VERSION "dbc-export 1 2025.20.8"

NS_ :

BS_:

BU_: BB BMS GTW IDB PM TCU UI UIS

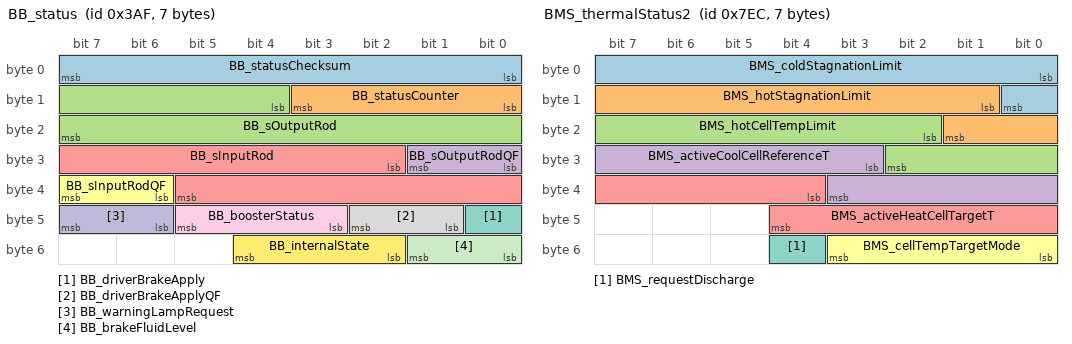
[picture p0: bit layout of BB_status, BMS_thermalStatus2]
BO_ 943 BB_status: 7 BB
 SG_ BB_statusChecksum : 0|8@1+ (1,0) [0|255] "" Vector__XXX
 SG_ BB_statusCounter : 8|4@1+ (1,0) [0|15] "" Vector__XXX
 SG_ BB_sOutputRod : 12|12@1+ (0.015625,-5) [-5|47] "mm" Vector__XXX
 SG_ BB_sOutputRodQF : 24|2@1+ (1,0) [0|3] "" Vector__XXX
 SG_ BB_sInputRod : 26|12@1+ (0.015625,-5) [-5|47] "mm" Vector__XXX
 SG_ BB_sInputRodQF : 38|2@1+ (1,0) [0|3] "" Vector__XXX
 SG_ BB_driverBrakeApply : 40|1@1+ (1,0) [0|1] "" Vector__XXX
 SG_ BB_driverBrakeApplyQF : 41|2@1+ (1,0) [0|3] "" Vector__XXX
 SG_ BB_boosterStatus : 43|3@1+ (1,0) [0|7] "" Vector__XXX
 SG_ BB_warningLampRequest : 46|2@1+ (1,0) [0|3] "" Vector__XXX
 SG_ BB_brakeFluidLevel : 48|2@1+ (1,0) [0|3] "" Vector__XXX
 SG_ BB_internalState : 50|3@1+ (1,0) [0|7] "" Vector__XXX

BO_ 2029 BMS_debugInfo_10Hz: 8 BMS
 SG_ BMS_10HzDebug_Id M : 0|6@1+ (1,0) [0|63] "" Vector__XXX
 SG_ BMS_activeCoolCellTargetT m33 : 6|9@1+ (0.25,-25) [-25|100] "DegC" Vector__XXX
 SG_ BMS_passiveCoolCellTargetT m33 : 15|9@1+ (0.25,-25) [-25|100] "DegC" Vector__XXX

BO_ 2028 BMS_thermalStatus2: 7 BMS
 SG_ BMS_coldStagnationLimit : 0|9@1+ (0.25,-25) [-25|100] "DegC" Vector__XXX
 SG_ BMS_hotStagnationLimit : 9|9@1+ (0.25,-25) [-25|100] "DegC" Vector__XXX
 SG_ BMS_hotCellTempLimit : 18|9@1+ (0.25,-25) [-25|100] "DegC" Vector__XXX
 SG_ BMS_activeCoolCellReferenceT : 27|9@1+ (0.25,-25) [-25|100] "DegC" Vector__XXX
 SG_ BMS_activeHeatCellTargetT : 36|9@1+ (0.25,-25) [-25|100] "DegC" Vector__XXX
 SG_ BMS_cellTempTargetMode : 48|4@1+ (1,0) [0|15] "" Vector__XXX
 SG_ BMS_requestDischarge : 52|1@1+ (1,0) [0|1] "" Vector__XXX

BO_ 888 GTW_ECall: 1 GTW
 SG_ GTW_GTW_SOS_ECALL_RQST : 0|1@1+ (1,0) [0|1] "" Vector__XXX
 SG_ GTW_LTE_ECALL_LOCK : 1|1@1+ (1,0) [0|1] "" Vector__XXX

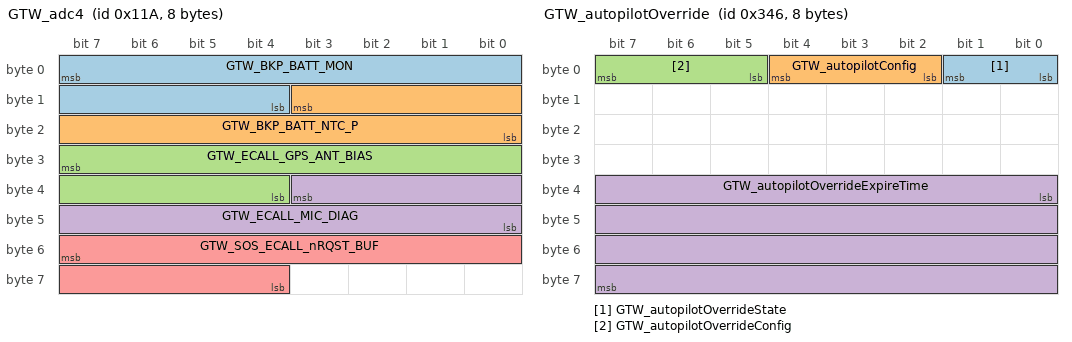
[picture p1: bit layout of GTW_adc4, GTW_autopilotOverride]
BO_ 282 GTW_adc4: 8 GTW
 SG_ GTW_BKP_BATT_MON : 7|12@0+ (1,0) [0|4094] "mV" Vector__XXX
 SG_ GTW_BKP_BATT_NTC_P : 11|12@0+ (1,0) [0|4094] "mV" Vector__XXX
 SG_ GTW_ECALL_GPS_ANT_BIAS : 31|12@0+ (1,0) [0|4094] "mV" Vector__XXX
 SG_ GTW_ECALL_MIC_DIAG : 35|12@0+ (1,0) [0|4094] "mV" Vector__XXX
 SG_ GTW_SOS_ECALL_nRQST_BUF : 55|12@0+ (1,0) [0|4094] "mV" Vector__XXX

BO_ 838 GTW_autopilotOverride: 8 GTW
 SG_ GTW_autopilotOverrideState : 0|2@1+ (1,0) [0|3] "" Vector__XXX
 SG_ GTW_autopilotConfig : 2|3@1+ (1,0) [0|7] "" Vector__XXX
 SG_ GTW_autopilotOverrideConfig : 5|3@1+ (1,0) [0|7] "" Vector__XXX
 SG_ GTW_autopilotOverrideExpireTime : 32|32@1+ (1,0) [0|4294967295] "" Vector__XXX

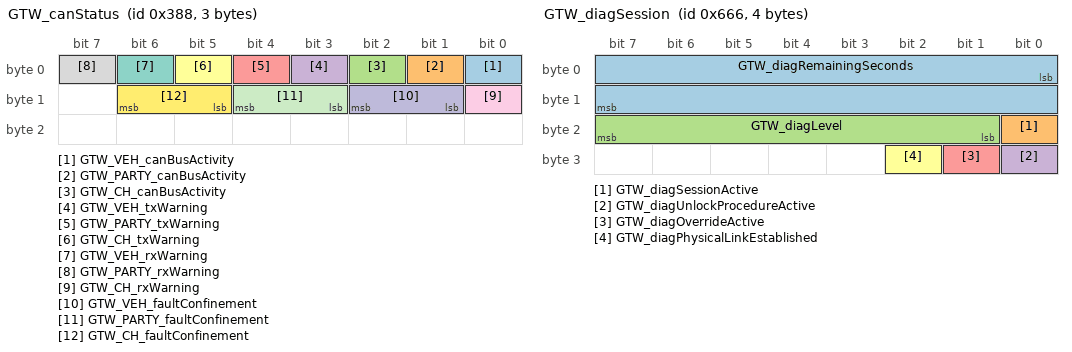
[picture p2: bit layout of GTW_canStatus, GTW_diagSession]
BO_ 904 GTW_canStatus: 3 GTW
 SG_ GTW_VEH_canBusActivity : 0|1@1+ (1,0) [0|1] "" Vector__XXX
 SG_ GTW_PARTY_canBusActivity : 1|1@1+ (1,0) [0|1] "" Vector__XXX
 SG_ GTW_CH_canBusActivity : 2|1@1+ (1,0) [0|1] "" Vector__XXX
 SG_ GTW_VEH_txWarning : 3|1@1+ (1,0) [0|1] "" Vector__XXX
 SG_ GTW_PARTY_txWarning : 4|1@1+ (1,0) [0|1] "" Vector__XXX
 SG_ GTW_CH_txWarning : 5|1@1+ (1,0) [0|1] "" Vector__XXX
 SG_ GTW_VEH_rxWarning : 6|1@1+ (1,0) [0|1] "" Vector__XXX
 SG_ GTW_PARTY_rxWarning : 7|1@1+ (1,0) [0|1] "" Vector__XXX
 SG_ GTW_CH_rxWarning : 8|1@1+ (1,0) [0|1] "" Vector__XXX
 SG_ GTW_VEH_faultConfinement : 9|2@1+ (1,0) [0|3] "" Vector__XXX
 SG_ GTW_PARTY_faultConfinement : 11|2@1+ (1,0) [0|3] "" Vector__XXX
 SG_ GTW_CH_faultConfinement : 13|2@1+ (1,0) [0|3] "" Vector__XXX

BO_ 2047 GTW_carConfig: 8 GTW
 SG_ GTW_carConfigMultiplexer M : 0|8@1+ (1,0) [0|255] "" Vector__XXX
 SG_ GTW_deliveryStatus m1 : 8|1@1+ (1,0) [0|1] "" Vector__XXX
 SG_ GTW_cabinPTCHeaterType m1 : 10|1@1+ (1,0) [0|1] "" Vector__XXX
 SG_ GTW_rightHandDrive m1 : 11|1@1+ (1,0) [0|1] "" Vector__XXX
 SG_ GTW_rearLightType m1 : 12|2@1+ (1,0) [0|3] "" Vector__XXX
 SG_ GTW_headlamps m1 : 14|2@1+ (1,0) [0|3] "" Vector__XXX
 SG_ GTW_country m1 : 16|16@1+ (1,0) [0|65535] "" Vector__XXX
 SG_ GTW_tireType m1 : 32|6@1+ (1,0) [0|63] "" Vector__XXX
 SG_ GTW_roofGlassType m1 : 38|2@1+ (1,0) [0|3] "" Vector__XXX
 SG_ GTW_dasHw m1 : 40|3@1+ (1,0) [3|5] "" Vector__XXX
 SG_ GTW_brakeHWType m1 : 43|5@1+ (1,0) [0|31] "" Vector__XXX
 SG_ GTW_restraintsHardwareType m1 : 48|8@1+ (1,0) [0|255] "" Vector__XXX
 SG_ GTW_drivetrainType m1 : 56|4@1+ (1,0) [0|4] "" Vector__XXX
 SG_ GTW_radarHeaterType m1 : 60|3@1+ (1,0) [0|5] "" Vector__XXX
 SG_ GTW_exteriorTrimType m2 : 8|1@1+ (1,0) [0|1] "" Vector__XXX
 SG_ GTW_frontSeatHeaters m2 : 9|1@1+ (1,0) [0|1] "" Vector__XXX
 SG_ GTW_rearSeatHeaters m2 : 10|1@1+ (1,0) [0|1] "" Vector__XXX
 SG_ GTW_eCallAntennaHW m2 : 12|1@1+ (1,0) [0|1] "" Vector__XXX
 SG_ GTW_homelinkType m2 : 13|1@1+ (1,0) [0|1] "" Vector__XXX
 SG_ GTW_vdcType m2 : 14|1@1+ (1,0) [0|1] "" Vector__XXX
 SG_ GTW_memoryMirrors m2 : 17|1@1+ (1,0) [0|1] "" Vector__XXX
 SG_ GTW_powerLiftgateType m2 : 18|2@1+ (1,0) [0|2] "" Vector__XXX
 SG_ GTW_lumbarECUType m2 : 20|4@1+ (1,0) [0|15] "" Vector__XXX
 SG_ GTW_rearSeatHeaterType m2 : 24|2@1+ (1,0) [0|3] "" Vector__XXX
 SG_ GTW_auxParkLamps m2 : 26|2@1+ (1,0) [0|3] "" Vector__XXX
 SG_ GTW_interiorCabinRadarType m2 : 28|1@1+ (1,0) [0|1] "" Vector__XXX
 SG_ GTW_hvacPanelVaneType m2 : 29|1@1+ (1,0) [0|1] "" Vector__XXX
 SG_ GTW_intakeAirFilterType m2 : 30|2@1+ (1,0) [0|2] "" Vector__XXX
 SG_ GTW_eBuckConfig m2 : 32|1@1+ (1,0) [0|1] "" Vector__XXX
 SG_ GTW_steeringHeaterEnabled m2 : 33|1@1+ (1,0) [0|1] "" Vector__XXX
 SG_ GTW_activeHighBeam m2 : 34|1@1+ (1,0) [0|1] "" Vector__XXX
 SG_ GTW_airbagCutoffSwitch m2 : 35|1@1+ (1,0) [0|1] "" Vector__XXX
 SG_ GTW_intrusionSensorType m2 : 36|1@1+ (1,0) [0|1] "" Vector__XXX
 SG_ GTW_spoilerType m2 : 37|1@1+ (1,0) [0|1] "" Vector__XXX
 SG_ GTW_rearFogLamps m2 : 39|1@1+ (1,0) [0|1] "" Vector__XXX
 SG_ GTW_roofType m2 : 40|1@1+ (1,0) [0|1] "" Vector__XXX
 SG_ GTW_thirdRowSeatType m2 : 41|1@1+ (1,0) [0|1] "" Vector__XXX
 SG_ GTW_autopilot m2 : 42|3@1+ (1,0) [0|7] "" Vector__XXX
 SG_ GTW_superchargingAccess m2 : 45|2@1+ (1,0) [0|3] "" Vector__XXX
 SG_ GTW_exteriorColor m2 : 48|5@1+ (1,0) [0|31] "" Vector__XXX
 SG_ GTW_pedestrianWarningSound m2 : 53|2@1+ (1,0) [0|3] "" Vector__XXX
 SG_ GTW_steeringColumnUJointType m2 : 55|1@1+ (1,0) [0|1] "" Vector__XXX
 SG_ GTW_bPillarNFCParam m2 : 56|1@1+ (1,0) [0|1] "" Vector__XXX
 SG_ GTW_interiorLighting m2 : 57|3@1+ (1,0) [0|7] "" Vector__XXX
 SG_ GTW_headlightLevelerType m2 : 60|2@1+ (1,0) [0|3] "" Vector__XXX
 SG_ GTW_numberHVILNodes m2 : 62|2@1+ (1,0) [0|3] "" Vector__XXX
 SG_ GTW_mapRegion m3 : 8|4@1+ (1,0) [0|15] "" Vector__XXX
 SG_ GTW_performancePackage m3 : 12|3@1+ (1,0) [0|7] "" Vector__XXX
 SG_ GTW_chassisType m3 : 18|4@1+ (1,0) [0|15] "" Vector__XXX
 SG_ GTW_airSuspension m3 : 22|2@1+ (1,0) [0|3] "" Vector__XXX
 SG_ GTW_centerConsoleControllerType m3 : 24|2@1+ (1,0) [0|3] "" Vector__XXX
 SG_ GTW_autopilotCameraType m3 : 26|1@1+ (1,0) [0|1] "" Vector__XXX
 SG_ GTW_connectivityPackage m3 : 27|1@1+ (1,0) [0|1] "" Vector__XXX
 SG_ GTW_plcSupportType m3 : 28|2@1+ (1,0) [0|3] "" Vector__XXX
 SG_ GTW_packEnergy m3 : 32|5@1+ (1,0) [0|31] "" Vector__XXX
 SG_ GTW_frontSeatReclinerHardware m3 : 37|2@1+ (1,0) [0|3] "" Vector__XXX
 SG_ GTW_brakeLineSwitchType m3 : 39|1@1+ (1,0) [0|1] "" Vector__XXX
 SG_ GTW_softRange m3 : 42|3@1+ (1,0) [0|7] "" Vector__XXX
 SG_ GTW_refrigerantType m3 : 45|2@1+ (1,0) [0|3] "" Vector__XXX
 SG_ GTW_wheelType m3 : 48|7@1+ (1,0) [0|127] "" Vector__XXX
 SG_ GTW_brakeActuationType m3 : 57|3@1+ (1,0) [0|4] "" Vector__XXX
 SG_ GTW_secondRowSeatType m3 : 60|3@1+ (1,0) [0|7] "" Vector__XXX
 SG_ GTW_secondRowSeatMotorType m3 : 63|1@1+ (1,0) [0|1] "" Vector__XXX
 SG_ GTW_birthday m4 : 8|32@1+ (1,0) [0|4294967295] "" Vector__XXX
 SG_ GTW_eCallEnabled m4 : 40|2@1+ (1,0) [0|3] "" Vector__XXX
 SG_ GTW_parkAssistECUType m4 : 42|2@1+ (1,0) [0|3] "" Vector__XXX
 SG_ GTW_passengerAirbagType m4 : 44|2@1+ (1,0) [0|3] "" Vector__XXX
 SG_ GTW_forwardRadarHw m4 : 46|2@1+ (1,0) [0|2] "" Vector__XXX
 SG_ GTW_frontSeatType m4 : 48|4@1+ (1,0) [0|15] "" Vector__XXX
 SG_ GTW_secondRowDisplayType m4 : 52|1@1+ (1,0) [0|1] "" Vector__XXX
 SG_ GTW_wirelessPhoneChargerType m4 : 53|2@1+ (1,0) [0|3] "" Vector__XXX
 SG_ GTW_ethernetTunerType m4 : 55|2@1+ (1,0) [0|3] "" Vector__XXX
 SG_ GTW_interiorTrimType m4 : 60|4@1+ (1,0) [0|15] "" Vector__XXX
 SG_ GTW_gloveboxUSBType m5 : 8|2@1+ (1,0) [0|3] "" Vector__XXX
 SG_ GTW_coolantPumpType m5 : 10|3@1+ (1,0) [0|7] "" Vector__XXX
 SG_ GTW_epblHwType m5 : 13|4@1+ (1,0) [0|15] "" Vector__XXX
 SG_ GTW_epbrHwType m5 : 17|4@1+ (1,0) [0|15] "" Vector__XXX
 SG_ GTW_blowerMotorType m5 : 21|2@1+ (1,0) [0|3] "" Vector__XXX
 SG_ GTW_frontUsbHubType m5 : 27|3@1+ (1,0) [0|5] "" Vector__XXX
 SG_ GTW_superManifoldType m5 : 30|2@1+ (1,0) [0|3] "" Vector__XXX
 SG_ GTW_rcmLocation m5 : 32|1@1+ (1,0) [0|1] "" Vector__XXX
 SG_ GTW_interiorCamFanType m5 : 33|2@1+ (1,0) [0|3] "" Vector__XXX
 SG_ GTW_sirenType m5 : 37|1@1+ (1,0) [0|1] "" Vector__XXX
 SG_ GTW_hornType m5 : 38|1@1+ (1,0) [0|1] "" Vector__XXX
 SG_ GTW_badgingVersion m5 : 40|1@1+ (1,0) [0|1] "" Vector__XXX
 SG_ GTW_steeringColumnMotorType m5 : 42|2@1+ (1,0) [0|3] "" Vector__XXX
 SG_ GTW_refrigACLineType m5 : 48|2@1+ (1,0) [0|3] "" Vector__XXX
 SG_ GTW_refrigFilterType m5 : 50|2@1+ (1,0) [0|3] "" Vector__XXX
 SG_ GTW_diBurnInType m5 : 52|1@1+ (1,0) [0|1] "" Vector__XXX
 SG_ GTW_specialBadgingType m5 : 53|2@1+ (1,0) [0|3] "" Vector__XXX
 SG_ GTW_chassisSubType m5 : 55|2@1+ (1,0) [0|3] "" Vector__XXX
 SG_ GTW_frontSeatVentilationType m5 : 57|1@1+ (1,0) [0|1] "" Vector__XXX
 SG_ GTW_towPackage m5 : 58|2@1+ (1,0) [0|3] "" Vector__XXX
 SG_ GTW_refrigLccType m5 : 60|1@1+ (1,0) [0|1] "" Vector__XXX
 SG_ GTW_caliperColorType m5 : 62|2@1+ (1,0) [0|3] "" Vector__XXX
 SG_ GTW_wiperMotorType m6 : 9|1@1+ (1,0) [0|1] "" Vector__XXX
 SG_ GTW_frontOverheadConsoleType m6 : 10|2@1+ (1,0) [0|3] "" Vector__XXX
 SG_ GTW_shifterType m6 : 12|1@1+ (1,0) [0|1] "" Vector__XXX
 SG_ GTW_compressorType m6 : 13|4@1+ (1,0) [0|15] "" Vector__XXX
 SG_ GTW_twelveVBatteryType m6 : 17|3@1+ (1,0) [0|7] "" Vector__XXX
 SG_ GTW_efuseSWConfig m6 : 20|3@1+ (1,0) [0|7] "" Vector__XXX
 SG_ GTW_tollCollectionModuleType m6 : 23|1@1+ (1,0) [0|1] "" Vector__XXX
 SG_ GTW_bleEndpointUpdateMethod m6 : 24|1@1+ (1,0) [0|1] "" Vector__XXX
 SG_ GTW_steeringWheelControllerType m6 : 25|3@1+ (1,0) [0|7] "" Vector__XXX
 SG_ GTW_frontSeatVentilationEnabled m6 : 28|1@1+ (1,0) [0|1] "" Vector__XXX
 SG_ GTW_gloveboxActuatorType m6 : 29|2@1+ (1,0) [0|3] "" Vector__XXX
 SG_ GTW_epasType m6 : 32|4@1+ (1,0) [0|11] "" Vector__XXX
 SG_ GTW_homologationRegionOverride m6 : 36|2@1+ (1,0) [0|3] "" Vector__XXX
 SG_ GTW_windowCommandsPermissionType m6 : 38|2@1+ (1,0) [0|3] "" Vector__XXX
 SG_ GTW_rgbInteriorLightingEnabled m6 : 43|2@1+ (1,0) [0|3] "" Vector__XXX
 SG_ GTW_windshieldWiperHeaterType m6 : 45|1@1+ (1,0) [0|1] "" Vector__XXX
 SG_ GTW_driveInterfaceType m6 : 47|1@1+ (1,0) [0|1] "" Vector__XXX
 SG_ GTW_efficiencyPackage m6 : 49|6@1+ (1,0) [0|63] "" Vector__XXX
 SG_ GTW_visorLightType m6 : 55|1@1+ (1,0) [0|1] "" Vector__XXX
 SG_ GTW_gnssAntennaType m6 : 58|2@1+ (1,0) [0|3] "" Vector__XXX
 SG_ GTW_frontSeatHeatersEnabled m6 : 62|1@1+ (1,0) [0|1] "" Vector__XXX
 SG_ GTW_windshieldWiperHeaterEnabled m6 : 63|1@1+ (1,0) [0|1] "" Vector__XXX
 SG_ GTW_tcuType m7 : 8|1@1+ (1,0) [0|1] "" Vector__XXX
 SG_ GTW_fasciaType m7 : 9|4@1+ (1,0) [0|15] "" Vector__XXX
 SG_ GTW_powerSteeringColumn m7 : 13|1@1+ (1,0) [0|1] "" Vector__XXX
 SG_ GTW_frontSeatHeaterType m7 : 14|1@1+ (1,0) [0|1] "" Vector__XXX
 SG_ GTW_softPerformanceLimit m7 : 15|4@1+ (1,0) [0|15] "" Vector__XXX
 SG_ GTW_alcoholInterlockType m7 : 22|1@1+ (1,0) [0|1] "" Vector__XXX
 SG_ GTW_immersiveAudio m7 : 23|2@1+ (1,0) [0|3] "" Vector__XXX
 SG_ GTW_passengerOccupancySensorType m7 : 26|3@1+ (1,0) [0|7] "" Vector__XXX
 SG_ GTW_packPerformanceDeviation m7 : 30|3@1+ (1,0) [0|7] "" Vector__XXX
 SG_ GTW_frontFogLamps m7 : 35|1@1+ (1,0) [0|1] "" Vector__XXX
 SG_ GTW_driverOccupancySensorType m7 : 36|1@1+ (1,0) [0|1] "" Vector__XXX
 SG_ GTW_audioType m7 : 37|3@1+ (1,0) [0|7] "" Vector__XXX
 SG_ GTW_occupancyClassificationFeatu m7 : 42|1@1+ (1,0) [0|1] "" Vector__XXX
 SG_ GTW_domeLightType m7 : 47|2@1+ (1,0) [0|3] "" Vector__XXX
 SG_ GTW_tpmsType m7 : 49|2@1+ (1,0) [0|3] "" Vector__XXX
 SG_ GTW_authenticationEndpointLayout m7 : 52|3@1+ (1,0) [0|6] "" Vector__XXX
 SG_ GTW_socSleepOverride m7 : 57|2@1+ (1,0) [0|3] "" Vector__XXX
 SG_ GTW_r79BehaviorOverride m7 : 59|1@1+ (1,0) [0|1] "" Vector__XXX
 SG_ GTW_steeringHeaterType m7 : 60|3@1+ (1,0) [0|7] "" Vector__XXX
 SG_ GTW_sohRegulatoryStatus m8 : 10|1@1+ (1,0) [0|1] "" Vector__XXX
 SG_ GTW_m3yBusArchitecture m8 : 17|2@1+ (1,0) [0|3] "" Vector__XXX
 SG_ GTW_blindSpotIndicatorLightType m8 : 20|1@1+ (1,0) [0|1] "" Vector__XXX
 SG_ GTW_hvacCaseDoorType m8 : 28|1@1+ (1,0) [0|1] "" Vector__XXX
 SG_ GTW_rduCableType m8 : 31|1@1+ (1,0) [0|1] "" Vector__XXX
 SG_ GTW_interiorCameraType m8 : 39|2@1+ (1,0) [0|2] "" Vector__XXX
 SG_ GTW_frontFasciaCameraType m8 : 41|2@1+ (1,0) [0|3] "" Vector__XXX

BO_ 1638 GTW_diagSession: 4 GTW
 SG_ GTW_diagRemainingSeconds : 0|16@1+ (1,0) [0|65535] "seconds" Vector__XXX
 SG_ GTW_diagSessionActive : 16|1@1+ (1,0) [0|1] "" Vector__XXX
 SG_ GTW_diagLevel : 17|7@1+ (1,0) [0|127] "" Vector__XXX
 SG_ GTW_diagUnlockProcedureActive : 24|1@1+ (1,0) [0|1] "" Vector__XXX
 SG_ GTW_diagOverrideActive : 25|1@1+ (1,0) [0|1] "" Vector__XXX
 SG_ GTW_diagPhysicalLinkEstablished : 26|1@1+ (1,0) [0|1] "" Vector__XXX

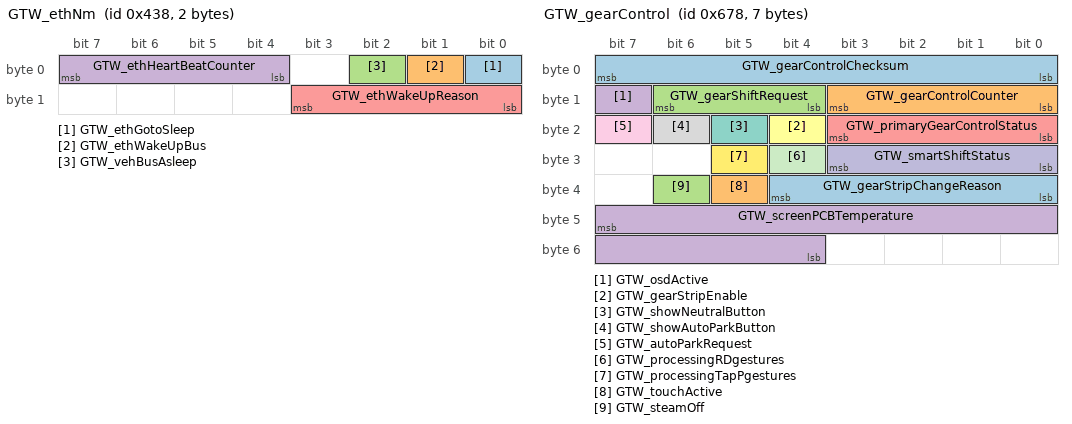
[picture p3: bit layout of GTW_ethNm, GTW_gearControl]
BO_ 1080 GTW_ethNm: 2 GTW
 SG_ GTW_ethGotoSleep : 0|1@1+ (1,0) [0|1] "" Vector__XXX
 SG_ GTW_ethWakeUpBus : 1|1@1+ (1,0) [0|1] "" Vector__XXX
 SG_ GTW_vehBusAsleep : 2|1@1+ (1,0) [0|1] "" Vector__XXX
 SG_ GTW_ethHeartBeatCounter : 4|4@1+ (1,0) [0|15] "" Vector__XXX
 SG_ GTW_ethWakeUpReason : 8|4@1+ (1,0) [0|15] "" Vector__XXX

BO_ 1656 GTW_gearControl: 7 GTW
 SG_ GTW_gearControlChecksum : 0|8@1+ (1,0) [0|255] "" Vector__XXX
 SG_ GTW_gearControlCounter : 8|4@1+ (1,0) [0|15] "" Vector__XXX
 SG_ GTW_gearShiftRequest : 12|3@1+ (1,0) [1|7] "" Vector__XXX
 SG_ GTW_osdActive : 15|1@1+ (1,0) [0|1] "" Vector__XXX
 SG_ GTW_primaryGearControlStatus : 16|4@1+ (1,0) [0|15] "" Vector__XXX
 SG_ GTW_gearStripEnable : 20|1@1+ (1,0) [0|1] "" Vector__XXX
 SG_ GTW_showNeutralButton : 21|1@1+ (1,0) [0|1] "" Vector__XXX
 SG_ GTW_showAutoParkButton : 22|1@1+ (1,0) [0|1] "" Vector__XXX
 SG_ GTW_autoParkRequest : 23|1@1+ (1,0) [0|1] "" Vector__XXX
 SG_ GTW_smartShiftStatus : 24|4@1+ (1,0) [1|15] "" Vector__XXX
 SG_ GTW_processingRDgestures : 28|1@1+ (1,0) [0|1] "" Vector__XXX
 SG_ GTW_processingTapPgestures : 29|1@1+ (1,0) [0|1] "" Vector__XXX
 SG_ GTW_gearStripChangeReason : 32|5@1+ (1,0) [1|31] "" Vector__XXX
 SG_ GTW_touchActive : 37|1@1+ (1,0) [0|1] "" Vector__XXX
 SG_ GTW_steamOff : 38|1@1+ (1,0) [0|1] "" Vector__XXX
 SG_ GTW_screenPCBTemperature : 47|12@0- (0.0625,0) [-128|127.875] "degC" Vector__XXX

BO_ 2033 GTW_hrl: 7 GTW
 SG_ GTW_hrlIndex M : 0|2@1+ (1,0) [0|3] "" Vector__XXX
 SG_ GTW_hrlState m2 : 2|1@1+ (1,0) [0|1] "" Vector__XXX
 SG_ GTW_hrlTriggerDuration m2 : 15|16@0+ (1,0) [0|65535] "seconds" Vector__XXX
 SG_ GTW_hrlTriggerType m2 : 24|4@1+ (1,0) [0|15] "" Vector__XXX
 SG_ GTW_hrlTriggerId m2 : 39|16@0+ (1,0) [0|65535] "" Vector__XXX
 SG_ GTW_hrlTriggerBus m2 : 53|3@1+ (1,0) [0|7] "" Vector__XXX

BO_ 60 GTW_info: 8 GTW
 SG_ GTW_infoIndex M : 0|8@1+ (1,0) [0|255] "" Vector__XXX
 SG_ GTW_buildType m10 : 8|3@1+ (1,0) [0|7] "" Vector__XXX
 SG_ GTW_hardwareId m10 : 32|16@1+ (1,0) [0|65535] "" Vector__XXX
 SG_ GTW_platformType m13 : 8|8@1+ (1,0) [0|255] "" Vector__XXX
 SG_ GTW_appCrc m13 : 32|32@1+ (1,0) [0|4294967295] "" Vector__XXX
 SG_ GTW_applicationGitHash m17 : 8|56@1+ (1,0) [0|7.20575940379e+16] "" Vector__XXX
 SG_ GTW_bootGitHash m18 : 8|56@1+ (1,0) [0|7.20575940379e+16] "" Vector__XXX

BO_ 1370 GTW_mismatchFault: 8 GTW
 SG_ GTW_mismatchFaultIndex M : 0|3@1+ (1,0) [0|7] "" Vector__XXX
 SG_ GTW_mismatchFaultChecksum : 3|8@1+ (1,0) [0|255] "" Vector__XXX
 SG_ GTW_mismatchFaultCounter : 11|4@1+ (1,0) [0|15] "" Vector__XXX
 SG_ GTW_GTWmismatchFault m1 : 15|1@1+ (1,0) [0|1] "" Vector__XXX
 SG_ GTW_BMSmismatchFault m1 : 16|1@1+ (1,0) [0|1] "" Vector__XXX
 SG_ GTW_APSmismatchFault m1 : 17|1@1+ (1,0) [0|1] "" Vector__XXX
 SG_ GTW_BLEEPCENTERmismatchFault m1 : 18|1@1+ (1,0) [0|1] "" Vector__XXX
 SG_ GTW_BLEEPLEFTmismatchFault m1 : 19|1@1+ (1,0) [0|1] "" Vector__XXX
 SG_ GTW_BLEEPREARmismatchFault m1 : 20|1@1+ (1,0) [0|1] "" Vector__XXX
 SG_ GTW_BLEEPRIGHTmismatchFault m1 : 21|1@1+ (1,0) [0|1] "" Vector__XXX
 SG_ GTW_CBCmismatchFault m1 : 22|1@1+ (1,0) [0|1] "" Vector__XXX
 SG_ GTW_CMPmismatchFault m1 : 23|1@1+ (1,0) [0|1] "" Vector__XXX
 SG_ GTW_CPmismatchFault m1 : 24|1@1+ (1,0) [0|1] "" Vector__XXX
 SG_ GTW_DIFmismatchFault m1 : 25|1@1+ (1,0) [0|1] "" Vector__XXX
 SG_ GTW_DIRmismatchFault m1 : 26|1@1+ (1,0) [0|1] "" Vector__XXX
 SG_ GTW_EPAS3PmismatchFault m1 : 27|1@1+ (1,0) [0|1] "" Vector__XXX
 SG_ GTW_EPAS3SmismatchFault m1 : 28|1@1+ (1,0) [0|1] "" Vector__XXX
 SG_ GTW_EPBLmismatchFault m1 : 29|1@1+ (1,0) [0|1] "" Vector__XXX
 SG_ GTW_EPBRmismatchFault m1 : 30|1@1+ (1,0) [0|1] "" Vector__XXX
 SG_ GTW_ESPCALmismatchFault m1 : 31|1@1+ (1,0) [0|1] "" Vector__XXX
 SG_ GTW_ESPmismatchFault m1 : 32|1@1+ (1,0) [0|1] "" Vector__XXX
 SG_ GTW_HCM3LmismatchFault m1 : 33|1@1+ (1,0) [0|1] "" Vector__XXX
 SG_ GTW_HCM3RmismatchFault m1 : 34|1@1+ (1,0) [0|1] "" Vector__XXX
 SG_ GTW_HCMLmismatchFault m1 : 35|1@1+ (1,0) [0|1] "" Vector__XXX
 SG_ GTW_HCMRmismatchFault m1 : 36|1@1+ (1,0) [0|1] "" Vector__XXX
 SG_ GTW_HVPmismatchFault m1 : 37|1@1+ (1,0) [0|1] "" Vector__XXX
 SG_ GTW_IBSTCALmismatchFault m1 : 38|1@1+ (1,0) [0|1] "" Vector__XXX
 SG_ GTW_IBSTmismatchFault m1 : 39|1@1+ (1,0) [0|1] "" Vector__XXX
 SG_ GTW_LVBMSmismatchFault m1 : 40|1@1+ (1,0) [0|1] "" Vector__XXX
 SG_ GTW_OCS1PmismatchFault m1 : 41|1@1+ (1,0) [0|1] "" Vector__XXX
 SG_ GTW_OPCFmismatchFault m1 : 42|1@1+ (1,0) [0|1] "" Vector__XXX
 SG_ GTW_OPCRmismatchFault m1 : 43|1@1+ (1,0) [0|1] "" Vector__XXX
 SG_ GTW_PARKmismatchFault m1 : 44|1@1+ (1,0) [0|1] "" Vector__XXX
 SG_ GTW_PCSCPU2mismatchFault m1 : 45|1@1+ (1,0) [0|1] "" Vector__XXX
 SG_ GTW_PCSmismatchFault m1 : 46|1@1+ (1,0) [0|1] "" Vector__XXX
 SG_ GTW_PMFmismatchFault m1 : 47|1@1+ (1,0) [0|1] "" Vector__XXX
 SG_ GTW_PMRmismatchFault m1 : 48|1@1+ (1,0) [0|1] "" Vector__XXX
 SG_ GTW_PTCmismatchFault m1 : 49|1@1+ (1,0) [0|1] "" Vector__XXX
 SG_ GTW_RCMCALmismatchFault m1 : 50|1@1+ (1,0) [0|1] "" Vector__XXX
 SG_ GTW_RCMmismatchFault m1 : 51|1@1+ (1,0) [0|1] "" Vector__XXX
 SG_ GTW_SCCMmismatchFault m1 : 52|1@1+ (1,0) [0|1] "" Vector__XXX
 SG_ GTW_SDCRmismatchFault m1 : 53|1@1+ (1,0) [0|1] "" Vector__XXX
 SG_ GTW_SWCmismatchFault m1 : 54|1@1+ (1,0) [0|1] "" Vector__XXX
 SG_ GTW_THSmismatchFault m1 : 55|1@1+ (1,0) [0|1] "" Vector__XXX
 SG_ GTW_VCFRONTmismatchFault m1 : 56|1@1+ (1,0) [0|1] "" Vector__XXX
 SG_ GTW_VCLEFTmismatchFault m1 : 57|1@1+ (1,0) [0|1] "" Vector__XXX
 SG_ GTW_VCRIGHTmismatchFault m1 : 58|1@1+ (1,0) [0|1] "" Vector__XXX
 SG_ GTW_VCSECmismatchFault m1 : 59|1@1+ (1,0) [0|1] "" Vector__XXX
 SG_ GTW_PMmismatchFault m1 : 60|1@1+ (1,0) [0|1] "" Vector__XXX

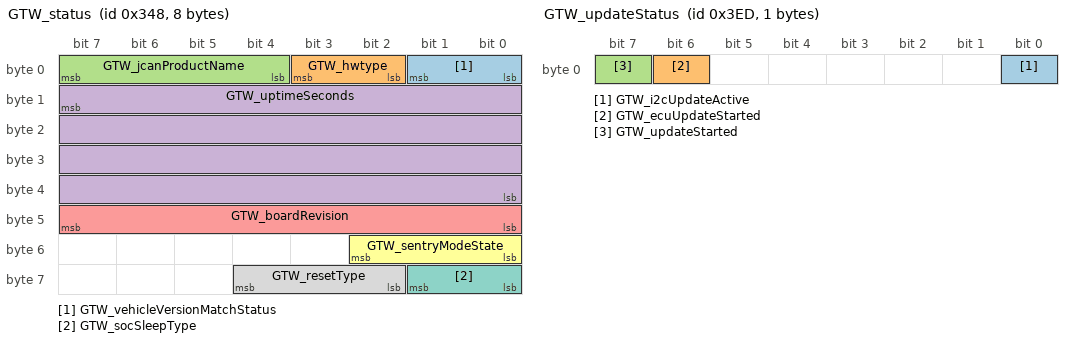
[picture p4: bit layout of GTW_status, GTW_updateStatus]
BO_ 840 GTW_status: 8 GTW
 SG_ GTW_vehicleVersionMatchStatus : 0|2@1+ (1,0) [0|3] "" Vector__XXX
 SG_ GTW_hwtype : 2|2@1+ (1,0) [1|3] "" Vector__XXX
 SG_ GTW_jcanProductName : 4|4@1+ (1,0) [1|15] "" Vector__XXX
 SG_ GTW_uptimeSeconds : 15|32@0+ (1,0) [0|4294967295] "s" Vector__XXX
 SG_ GTW_boardRevision : 40|8@1+ (1,0) [0|255] "" Vector__XXX
 SG_ GTW_sentryModeState : 48|3@1+ (1,0) [0|7] "" Vector__XXX
 SG_ GTW_socSleepType : 56|2@1+ (1,0) [1|3] "" Vector__XXX
 SG_ GTW_resetType : 58|3@1+ (1,0) [1|7] "" Vector__XXX

BO_ 1005 GTW_updateStatus: 1 GTW
 SG_ GTW_i2cUpdateActive : 0|1@1+ (1,0) [0|1] "" Vector__XXX
 SG_ GTW_ecuUpdateStarted : 6|1@1+ (1,0) [0|1] "" Vector__XXX
 SG_ GTW_updateStarted : 7|1@1+ (1,0) [0|1] "" Vector__XXX

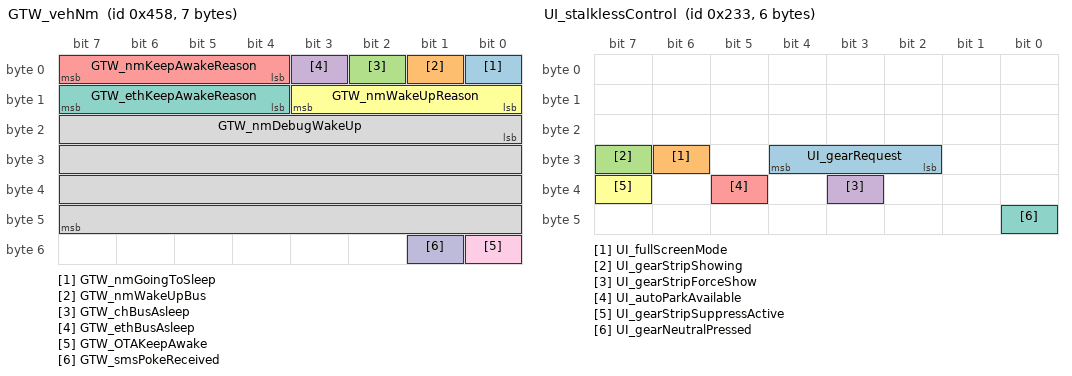
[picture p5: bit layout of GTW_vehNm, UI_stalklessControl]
BO_ 1112 GTW_vehNm: 7 GTW
 SG_ GTW_nmGoingToSleep : 0|1@1+ (1,0) [0|1] "" Vector__XXX
 SG_ GTW_nmWakeUpBus : 1|1@1+ (1,0) [0|1] "" Vector__XXX
 SG_ GTW_chBusAsleep : 2|1@1+ (1,0) [0|1] "" Vector__XXX
 SG_ GTW_ethBusAsleep : 3|1@1+ (1,0) [0|1] "" Vector__XXX
 SG_ GTW_nmKeepAwakeReason : 4|4@1+ (1,0) [1|15] "" Vector__XXX
 SG_ GTW_nmWakeUpReason : 8|4@1+ (1,0) [0|15] "" Vector__XXX
 SG_ GTW_ethKeepAwakeReason : 12|4@1+ (1,0) [1|15] "" Vector__XXX
 SG_ GTW_nmDebugWakeUp : 16|32@1+ (1,0) [0|4294967295] "" Vector__XXX
 SG_ GTW_OTAKeepAwake : 48|1@1+ (1,0) [0|1] "" Vector__XXX
 SG_ GTW_smsPokeReceived : 49|1@1+ (1,0) [0|1] "" Vector__XXX

BO_ 828 IDB_info: 8 IDB
 SG_ IDB_infoIndex M : 0|8@1+ (1,0) [0|255] "" Vector__XXX
 SG_ IDB_infoPcbaID m11 : 16|8@1+ (1,0) [0|255] "" Vector__XXX
 SG_ IDB_infoAssemblyID m11 : 24|8@1+ (1,0) [0|255] "" Vector__XXX
 SG_ IDB_infoUsageID m11 : 32|16@1+ (1,0) [0|65535] "" Vector__XXX
 SG_ IDB_infoSubUsageID m11 : 48|16@1+ (1,0) [0|65535] "" Vector__XXX

BO_ 463 PM_systemState: 8 PM
 SG_ PM_hvilSystemStatus : 24|2@1+ (1,0) [0|2] "" Vector__XXX

BO_ 1409 TCU_log: 8 TCU
 SG_ TCU_logMux M : 0|32@1+ (1,0) [0|4294967295] "" Vector__XXX
 SG_ TCU_cpuTemp m0 : 32|32@1+ (1,0) [0|4294967295] "C" Vector__XXX
 SG_ TCU_cpuUsage m1 : 32|32@1+ (1,0) [0|4294967295] "%" Vector__XXX
 SG_ TCU_mdmCoreTemperature m2 : 32|32@1+ (1,0) [0|4294967295] "C" Vector__XXX
 SG_ TCU_availableMemory m3 : 32|32@1+ (1,0) [0|4294967295] "KB" Vector__XXX
 SG_ TCU_pwm m4 : 32|32@1+ (1,0) [0|4294967295] "" Vector__XXX
 SG_ TCU_pwmcap m5 : 32|32@1+ (1,0) [0|4294967295] "" Vector__XXX
 SG_ TCU_totalResumes m6 : 32|32@1+ (1,0) [0|4294967295] "" Vector__XXX
 SG_ TCU_mdmUplinkQueueSize m7 : 32|32@1+ (1,0) [0|4294967295] "bytes" Vector__XXX
 SG_ TCU_mdmRSRP m8 : 32|32@1- (1,0) [-2147483648|2147483647] "dBm" Vector__XXX
 SG_ TCU_mdmSINR m9 : 32|32@1- (1,0) [-2147483648|2147483647] "dBm" Vector__XXX
 SG_ TCU_mdmUplinkAllowedRate m10 : 32|32@1+ (1,0) [0|4294967295] "Kbps" Vector__XXX
 SG_ TCU_mdmServiceState m12 : 32|32@1+ (1,0) [0|4294967295] "" Vector__XXX
 SG_ TCU_mdmIMSStatus m13 : 32|32@1+ (1,0) [0|4294967295] "" Vector__XXX
 SG_ TCU_mdmSIMStatus m14 : 32|32@1+ (1,0) [0|4294967295] "" Vector__XXX
 SG_ TCU_mdmBusyActive m15 : 32|32@1+ (1,0) [0|4294967294] "" Vector__XXX

BO_ 1056 UIS_log: 8 UIS
 SG_ UIS_logMux M : 0|32@1+ (1,0) [0|4294967295] "" Vector__XXX
 SG_ UIS_wifiTemperature m11 : 32|32@1+ (1,0) [0|4294967295] "" Vector__XXX
 SG_ UIS_wifiStackState m12 : 32|32@1+ (1,0) [0|4294967295] "" Vector__XXX
 SG_ UIS_wifiBars m14 : 32|32@1+ (1,0) [0|4294967295] "" Vector__XXX
 SG_ UIS_wifiAutoJoinLowRSSI m15 : 32|32@1+ (1,0) [0|1] "" Vector__XXX
 SG_ UIS_valetMode m26 : 32|32@1+ (1,0) [0|1] "" Vector__XXX
 SG_ UIS_uiQtCarUptime m27 : 32|32@1+ (1,0) [0|4294967295] "" Vector__XXX
 SG_ UIS_uiMeanFPS m29 : 32|32@1+ (1,0) [0|4294967295] "" Vector__XXX
 SG_ UIS_tunerVoltageOperation m34 : 32|32@1+ (1,0) [0|4294967295] "" Vector__XXX
 SG_ UIS_tunerVoltageAntenna2 m36 : 32|32@1+ (1,0) [0|4294967295] "" Vector__XXX
 SG_ UIS_tunerVoltageAntenna1 m37 : 32|32@1+ (1,0) [0|4294967295] "" Vector__XXX
 SG_ UIS_tunerCurrentAntenna2 m42 : 32|32@1+ (1,0) [0|4294967295] "" Vector__XXX
 SG_ UIS_tunerCurrentAntenna1 m43 : 32|32@1+ (1,0) [0|4294967295] "" Vector__XXX
 SG_ UIS_tegraModemManState m56 : 32|32@1+ (1,0) [0|4294967295] "" Vector__XXX
 SG_ UIS_systemWakeTime m57 : 32|32@1+ (1,0) [0|4294967295] "" Vector__XXX
 SG_ UIS_systemUptime m58 : 32|32@1+ (1,0) [0|4294967295] "" Vector__XXX
 SG_ UIS_suspensionGeofence m60 : 32|32@1+ (1,0) [0|1] "" Vector__XXX
 SG_ UIS_superchargePaymentNeeded m61 : 32|32@1+ (1,0) [0|4294967295] "" Vector__XXX
 SG_ UIS_sleepType m70 : 32|32@1+ (1,0) [0|4294967295] "" Vector__XXX
 SG_ UIS_sleepTime m71 : 32|32@1+ (1,0) [0|4294967295] "" Vector__XXX
 SG_ UIS_sleepState m72 : 32|32@1+ (1,0) [0|4294967295] "" Vector__XXX
 SG_ UIS_slackerLoginResult m74 : 32|32@1+ (1,0) [0|4294967295] "" Vector__XXX
 SG_ UIS_sentryState m80 : 32|32@1+ (1,0) [0|4294967295] "" Vector__XXX
 SG_ UIS_sentryNeedsNap m81 : 32|32@1+ (1,0) [0|4294967295] "" Vector__XXX
 SG_ UIS_sentryIncidentCount m82 : 32|32@1+ (1,0) [0|4294967295] "" Vector__XXX
 SG_ UIS_scheduledChargingMode m83 : 32|32@1+ (1,0) [0|4294967295] "" Vector__XXX
 SG_ UIS_scheduleChargeStartTime m84 : 32|32@1+ (1,0) [0|4294967295] "" Vector__XXX
 SG_ UIS_scheduleChargeEndTime m85 : 32|32@1+ (1,0) [0|4294967295] "" Vector__XXX
 SG_ UIS_remoteRequestType m86 : 32|32@1+ (1,0) [0|4294967295] "" Vector__XXX
 SG_ UIS_rearDisplayUserPresent m89 : 32|32@1+ (1,0) [0|1] "" Vector__XXX
 SG_ UIS_rearDisplayState m90 : 32|32@1+ (1,0) [0|4294967295] "" Vector__XXX
 SG_ UIS_powerManagerState m100 : 32|5@1+ (1,0) [0|31] "" Vector__XXX
 SG_ UIS_polytopiax8664MemUsage m101 : 32|32@1+ (1,0) [0|4294967295] "" Vector__XXX
 SG_ UIS_polytopiax8664CPUUsage m102 : 32|32@1+ (1,0) [0|4294967295] "" Vector__XXX
 SG_ UIS_navAudioVolume m132 : 32|32@1+ (1,0) [0|4294967295] "" Vector__XXX
 SG_ UIS_muteNavVolume m133 : 32|32@1+ (1,0) [0|4294967295] "" Vector__XXX
 SG_ UIS_modemECallppAvail m145 : 32|32@1+ (1,0) [0|1] "" Vector__XXX
 SG_ UIS_modemBusyActive m146 : 32|32@1+ (1,0) [0|1] "" Vector__XXX
 SG_ UIS_mirrorGeofenceActive m147 : 32|32@1+ (1,0) [0|1] "" Vector__XXX
 SG_ UIS_mediaPlaybackStatus m150 : 32|32@1+ (1,0) [0|4294967295] "" Vector__XXX
 SG_ UIS_mediaNeedAuthToken m151 : 32|32@1+ (1,0) [0|1] "" Vector__XXX
 SG_ UIS_inSuperchargerGeofence m156 : 32|32@1+ (1,0) [0|1] "" Vector__XXX
 SG_ UIS_homelinkState m158 : 32|32@1+ (1,0) [0|4294967295] "" Vector__XXX
 SG_ UIS_headsetPairResult m163 : 32|32@1+ (1,0) [0|4294967295] "" Vector__XXX
 SG_ UIS_headsetConnectionState m164 : 32|32@1+ (1,0) [0|4294967295] "" Vector__XXX
 SG_ UIS_gpsmanagerMemUsage m178 : 32|32@1+ (1,0) [0|4294967295] "" Vector__XXX
 SG_ UIS_gpsmanagerCPUUsage m179 : 32|32@1+ (1,0) [0|4294967295] "" Vector__XXX
 SG_ UIS_featureSuperchargingEnabled m187 : 32|32@1+ (1,0) [0|4294967295] "" Vector__XXX
 SG_ UIS_dmRearTouchDeviceExists m196 : 32|32@1+ (1,0) [0|4294967295] "" Vector__XXX
 SG_ UIS_dmRearPowerState m197 : 32|32@1+ (1,0) [0|1] "" Vector__XXX
 SG_ UIS_dmRearLinkCheckOk m198 : 32|32@1+ (1,0) [0|1] "" Vector__XXX
 SG_ UIS_dmRearEnabled m199 : 32|32@1+ (1,0) [0|4294967295] "" Vector__XXX
 SG_ UIS_dmRearConnected m200 : 32|32@1+ (1,0) [0|4294967295] "" Vector__XXX
 SG_ UIS_dmRearBacklightDutyCycle m204 : 32|32@1+ (1,0) [0|4294967295] "" Vector__XXX
 SG_ UIS_dmRearBacklightDevExists m205 : 32|32@1+ (1,0) [0|1] "" Vector__XXX
 SG_ UIS_dmIcuPowerState m209 : 32|32@1+ (1,0) [0|1] "" Vector__XXX
 SG_ UIS_dmIcuLinkCheckOk m210 : 32|32@1+ (1,0) [0|1] "" Vector__XXX
 SG_ UIS_dmIcuEnabled m211 : 32|32@1+ (1,0) [0|4294967295] "" Vector__XXX
 SG_ UIS_dmIcuConnected m212 : 32|32@1+ (1,0) [0|4294967295] "" Vector__XXX
 SG_ UIS_dmIcuBacklightDutyCycle m216 : 32|32@1+ (1,0) [0|4294967295] "" Vector__XXX
 SG_ UIS_dmIcuBacklightDevExists m217 : 32|32@1+ (1,0) [0|1] "" Vector__XXX
 SG_ UIS_dmGatewayLinkWedged m222 : 32|32@1+ (1,0) [0|4294967295] "" Vector__XXX
 SG_ UIS_dmCenterTouchDeviceExists m224 : 32|32@1+ (1,0) [0|4294967295] "" Vector__XXX
 SG_ UIS_dmCenterPowerState m227 : 32|32@1+ (1,0) [0|1] "" Vector__XXX
 SG_ UIS_dmCenterOsdDisplayedState m228 : 32|32@1+ (1,0) [0|1] "" Vector__XXX
 SG_ UIS_dmCenterLinkCheckOk m233 : 32|32@1+ (1,0) [0|1] "" Vector__XXX
 SG_ UIS_dmCenterEnabled m234 : 32|32@1+ (1,0) [0|4294967295] "" Vector__XXX
 SG_ UIS_dmCenterConnected m235 : 32|32@1+ (1,0) [0|4294967295] "" Vector__XXX
 SG_ UIS_dmCenterBacklightPowerLevel m236 : 32|32@1+ (1,0) [0|4294967295] "" Vector__XXX
 SG_ UIS_dmCenterBacklightDutyCycle m239 : 32|32@1+ (1,0) [0|4294967295] "" Vector__XXX
 SG_ UIS_dmCenterBacklightDevExists m240 : 32|32@1+ (1,0) [0|1] "" Vector__XXX
 SG_ UIS_dgpuTemperature m245 : 32|32@1+ (1,0) [0|4294967295] "" Vector__XXX
 SG_ UIS_dashcamviewerMemUsage m247 : 32|32@1+ (1,0) [0|4294967295] "" Vector__XXX
 SG_ UIS_dashcamviewerCPUUsage m248 : 32|32@1+ (1,0) [0|4294967295] "" Vector__XXX
 SG_ UIS_dashcamStorageState m254 : 32|32@1+ (1,0) [0|4294967295] "" Vector__XXX
 SG_ UIS_dashcamStorageSentryMB m255 : 32|32@1+ (1,0) [0|4294967295] "" Vector__XXX
 SG_ UIS_dashcamStorageSavedMB m256 : 32|32@1+ (1,0) [0|4294967295] "" Vector__XXX
 SG_ UIS_dashcamStorageRecentMB m257 : 32|32@1+ (1,0) [0|4294967295] "" Vector__XXX
 SG_ UIS_dashcamStorageAvailableMB m258 : 32|32@1+ (1,0) [0|4294967295] "" Vector__XXX
 SG_ UIS_dashcamState m259 : 32|32@1+ (1,0) [0|4294967295] "" Vector__XXX
 SG_ UIS_cpuTemperature m267 : 32|32@1+ (1,0) [0|4294967295] "" Vector__XXX
 SG_ UIS_clusterMemUsage m279 : 32|32@1+ (1,0) [0|4294967295] "" Vector__XXX
 SG_ UIS_clusterDisplayState m284 : 32|32@1+ (1,0) [0|4294967295] "" Vector__XXX
 SG_ UIS_clusterCPUUsage m285 : 32|32@1+ (1,0) [0|4294967295] "" Vector__XXX
 SG_ UIS_chargeOnSolarNoChargeReason m288 : 32|32@1+ (1,0) [0|4294967295] "" Vector__XXX
 SG_ UIS_centerDisplayState m291 : 32|32@1+ (1,0) [0|4294967295] "" Vector__XXX
 SG_ UIS_centerDisplayEvent m292 : 32|32@1+ (1,0) [0|4294967295] "" Vector__XXX
 SG_ UIS_cellularLinkManagerState m297 : 32|32@1+ (1,0) [0|4294967295] "" Vector__XXX
 SG_ UIS_carAssistState m298 : 32|32@1+ (1,0) [0|4294967295] "" Vector__XXX
 SG_ UIS_carAssistSessionCount m299 : 32|32@1+ (1,0) [0|4294967295] "" Vector__XXX
 SG_ UIS_carAssistErrorCode m300 : 32|32@1+ (1,0) [0|4294967295] "" Vector__XXX
 SG_ UIS_cameraRRepeaterStreamMissing m301 : 32|32@1+ (1,0) [0|1] "" Vector__XXX
 SG_ UIS_cameraRRepeaterPopup m303 : 32|32@1+ (1,0) [0|1] "" Vector__XXX
 SG_ UIS_cameraRRepeaterPipeline m304 : 32|32@1+ (1,0) [0|4294967295] "" Vector__XXX
 SG_ UIS_cameraLRepeaterStreamMissing m308 : 32|32@1+ (1,0) [0|1] "" Vector__XXX
 SG_ UIS_cameraLRepeaterPopup m310 : 32|32@1+ (1,0) [0|1] "" Vector__XXX
 SG_ UIS_cameraLRepeaterPipeline m311 : 32|32@1+ (1,0) [0|4294967295] "" Vector__XXX
 SG_ UIS_cameraBackupStreamMissing m320 : 32|32@1+ (1,0) [0|1] "" Vector__XXX
 SG_ UIS_cameraBackupPopup m322 : 32|32@1+ (1,0) [0|1] "" Vector__XXX
 SG_ UIS_cameraBackupPipeline m323 : 32|32@1+ (1,0) [0|4294967295] "" Vector__XXX
 SG_ UIS_cameraBackupFramerate m326 : 32|32@1+ (1,0) [0|4294967295] "" Vector__XXX
 SG_ UIS_boardTemperature m332 : 32|32@1+ (1,0) [0|4294967295] "" Vector__XXX
 SG_ UIS_bluetoothStackState m333 : 32|32@1+ (1,0) [0|4294967295] "" Vector__XXX
 SG_ UIS_bluetoothStackRearState m334 : 32|32@1+ (1,0) [0|4294967295] "" Vector__XXX
 SG_ UIS_bluetoothPairResult m335 : 32|32@1+ (1,0) [0|4294967295] "" Vector__XXX
 SG_ UIS_bluetoothMemUsage m336 : 32|32@1+ (1,0) [0|4294967295] "" Vector__XXX
 SG_ UIS_bluetoothConnectionState m337 : 32|32@1+ (1,0) [0|4294967295] "" Vector__XXX
 SG_ UIS_bluetoothCPUUsage m338 : 32|32@1+ (1,0) [0|4294967295] "" Vector__XXX
 SG_ UIS_bluetoothAutoConnectionState m339 : 32|32@1+ (1,0) [0|4294967295] "" Vector__XXX
 SG_ UIS_backlightUserRequest m344 : 32|32@1+ (1,0) [0|4294967295] "" Vector__XXX
 SG_ UIS_audioVolumeLevel m345 : 32|32@1+ (1,0) [0|4294967295] "" Vector__XXX
 SG_ UIS_audioType m346 : 32|32@1+ (1,0) [0|4294967295] "" Vector__XXX
 SG_ UIS_audioState m347 : 32|32@1+ (1,0) [0|4294967295] "" Vector__XXX
 SG_ UIS_audioSource m348 : 32|32@1+ (1,0) [0|4294967295] "" Vector__XXX
 SG_ UIS_audioPWSGain m349 : 32|32@1+ (1,0) [0|4294967295] "" Vector__XXX
 SG_ UIS_audioMediaPlaying m350 : 32|32@1+ (1,0) [0|4294967295] "" Vector__XXX
 SG_ UIS_audioMediaBrowsing m351 : 32|32@1+ (1,0) [0|4294967295] "" Vector__XXX
 SG_ UIS_audioA2BRediscoveryCount m352 : 32|32@1+ (1,0) [0|4294967295] "" Vector__XXX
 SG_ UIS_activeAppView m354 : 32|32@1+ (1,0) [0|4294967295] "" Vector__XXX

BO_ 979 UI_airbagCutoffStatus: 1 UI
 SG_ UI_airbagCutoffSwState : 0|2@1+ (1,0) [0|3] "" Vector__XXX

BO_ 1279 UI_energyConsumptionInfo: 8 UI
 SG_ UI_energyConsumptionInfoIndex M : 0|5@1+ (1,0) [0|31] "" Vector__XXX
 SG_ UI_energyLossTotal_epa m0 : 16|16@1- (1,0) [-32768|32767] "Wh" Vector__XXX
 SG_ UI_energyLossDriving_epa m0 : 32|16@1- (1,0) [-32768|32767] "Wh" Vector__XXX
 SG_ UI_energyLossClimate_epa m0 : 48|16@1- (1,0) [-32768|32767] "Wh" Vector__XXX
 SG_ UI_energyLossBattCond_epa m1 : 16|16@1- (1,0) [-32768|32767] "Wh" Vector__XXX
 SG_ UI_energyLossElevation_epa m1 : 32|16@1- (1,0) [-32768|32767] "Wh" Vector__XXX
 SG_ UI_energyLossAcc_epa m1 : 48|16@1- (1,0) [-32768|32767] "Wh" Vector__XXX
 SG_ UI_energyLossTotalSinceCharge_ep m2 : 16|16@1- (1,0) [-32768|32767] "Wh" Vector__XXX
 SG_ UI_energyLossDrivingSinceCharge_ m2 : 32|16@1- (1,0) [-32768|32767] "Wh" Vector__XXX
 SG_ UI_energyLossClimateSinceCharge_ m2 : 48|16@1- (1,0) [-32768|32767] "Wh" Vector__XXX
 SG_ UI_energyLossBattCondSinceCharge m3 : 16|16@1- (1,0) [-32768|32767] "Wh" Vector__XXX
 SG_ UI_energyLossElevationSinceCharg m3 : 32|16@1- (1,0) [-32768|32767] "Wh" Vector__XXX
 SG_ UI_energyLossAccSinceCharge_epa m3 : 48|16@1- (1,0) [-32768|32767] "Wh" Vector__XXX
 SG_ UI_energyLossTotalSinceTripStart m4 : 16|16@1- (1,0) [-32768|32767] "Wh" Vector__XXX
 SG_ UI_energyLossDrivingSinceTripSta m4 : 32|16@1- (1,0) [-32768|32767] "Wh" Vector__XXX
 SG_ UI_energyLossClimateSinceTripSta m4 : 48|16@1- (1,0) [-32768|32767] "Wh" Vector__XXX
 SG_ UI_energyLossBattCondSinceTripSt m5 : 16|16@1- (1,0) [-32768|32767] "Wh" Vector__XXX
 SG_ UI_energyLossElevationSinceTripS m5 : 32|16@1- (1,0) [-32768|32767] "Wh" Vector__XXX
 SG_ UI_energyLossAccSinceTripStart m5 : 48|16@1- (1,0) [-32768|32767] "Wh" Vector__XXX
 SG_ UI_energyDeltaTotal_epa m6 : 16|16@1- (1,0) [-32768|32767] "Wh" Vector__XXX
 SG_ UI_energyDeltaDriving_epa m6 : 32|16@1- (1,0) [-32768|32767] "Wh" Vector__XXX
 SG_ UI_energyDeltaClimate_epa m6 : 48|16@1- (1,0) [-32768|32767] "Wh" Vector__XXX
 SG_ UI_energyDeltaBattCond_epa m7 : 16|16@1- (1,0) [-32768|32767] "Wh" Vector__XXX
 SG_ UI_energyDeltaElevation_epa m7 : 32|16@1- (1,0) [-32768|32767] "Wh" Vector__XXX
 SG_ UI_energyDeltaAcc_epa m7 : 48|16@1- (1,0) [-32768|32767] "Wh" Vector__XXX
 SG_ UI_uiDeltaOffsetTotal_epa m8 : 16|16@1- (1,0) [-32768|32767] "Wh" Vector__XXX
 SG_ UI_uiDeltaOffsetDriving_epa m8 : 32|16@1- (1,0) [-32768|32767] "Wh" Vector__XXX
 SG_ UI_uiDeltaOffsetClimate_epa m8 : 48|16@1- (1,0) [-32768|32767] "Wh" Vector__XXX
 SG_ UI_uiDeltaOffsetBattCond_epa m9 : 16|16@1- (1,0) [-32768|32767] "Wh" Vector__XXX
 SG_ UI_uiDeltaOffsetElevation_epa m9 : 32|16@1- (1,0) [-32768|32767] "Wh" Vector__XXX
 SG_ UI_uiDeltaOffsetAcc_epa m9 : 48|16@1- (1,0) [-32768|32767] "Wh" Vector__XXX
 SG_ UI_rawToUiEnergyRatio_epa m10 : 8|8@1+ (0.01,0) [0|2.55] "-" Vector__XXX
 SG_ UI_driveDistance_epa m10 : 16|16@1+ (0.01,0) [0|655.35] "miles" Vector__XXX
 SG_ UI_energyDeltaTotalSinceCharge_e m11 : 16|16@1- (1,0) [-32768|32767] "Wh" Vector__XXX
 SG_ UI_energyDeltaDrivingSinceCharge m11 : 32|16@1- (1,0) [-32768|32767] "Wh" Vector__XXX
 SG_ UI_energyDeltaClimateSinceCharge m11 : 48|16@1- (1,0) [-32768|32767] "Wh" Vector__XXX
 SG_ UI_energyDeltaBattCondSinceCharg m12 : 16|16@1- (1,0) [-32768|32767] "Wh" Vector__XXX
 SG_ UI_energyDeltaElevationSinceChar m12 : 32|16@1- (1,0) [-32768|32767] "Wh" Vector__XXX
 SG_ UI_energyDeltaAccSinceCharge_epa m12 : 48|16@1- (1,0) [-32768|32767] "Wh" Vector__XXX
 SG_ UI_uiDeltaOffsetTotalSinceCharge m13 : 16|16@1- (1,0) [-32768|32767] "Wh" Vector__XXX
 SG_ UI_uiDeltaOffsetDrivingSinceChar m13 : 32|16@1- (1,0) [-32768|32767] "Wh" Vector__XXX
 SG_ UI_uiDeltaOffsetClimateSinceChar m13 : 48|16@1- (1,0) [-32768|32767] "Wh" Vector__XXX
 SG_ UI_uiDeltaOffsetBattCondSinceCha m14 : 16|16@1- (1,0) [-32768|32767] "Wh" Vector__XXX
 SG_ UI_uiDeltaOffsetElevationSinceCh m14 : 32|16@1- (1,0) [-32768|32767] "Wh" Vector__XXX
 SG_ UI_uiDeltaOffsetAccSinceCharge_e m14 : 48|16@1- (1,0) [-32768|32767] "Wh" Vector__XXX
 SG_ UI_rawToUiEnergyRatioSinceCharge m15 : 8|8@1+ (0.01,0) [0|2.55] "-" Vector__XXX
 SG_ UI_driveDistanceSinceCharge_epa m15 : 16|16@1+ (0.01,0) [0|655.35] "miles" Vector__XXX
 SG_ UI_energyDeltaTotalSinceTripStar m16 : 16|16@1- (1,0) [-32768|32767] "Wh" Vector__XXX
 SG_ UI_energyDeltaDrivingSinceTripSt m16 : 32|16@1- (1,0) [-32768|32767] "Wh" Vector__XXX
 SG_ UI_energyDeltaClimateSinceTripSt m16 : 48|16@1- (1,0) [-32768|32767] "Wh" Vector__XXX
 SG_ UI_energyDeltaBattCondSinceTripS m17 : 16|16@1- (1,0) [-32768|32767] "Wh" Vector__XXX
 SG_ UI_energyDeltaElevationSinceTrip m17 : 32|16@1- (1,0) [-32768|32767] "Wh" Vector__XXX
 SG_ UI_energyDeltaAccSinceTripStart m17 : 48|16@1- (1,0) [-32768|32767] "Wh" Vector__XXX
 SG_ UI_uiDeltaOffsetTotalSinceTripSt m18 : 16|16@1- (1,0) [-32768|32767] "Wh" Vector__XXX
 SG_ UI_uiDeltaOffsetDrivingSinceTrip m18 : 32|16@1- (1,0) [-32768|32767] "Wh" Vector__XXX
 SG_ UI_uiDeltaOffsetClimateSinceTrip m18 : 48|16@1- (1,0) [-32768|32767] "Wh" Vector__XXX
 SG_ UI_uiDeltaOffsetBattCondSinceTri m19 : 16|16@1- (1,0) [-32768|32767] "Wh" Vector__XXX
 SG_ UI_uiDeltaOffsetElevationSinceTr m19 : 32|16@1- (1,0) [-32768|32767] "Wh" Vector__XXX
 SG_ UI_uiDeltaOffsetAccSinceTripStar m19 : 48|16@1- (1,0) [-32768|32767] "Wh" Vector__XXX
 SG_ UI_rawToUiEnergyRatioSinceTripSt m20 : 8|8@1+ (0.01,0) [0|2.55] "-" Vector__XXX
 SG_ UI_driveDistanceSinceTripStart m20 : 16|16@1+ (0.01,0) [0|655.35] "miles" Vector__XXX
 SG_ UI_trailerMass m21 : 16|16@1+ (1,0) [0|65535] "kg" Vector__XXX

BO_ 563 UI_stalklessControl: 6 UI
 SG_ UI_gearRequest : 26|3@1+ (1,0) [1|7] "" Vector__XXX
 SG_ UI_fullScreenMode : 30|1@1+ (1,0) [0|1] "" Vector__XXX
 SG_ UI_gearStripShowing : 31|1@1+ (1,0) [0|1] "" Vector__XXX
 SG_ UI_gearStripForceShow : 35|1@1+ (1,0) [0|1] "" Vector__XXX
 SG_ UI_autoParkAvailable : 37|1@1+ (1,0) [0|1] "" Vector__XXX
 SG_ UI_gearStripSuppressActive : 39|1@1+ (1,0) [0|1] "" Vector__XXX
 SG_ UI_gearNeutralPressed : 40|1@1+ (1,0) [0|1] "" Vector__XXX

BO_ 699 UI_stalklessHealthStatus: 2 UI
 SG_ UI_centerDisplayRunning : 0|1@1+ (1,0) [0|1] "" Vector__XXX
 SG_ UI_centerDisplayPowerOn : 4|1@1+ (1,0) [0|1] "" Vector__XXX

BO_ 661 UI_systemMonitor: 8 UI
 SG_ UI_systemMonitorIndex M : 0|1@1+ (1,0) [0|1] "" Vector__XXX
 SG_ UI_SystemMemUsage m0 : 8|16@1+ (1,0) [0|65535] "MB" Vector__XXX
 SG_ UI_QtCarMemUsage m0 : 24|16@1+ (1,0) [0|65535] "MB" Vector__XXX
 SG_ UI_QtCarCPUUsage m0 : 40|7@1+ (1,0) [0|127] "%" Vector__XXX
 SG_ UI_SystemCPUUsage m0 : 48|7@1+ (1,0) [0|127] "%" Vector__XXX

BO_ 139 UI_tripPlanning2: 6 UI
 SG_ UI_maxSpeedToReachDestination : 0|16@1+ (0.01,0) [0|655.34] "m/s" Vector__XXX
 SG_ UI_timeToDestination : 32|16@1+ (1,0) [0|65534] "s" Vector__XXX

BO_ 1173 UI_tripPlanning3: 8 UI
 SG_ UI_predictedEnergy : 0|16@1- (0.01,0) [-327.67|327.67] "kWh" Vector__XXX
 SG_ UI_hindsightEnergy : 32|16@1- (0.01,0) [-327.67|327.67] "kWh" Vector__XXX

BO_TX_BU_ 943 : BB;
BO_TX_BU_ 2029 : BMS;
BO_TX_BU_ 2028 : BMS;
BO_TX_BU_ 888 : GTW;
BO_TX_BU_ 282 : GTW;
BO_TX_BU_ 838 : GTW;
BO_TX_BU_ 904 : GTW;
BO_TX_BU_ 2047 : GTW;
BO_TX_BU_ 1638 : GTW;
BO_TX_BU_ 1080 : GTW;
BO_TX_BU_ 1656 : GTW;
BO_TX_BU_ 2033 : GTW;
BO_TX_BU_ 60 : GTW;
BO_TX_BU_ 1370 : GTW;
BO_TX_BU_ 840 : GTW;
BO_TX_BU_ 1005 : GTW;
BO_TX_BU_ 1112 : GTW;
BO_TX_BU_ 828 : IDB;
BO_TX_BU_ 463 : PM;
BO_TX_BU_ 1409 : TCU;
BO_TX_BU_ 1056 : UIS;
BO_TX_BU_ 979 : UI;
BO_TX_BU_ 1279 : UI;
BO_TX_BU_ 563 : UI;
BO_TX_BU_ 699 : UI;
BO_TX_BU_ 661 : UI;
BO_TX_BU_ 139 : UI;
BO_TX_BU_ 1173 : UI;

CM_ "Tesla Model 3 CAN bus database; bus ETH; firmware 2025.20.8. Decoded CAN signal definitions (layout, scaling, units, value tables).";
CM_ BU_ BB "BB ECU";
CM_ BU_ BMS "High-voltage battery management system";
CM_ BU_ GTW "Gateway";
CM_ BU_ IDB "IDB ECU";
CM_ BU_ PM "PM ECU";
CM_ BU_ TCU "TCU ECU";
CM_ BU_ UI "Touchscreen user interface computer";
CM_ BU_ UIS "UIS ECU";
CM_ BO_ 943 "BB ECU message: status";
CM_ SG_ 943 BB_statusChecksum "BB ECU: status checksum";
CM_ SG_ 943 BB_statusCounter "BB ECU: status counter";
CM_ SG_ 943 BB_sOutputRod "Reports the measured brake booster (BB) plunger piston position";
CM_ SG_ 943 BB_sOutputRodQF "Reports the BB_sOutputRod signal qualifier";
CM_ SG_ 943 BB_sInputRod "Reports the measured brake booster (BB) input rod stroke.";
CM_ SG_ 943 BB_sInputRodQF "Reports the BB_sInputRod signal qualifier.";
CM_ SG_ 943 BB_driverBrakeApply "Indicates whether the driver operates the brake pedal. Only active when the driver brakes, not when an external brake command implemented on brake booster (BB).";
CM_ SG_ 943 BB_driverBrakeApplyQF "Qualifier for BB_driverBrakeApply";
CM_ SG_ 943 BB_boosterStatus "Indication of the brake booster (BB) functional state";
CM_ SG_ 943 BB_warningLampRequest "Request from brake booster (BB) to enable the red brake lamp";
CM_ SG_ 943 BB_brakeFluidLevel "Indication of the brake fluid reservoir fluid level sensor status measured by the brake booster (BB).";
CM_ SG_ 943 BB_internalState "Indication of the brake booster (BB) internal state";
CM_ BO_ 2029 "High-voltage battery management system message: debug info 10 hz";
CM_ SG_ 2029 BMS_10HzDebug_Id "High-voltage battery management system: 10 hz debug id";
CM_ SG_ 2029 BMS_activeCoolCellTargetT "High-voltage battery management system: active cool cell target t";
CM_ SG_ 2029 BMS_passiveCoolCellTargetT "High-voltage battery management system: passive cool cell target t";
CM_ BO_ 2028 "High-voltage battery management system message: thermal status2";
CM_ SG_ 2028 BMS_coldStagnationLimit "Minimum temperature at which the pack is allowed to be used as a heat-energy source";
CM_ SG_ 2028 BMS_hotStagnationLimit "Maximum temperature at which we allow the pack to be used for heat-energy storage";
CM_ SG_ 2028 BMS_hotCellTempLimit "Maximum temperature at which the pack will allow limp mode levels of current";
CM_ SG_ 2028 BMS_activeCoolCellReferenceT "Desired cell temperature reference which composes the temperature trajectory portion of the active cooling target temperature controls";
CM_ SG_ 2028 BMS_activeHeatCellTargetT "Desired cell temperature which feeds as an input to the active heating target temperature, before any additional controls calculations";
CM_ SG_ 2028 BMS_cellTempTargetMode "Operating mode of the thermal controls for the Battery Management System (BMS)";
CM_ SG_ 2028 BMS_requestDischarge "Flag identifying when the Battery Management System (BMS) is requesting the battery pack to be discharged";
CM_ BO_ 888 "Gateway message: e call";
CM_ SG_ 888 GTW_GTW_SOS_ECALL_RQST "State of the GTW-SOS-ECALL-RQST pin";
CM_ SG_ 888 GTW_LTE_ECALL_LOCK "State of the LTE-ECALL-LOCK pin";
CM_ BO_ 282 "Gateway message: adc4";
CM_ SG_ 282 GTW_BKP_BATT_MON "Gateway: BKP BATT MON; raw 4095 = signal not available (SNA)";
CM_ SG_ 282 GTW_BKP_BATT_NTC_P "BKP_BATT_NTC_P pni voltage; raw 4095 = signal not available (SNA)";
CM_ SG_ 282 GTW_ECALL_GPS_ANT_BIAS "Gateway: ECALL GPS ANT BIAS; raw 4095 = signal not available (SNA)";
CM_ SG_ 282 GTW_ECALL_MIC_DIAG "ECALL_MIC_DIAG voltage; raw 4095 = signal not available (SNA)";
CM_ SG_ 282 GTW_SOS_ECALL_nRQST_BUF "SOS_ECALL_nRQST_BUF voltage; raw 4095 = signal not available (SNA)";
CM_ BO_ 838 "Gateway message: autopilot override";
CM_ SG_ 838 GTW_autopilotOverrideState "Signals whether an autopilot trial or subscription is active";
CM_ SG_ 838 GTW_autopilotConfig "Current level of permanent Autopilot firmware";
CM_ SG_ 838 GTW_autopilotOverrideConfig "Current level of trial or subscription Autopilot firmware";
CM_ SG_ 838 GTW_autopilotOverrideExpireTime "Expiration time for the currently active autopilot trial or subscription";
CM_ BO_ 904 "Gateway message: can status";
CM_ SG_ 904 GTW_VEH_canBusActivity "Active if any frame detected on the bus";
CM_ SG_ 904 GTW_PARTY_canBusActivity "Active if any frame detected on the bus";
CM_ SG_ 904 GTW_CH_canBusActivity "Active if any frame detected on the bus";
CM_ SG_ 904 GTW_VEH_txWarning "Gateway: VEH tx warning";
CM_ SG_ 904 GTW_PARTY_txWarning "Gateway: PARTY tx warning";
CM_ SG_ 904 GTW_CH_txWarning "Gateway: CH tx warning";
CM_ SG_ 904 GTW_VEH_rxWarning "Gateway: VEH rx warning";
CM_ SG_ 904 GTW_PARTY_rxWarning "Gateway: PARTY rx warning";
CM_ SG_ 904 GTW_CH_rxWarning "Gateway: CH rx warning";
CM_ SG_ 904 GTW_VEH_faultConfinement "Fault confinement as per CAN spec";
CM_ SG_ 904 GTW_PARTY_faultConfinement "Fault confinement as per CAN spec";
CM_ SG_ 904 GTW_CH_faultConfinement "Fault confinement as per CAN spec";
CM_ BO_ 2047 "Gateway message: car config";
CM_ SG_ 2047 GTW_carConfigMultiplexer "Gateway: car config multiplexer";
CM_ SG_ 2047 GTW_deliveryStatus "Indicates whether the vehicle has been marked delivered to the customer in Tesla backend systems.";
CM_ SG_ 2047 GTW_cabinPTCHeaterType "Gateway: cabin PTC heater type";
CM_ SG_ 2047 GTW_rightHandDrive "Gateway: right hand drive";
CM_ SG_ 2047 GTW_rearLightType "Gateway: rear light type";
CM_ SG_ 2047 GTW_headlamps "Gateway: headlamps";
CM_ SG_ 2047 GTW_country "Gateway: country";
CM_ SG_ 2047 GTW_tireType "Gateway: tire type";
CM_ SG_ 2047 GTW_roofGlassType "Gateway: roof glass type";
CM_ SG_ 2047 GTW_dasHw "Indicates the Driver Assistance System (DAS) hardware installed.";
CM_ SG_ 2047 GTW_brakeHWType "Gateway: brake HW type";
CM_ SG_ 2047 GTW_restraintsHardwareType "Gateway: restraints hardware type";
CM_ SG_ 2047 GTW_drivetrainType "Gateway: drivetrain type";
CM_ SG_ 2047 GTW_radarHeaterType "Gateway: radar heater type";
CM_ SG_ 2047 GTW_exteriorTrimType "Gateway: exterior trim type";
CM_ SG_ 2047 GTW_frontSeatHeaters "Gateway: front seat heaters";
CM_ SG_ 2047 GTW_rearSeatHeaters "Gateway: rear seat heaters";
CM_ SG_ 2047 GTW_eCallAntennaHW "Gateway: e call antenna HW";
CM_ SG_ 2047 GTW_homelinkType "Gateway: homelink type";
CM_ SG_ 2047 GTW_vdcType "Gateway: vdc type";
CM_ SG_ 2047 GTW_memoryMirrors "Gateway: memory mirrors";
CM_ SG_ 2047 GTW_powerLiftgateType "Gateway: power liftgate type";
CM_ SG_ 2047 GTW_lumbarECUType "Gateway: lumbar ECU type";
CM_ SG_ 2047 GTW_rearSeatHeaterType "Gateway: rear seat heater type";
CM_ SG_ 2047 GTW_auxParkLamps "Gateway: aux park lamps";
CM_ SG_ 2047 GTW_interiorCabinRadarType "Gateway: interior cabin radar type";
CM_ SG_ 2047 GTW_hvacPanelVaneType "Gateway: hvac panel vane type";
CM_ SG_ 2047 GTW_intakeAirFilterType "Gateway: intake air filter type";
CM_ SG_ 2047 GTW_eBuckConfig "Gateway: e buck config";
CM_ SG_ 2047 GTW_steeringHeaterEnabled "Gateway: steering heater enabled";
CM_ SG_ 2047 GTW_activeHighBeam "Gateway: active high beam";
CM_ SG_ 2047 GTW_airbagCutoffSwitch "Gateway: airbag cutoff switch";
CM_ SG_ 2047 GTW_intrusionSensorType "Gateway: intrusion sensor type";
CM_ SG_ 2047 GTW_spoilerType "Gateway: spoiler type";
CM_ SG_ 2047 GTW_rearFogLamps "Gateway: rear fog lamps";
CM_ SG_ 2047 GTW_roofType "Gateway: roof type";
CM_ SG_ 2047 GTW_thirdRowSeatType "Gateway: third row seat type";
CM_ SG_ 2047 GTW_autopilot "Gateway: autopilot";
CM_ SG_ 2047 GTW_superchargingAccess "Gateway: supercharging access";
CM_ SG_ 2047 GTW_exteriorColor "Gateway: exterior color";
CM_ SG_ 2047 GTW_pedestrianWarningSound "Gateway: pedestrian warning sound";
CM_ SG_ 2047 GTW_steeringColumnUJointType "Gateway: steering column u joint type";
CM_ SG_ 2047 GTW_bPillarNFCParam "Gateway: b pillar NFC param";
CM_ SG_ 2047 GTW_interiorLighting "Gateway: interior lighting";
CM_ SG_ 2047 GTW_headlightLevelerType "Gateway: headlight leveler type";
CM_ SG_ 2047 GTW_numberHVILNodes "Gateway: number HVIL nodes";
CM_ SG_ 2047 GTW_mapRegion "Gateway: map region";
CM_ SG_ 2047 GTW_performancePackage "Gateway: performance package";
CM_ SG_ 2047 GTW_chassisType "Indicates the chassis type, which determines physical aspects such as suspension geometry, track width, wheel base, baseline tire size, and trailer capability.";
CM_ SG_ 2047 GTW_airSuspension "Gateway: air suspension";
CM_ SG_ 2047 GTW_centerConsoleControllerType "Gateway: center console controller type";
CM_ SG_ 2047 GTW_autopilotCameraType "Gateway: autopilot camera type";
CM_ SG_ 2047 GTW_connectivityPackage "Gateway: connectivity package";
CM_ SG_ 2047 GTW_plcSupportType "Gateway: plc support type";
CM_ SG_ 2047 GTW_packEnergy "Gateway: pack energy";
CM_ SG_ 2047 GTW_frontSeatReclinerHardware "Gateway: front seat recliner hardware";
CM_ SG_ 2047 GTW_brakeLineSwitchType "Gateway: brake line switch type";
CM_ SG_ 2047 GTW_softRange "Gateway: soft range";
CM_ SG_ 2047 GTW_refrigerantType "Gateway: refrigerant type";
CM_ SG_ 2047 GTW_wheelType "Gateway: wheel type";
CM_ SG_ 2047 GTW_brakeActuationType "Gateway: brake actuation type";
CM_ SG_ 2047 GTW_secondRowSeatType "Gateway: second row seat type";
CM_ SG_ 2047 GTW_secondRowSeatMotorType "Gateway: second row seat motor type";
CM_ SG_ 2047 GTW_birthday "Gateway: birthday";
CM_ SG_ 2047 GTW_eCallEnabled "Gateway: e call enabled";
CM_ SG_ 2047 GTW_parkAssistECUType "Gateway: park assist ECU type";
CM_ SG_ 2047 GTW_passengerAirbagType "Gateway: passenger airbag type";
CM_ SG_ 2047 GTW_forwardRadarHw "Gateway: forward radar hw";
CM_ SG_ 2047 GTW_frontSeatType "Gateway: front seat type";
CM_ SG_ 2047 GTW_secondRowDisplayType "Gateway: second row display type";
CM_ SG_ 2047 GTW_wirelessPhoneChargerType "Gateway: wireless phone charger type";
CM_ SG_ 2047 GTW_ethernetTunerType "Gateway: ethernet tuner type";
CM_ SG_ 2047 GTW_interiorTrimType "Gateway: interior trim type";
CM_ SG_ 2047 GTW_gloveboxUSBType "Gateway: glovebox USB type";
CM_ SG_ 2047 GTW_coolantPumpType "Gateway: coolant pump type";
CM_ SG_ 2047 GTW_epblHwType "Gateway: epbl hw type";
CM_ SG_ 2047 GTW_epbrHwType "Gateway: epbr hw type";
CM_ SG_ 2047 GTW_blowerMotorType "Gateway: blower motor type";
CM_ SG_ 2047 GTW_frontUsbHubType "Gateway: front usb hub type";
CM_ SG_ 2047 GTW_superManifoldType "Type of HVAC super manifold installed";
CM_ SG_ 2047 GTW_rcmLocation "Gateway: rcm location";
CM_ SG_ 2047 GTW_interiorCamFanType "Gateway: interior cam fan type";
CM_ SG_ 2047 GTW_sirenType "Gateway: siren type";
CM_ SG_ 2047 GTW_hornType "Gateway: horn type";
CM_ SG_ 2047 GTW_badgingVersion "Gateway: badging version";
CM_ SG_ 2047 GTW_steeringColumnMotorType "Gateway: steering column motor type";
CM_ SG_ 2047 GTW_refrigACLineType "Gateway: refrig AC line type";
CM_ SG_ 2047 GTW_refrigFilterType "Gateway: refrig filter type";
CM_ SG_ 2047 GTW_diBurnInType "Gateway: di burn in type";
CM_ SG_ 2047 GTW_specialBadgingType "Gateway: special badging type";
CM_ SG_ 2047 GTW_chassisSubType "Reports chassis sub-variant type.";
CM_ SG_ 2047 GTW_frontSeatVentilationType "Gateway: front seat ventilation type";
CM_ SG_ 2047 GTW_towPackage "Gateway: tow package";
CM_ SG_ 2047 GTW_refrigLccType "Gateway: refrig lcc type";
CM_ SG_ 2047 GTW_caliperColorType "Gateway: caliper color type";
CM_ SG_ 2047 GTW_wiperMotorType "Gateway: wiper motor type";
CM_ SG_ 2047 GTW_frontOverheadConsoleType "Gateway: front overhead console type";
CM_ SG_ 2047 GTW_shifterType "Gateway: shifter type";
CM_ SG_ 2047 GTW_compressorType "Gateway: compressor type";
CM_ SG_ 2047 GTW_twelveVBatteryType "Gateway: twelve v battery type";
CM_ SG_ 2047 GTW_efuseSWConfig "Gateway: efuse SW config";
CM_ SG_ 2047 GTW_tollCollectionModuleType "Gateway: toll collection module type";
CM_ SG_ 2047 GTW_bleEndpointUpdateMethod "Gateway: ble endpoint update method";
CM_ SG_ 2047 GTW_steeringWheelControllerType "Gateway: steering wheel controller type";
CM_ SG_ 2047 GTW_frontSeatVentilationEnabled "Gateway: front seat ventilation enabled";
CM_ SG_ 2047 GTW_gloveboxActuatorType "Gateway: glovebox actuator type";
CM_ SG_ 2047 GTW_epasType "Gateway: epas type";
CM_ SG_ 2047 GTW_homologationRegionOverride "Gateway: homologation region override";
CM_ SG_ 2047 GTW_windowCommandsPermissionType "Gateway: window commands permission type";
CM_ SG_ 2047 GTW_rgbInteriorLightingEnabled "Gateway: rgb interior lighting enabled";
CM_ SG_ 2047 GTW_windshieldWiperHeaterType "Gateway: windshield wiper heater type";
CM_ SG_ 2047 GTW_driveInterfaceType "Gateway: drive interface type";
CM_ SG_ 2047 GTW_efficiencyPackage "Gateway: efficiency package";
CM_ SG_ 2047 GTW_visorLightType "Gateway: visor light type";
CM_ SG_ 2047 GTW_gnssAntennaType "Gateway: gnss antenna type";
CM_ SG_ 2047 GTW_frontSeatHeatersEnabled "Gateway: front seat heaters enabled";
CM_ SG_ 2047 GTW_windshieldWiperHeaterEnabled "Gateway: windshield wiper heater enabled";
CM_ SG_ 2047 GTW_tcuType "Gateway: tcu type";
CM_ SG_ 2047 GTW_fasciaType "Gateway: fascia type";
CM_ SG_ 2047 GTW_powerSteeringColumn "Gateway: power steering column";
CM_ SG_ 2047 GTW_frontSeatHeaterType "Gateway: front seat heater type";
CM_ SG_ 2047 GTW_softPerformanceLimit "Gateway: soft performance limit";
CM_ SG_ 2047 GTW_alcoholInterlockType "Gateway: alcohol interlock type";
CM_ SG_ 2047 GTW_immersiveAudio "Gateway: immersive audio";
CM_ SG_ 2047 GTW_passengerOccupancySensorType "Gateway: passenger occupancy sensor type";
CM_ SG_ 2047 GTW_packPerformanceDeviation "Measures deviation from standard pack mass or power output capability associated with the vehicle packEnergy configuration.";
CM_ SG_ 2047 GTW_frontFogLamps "Gateway: front fog lamps";
CM_ SG_ 2047 GTW_driverOccupancySensorType "Gateway: driver occupancy sensor type";
CM_ SG_ 2047 GTW_audioType "Gateway: audio type";
CM_ SG_ 2047 GTW_occupancyClassificationFeatu "Gateway: occupancy classification feature type";
CM_ SG_ 2047 GTW_domeLightType "Gateway: dome light type";
CM_ SG_ 2047 GTW_tpmsType "Gateway: tpms type";
CM_ SG_ 2047 GTW_authenticationEndpointLayout "Gateway: authentication endpoint layout";
CM_ SG_ 2047 GTW_socSleepOverride "Gateway: soc sleep override";
CM_ SG_ 2047 GTW_r79BehaviorOverride "Gateway: r79 behavior override";
CM_ SG_ 2047 GTW_steeringHeaterType "Gateway: steering heater type";
CM_ SG_ 2047 GTW_sohRegulatoryStatus "Gateway: soh regulatory status";
CM_ SG_ 2047 GTW_m3yBusArchitecture "Reports notable features of vehicle communication bus architecture. Used for firmware artifact selection during update installation process.";
CM_ SG_ 2047 GTW_blindSpotIndicatorLightType "Gateway: blind spot indicator light type";
CM_ SG_ 2047 GTW_hvacCaseDoorType "Gateway: hvac case door type";
CM_ SG_ 2047 GTW_rduCableType "Indicates type of rear drive unit cable installed on vehicle.";
CM_ SG_ 2047 GTW_interiorCameraType "Gateway: interior camera type";
CM_ SG_ 2047 GTW_frontFasciaCameraType "Reports type of forward facing fascia camera installed.";
CM_ BO_ 1638 "Gateway message: diag session";
CM_ SG_ 1638 GTW_diagRemainingSeconds "Seconds remaining for the diagnostics session";
CM_ SG_ 1638 GTW_diagSessionActive "UDS Session Active";
CM_ SG_ 1638 GTW_diagLevel "Current diagnostics level";
CM_ SG_ 1638 GTW_diagUnlockProcedureActive "GTW diag unlock procedure active";
CM_ SG_ 1638 GTW_diagOverrideActive "GTW diag level override active";
CM_ SG_ 1638 GTW_diagPhysicalLinkEstablished "Physical diag cable connected to the switch and link established";
CM_ BO_ 1080 "Gateway message: eth nm";
CM_ SG_ 1080 GTW_ethGotoSleep "ETH bus sleep commanded";
CM_ SG_ 1080 GTW_ethWakeUpBus "Gateway: eth wake up bus";
CM_ SG_ 1080 GTW_vehBusAsleep "VEH bus sleep state";
CM_ SG_ 1080 GTW_ethHeartBeatCounter "Gateway: eth heart beat counter";
CM_ SG_ 1080 GTW_ethWakeUpReason "Tracks the cause of why the gateway wakes up the ethernet bus";
CM_ BO_ 1656 "Gateway message: gear control";
CM_ SG_ 1656 GTW_gearControlChecksum "Gateway: gear control checksum";
CM_ SG_ 1656 GTW_gearControlCounter "Gateway: gear control counter";
CM_ SG_ 1656 GTW_gearShiftRequest "Request to change gear state from center display UI control; raw 0 = signal not available (SNA)";
CM_ SG_ 1656 GTW_osdActive "Whether OSD is active";
CM_ SG_ 1656 GTW_primaryGearControlStatus "Status of the center display UI control";
CM_ SG_ 1656 GTW_gearStripEnable "UI control for showing and or activating the primary gear strip interface";
CM_ SG_ 1656 GTW_showNeutralButton "Tell UI that it is time to animate the N button to be shown";
CM_ SG_ 1656 GTW_showAutoParkButton "Tell UI that it is time to animate the autopark button to be shown";
CM_ SG_ 1656 GTW_autoParkRequest "Request to auto park from center display UI control";
CM_ SG_ 1656 GTW_smartShiftStatus "Based on the status of the infotainment system smart shift feature should be disabled; raw 0 = signal not available (SNA)";
CM_ SG_ 1656 GTW_processingRDgestures "Is GTW processing R and D swipe gestures";
CM_ SG_ 1656 GTW_processingTapPgestures "Is GTW processing contextual tap-to-park gestures";
CM_ SG_ 1656 GTW_gearStripChangeReason "Gateway: gear strip change reason; raw 0 = signal not available (SNA)";
CM_ SG_ 1656 GTW_touchActive "User present as touch on display is active";
CM_ SG_ 1656 GTW_steamOff "Let UI know to turn Steam off";
CM_ SG_ 1656 GTW_screenPCBTemperature "Reading from display i2c temperature sensor; raw 2047 = signal not available (SNA)";
CM_ BO_ 2033 "Gateway message: hrl";
CM_ SG_ 2033 GTW_hrlIndex "Gateway: hrl index";
CM_ SG_ 2033 GTW_hrlState "GTW hrl state";
CM_ SG_ 2033 GTW_hrlTriggerDuration "HRL duration";
CM_ SG_ 2033 GTW_hrlTriggerType "HRL trigger type";
CM_ SG_ 2033 GTW_hrlTriggerId "HRL trigger ID. A unique ID representing the signal conditions causing the HRL event to occur.";
CM_ SG_ 2033 GTW_hrlTriggerBus "Gateway: hrl trigger bus";
CM_ BO_ 60 "Gateway message: info";
CM_ SG_ 60 GTW_infoIndex "Gateway: info index";
CM_ SG_ 60 GTW_buildType "Gateway: build type";
CM_ SG_ 60 GTW_hardwareId "GTW hardware ID";
CM_ SG_ 60 GTW_platformType "Gateway: platform type";
CM_ SG_ 60 GTW_appCrc "Gateway: app crc";
CM_ SG_ 60 GTW_applicationGitHash "Gateway: application git hash";
CM_ SG_ 60 GTW_bootGitHash "Gateway: boot git hash";
CM_ BO_ 1370 "Gateway message: mismatch fault";
CM_ SG_ 1370 GTW_mismatchFaultIndex "Gateway: mismatch fault index";
CM_ SG_ 1370 GTW_mismatchFaultChecksum "Gateway: mismatch fault checksum";
CM_ SG_ 1370 GTW_mismatchFaultCounter "Gateway: mismatch fault counter";
CM_ SG_ 1370 GTW_GTWmismatchFault "Reports the Gateway (GTW) running a firmware version that does not match the rest of the vehicle";
CM_ SG_ 1370 GTW_BMSmismatchFault "Reports the high voltage Battery Management System (BMS) electronic control unit (ECU) running a firmware version that does not match the rest of the vehicle";
CM_ SG_ 1370 GTW_APSmismatchFault "Reports the Autopilot Processor Secondary (APS) electronic control unit (ECU) running a firmware version that does not match the rest of the vehicle";
CM_ SG_ 1370 GTW_BLEEPCENTERmismatchFault "Reports the Bluetooth Low Energy End Point Center (BLEEPCENTER) electronic control unit (ECU) running a firmware version that does not match the rest of the vehicle";
CM_ SG_ 1370 GTW_BLEEPLEFTmismatchFault "Reports the Bluetooth Low Energy End Point Left (BLEEPLEFT) electronic control unit (ECU) running a firmware version that does not match the rest of the vehicle";
CM_ SG_ 1370 GTW_BLEEPREARmismatchFault "Reports the Bluetooth Low Energy End Point Rear (BLEEPREAR) electronic control unit (ECU) running a firmware version that does not match the rest of the vehicle";
CM_ SG_ 1370 GTW_BLEEPRIGHTmismatchFault "Reports the Bluetooth Low Energy End Point Right (BLEEPRIGHT) electronic control unit (ECU) running a firmware version that does not match the rest of the vehicle";
CM_ SG_ 1370 GTW_CBCmismatchFault "Reports the Cabin Blower Controller (CBC) electronic control unit (ECU) running a firmware version that does not match the rest of the vehicle";
CM_ SG_ 1370 GTW_CMPmismatchFault "Reports the air conditioning compressor (CMP) electronic control unit (ECU) running a firmware version that does not match the rest of the vehicle";
CM_ SG_ 1370 GTW_CPmismatchFault "Reports the Charge Port (CP) electronic control unit (ECU) running a firmware version that does not match the rest of the vehicle";
CM_ SG_ 1370 GTW_DIFmismatchFault "Reports the front drive inverter (DIF) electronic control unit (ECU) running a firmware version that does not match the rest of the vehicle";
CM_ SG_ 1370 GTW_DIRmismatchFault "Reports the rear drive inverter (DIR) electronic control unit (ECU) running a firmware version that does not match the rest of the vehicle";
CM_ SG_ 1370 GTW_EPAS3PmismatchFault "Reports the primary Electronic Power Assisted Steering (EPAS3P) electronic control unit (ECU) running a firmware version that does not match the rest of the vehicle";
CM_ SG_ 1370 GTW_EPAS3SmismatchFault "Reports the secondary Electronic Power Assisted Steering (EPAS3S) electronic control unit (ECU) running a firmware version that does not match the rest of the vehicle";
CM_ SG_ 1370 GTW_EPBLmismatchFault "Reports the left Electronic Park Brake (EPBL) electronic control unit (ECU) running a firmware version that does not match the rest of the vehicle";
CM_ SG_ 1370 GTW_EPBRmismatchFault "Reports the right Electronic Park Brake (EPBR) electronic control unit (ECU) running a firmware version that does not match the rest of the vehicle";
CM_ SG_ 1370 GTW_ESPCALmismatchFault "Reports the Electronic Stability Program Calibration (ESPCAL) electronic control unit (ECU) running a firmware version that does not match the rest of the vehicle";
CM_ SG_ 1370 GTW_ESPmismatchFault "Reports the Electronic Stability Program (ESP) electronic control unit (ECU) running a firmware version that does not match the rest of the vehicle";
CM_ SG_ 1370 GTW_HCM3LmismatchFault "Reports the left LED matrix Headlamp Control Module (HCM3L) electronic control unit (ECU) running a firmware version that does not match the rest of the vehicle";
CM_ SG_ 1370 GTW_HCM3RmismatchFault "Reports the right LED matrix Headlamp Control Module (HCM3R) electronic control unit (ECU) running a firmware version that does not match the rest of the vehicle";
CM_ SG_ 1370 GTW_HCMLmismatchFault "Reports the left Headlamp Control Module (HCML) electronic control unit (ECU) running a firmware version that does not match the rest of the vehicle";
CM_ SG_ 1370 GTW_HCMRmismatchFault "Reports the right Headlamp Control Module (HCMR) electronic control unit (ECU) running a firmware version that does not match the rest of the vehicle";
CM_ SG_ 1370 GTW_HVPmismatchFault "Reports the High Voltage Processor (HVP) electronic control unit (ECU) running a firmware version that does not match the rest of the vehicle";
CM_ SG_ 1370 GTW_IBSTCALmismatchFault "Reports the electromechanical brake booster calibration, or iBooster Calibration (IBSTCAL), electronic control unit (ECU) running a firmware version that does not match the rest of the vehicle";
CM_ SG_ 1370 GTW_IBSTmismatchFault "Reports the electromechanical brake booster, or iBooster (IBST), electronic control unit (ECU) running a firmware version that does not match the rest of the vehicle";
CM_ SG_ 1370 GTW_LVBMSmismatchFault "Reports the Low Voltage Battery Management System (LVBMS) electronic control unit (ECU) running a firmware version that does not match the rest of the vehicle";
CM_ SG_ 1370 GTW_OCS1PmismatchFault "Reports the Occupancy Classification System - 1st Row Passenger (OCS1P) electronic control unit (ECU) running a firmware version that does not match the rest of the vehicle";
CM_ SG_ 1370 GTW_OPCFmismatchFault "Reports the front Oil Pump Controller (OPCF) electronic control unit (ECU) running a firmware version that does not match the rest of the vehicle";
CM_ SG_ 1370 GTW_OPCRmismatchFault "Reports the rear Oil Pump Controller (OPCR) electronic control unit (ECU) running a firmware version that does not match the rest of the vehicle";
CM_ SG_ 1370 GTW_PARKmismatchFault "Reports the Park Assist (PARK) electronic control unit (ECU) running a firmware version that does not match the rest of the vehicle";
CM_ SG_ 1370 GTW_PCSCPU2mismatchFault "Reports the Power Conversion System AC charging core (PCSCPU2) electronic control unit (ECU) running a firmware version that does not match the rest of the vehicle";
CM_ SG_ 1370 GTW_PCSmismatchFault "Reports the Power Conversion System (PCS) electronic control unit (ECU) running a firmware version that does not match the rest of the vehicle";
CM_ SG_ 1370 GTW_PMFmismatchFault "Reports the front Pedal Monitor (PMF) electronic control unit (ECU) running a firmware version that does not match the rest of the vehicle";
CM_ SG_ 1370 GTW_PMRmismatchFault "Reports the rear Pedal Monitor (PMR) electronic control unit (ECU) running a firmware version that does not match the rest of the vehicle";
CM_ SG_ 1370 GTW_PTCmismatchFault "Reports the Positive Temperature Coefficient (PTC) heater electronic control unit (ECU) running a firmware version that does not match the rest of the vehicle";
CM_ SG_ 1370 GTW_RCMCALmismatchFault "Reports the Restraint Control Module Calibration (RCMCAL) electronic control unit (ECU) running a firmware version that does not match the rest of the vehicle";
CM_ SG_ 1370 GTW_RCMmismatchFault "Reports the Restraint Control Module (RCM) electronic control unit (ECU) running a firmware version that does not match the rest of the vehicle";
CM_ SG_ 1370 GTW_SCCMmismatchFault "Reports the Steering Column Control Module (SCCM) electronic control unit (ECU) running a firmware version that does not match the rest of the vehicle";
CM_ SG_ 1370 GTW_SDCRmismatchFault "Reports the Secondary Disconnect Controller (SDCR) electronic control unit (ECU) running a firmware version that does not match the rest of the vehicle";
CM_ SG_ 1370 GTW_SWCmismatchFault "Reports the Steering Wheel Controller (SWC) electronic control unit (ECU) running a firmware version that does not match the rest of the vehicle";
CM_ SG_ 1370 GTW_THSmismatchFault "Reports the Temperature Humidity Sensor (THS) electronic control unit (ECU) running a firmware version that does not match the rest of the vehicle";
CM_ SG_ 1370 GTW_VCFRONTmismatchFault "Reports the front vehicle controller (VCFRONT) electronic control unit (ECU) running a firmware version that does not match the rest of the vehicle";
CM_ SG_ 1370 GTW_VCLEFTmismatchFault "Reports the left vehicle controller (VCLEFT) electronic control unit (ECU) running a firmware version that does not match the rest of the vehicle";
CM_ SG_ 1370 GTW_VCRIGHTmismatchFault "Reports the right vehicle controller (VCRIGHT) electronic control unit (ECU) running a firmware version that does not match the rest of the vehicle";
CM_ SG_ 1370 GTW_VCSECmismatchFault "Reports the vehicle security controller (VCSEC) electronic control unit (ECU) running a firmware version that does not match the rest of the vehicle";
CM_ SG_ 1370 GTW_PMmismatchFault "Reports the Pedal Monitor (PM) electronic control unit (ECU) running a firmware version that does not match the rest of the vehicle";
CM_ BO_ 840 "Gateway message: status";
CM_ SG_ 840 GTW_vehicleVersionMatchStatus "Signal to indicate if the vehicle ECUs are all on a matched production version";
CM_ SG_ 840 GTW_hwtype "Describes the chip GTW is running on; raw 0 = signal not available (SNA)";
CM_ SG_ 840 GTW_jcanProductName "Describes the JCAN reference (product) name; raw 0 = signal not available (SNA)";
CM_ SG_ 840 GTW_uptimeSeconds "GTW uptime in seconds";
CM_ SG_ 840 GTW_boardRevision "Board revision ID of the MCU PCBA";
CM_ SG_ 840 GTW_sentryModeState "Sentry Mode state; raw 6 = signal not available (SNA)";
CM_ SG_ 840 GTW_socSleepType "Describes the sleep type GTW is expecting from the SoC; raw 0 = signal not available (SNA)";
CM_ SG_ 840 GTW_resetType "Describes the type of reset GTW experienced; raw 0 = signal not available (SNA)";
CM_ BO_ 1005 "Gateway message: update status";
CM_ SG_ 1005 GTW_i2cUpdateActive "Gateway: i2c update active";
CM_ SG_ 1005 GTW_ecuUpdateStarted "Reports whether Electronic Control Unit (ECU) update phase is active.";
CM_ SG_ 1005 GTW_updateStarted "Main update in progress bit";
CM_ BO_ 1112 "Gateway message: veh nm";
CM_ SG_ 1112 GTW_nmGoingToSleep "Network management - Going to sleep state";
CM_ SG_ 1112 GTW_nmWakeUpBus "Gateway: nm wake up bus";
CM_ SG_ 1112 GTW_chBusAsleep "Chassis bus sleep state";
CM_ SG_ 1112 GTW_ethBusAsleep "ETH bus sleep state";
CM_ SG_ 1112 GTW_nmKeepAwakeReason "Network management - Keep awake reason; raw 0 = signal not available (SNA)";
CM_ SG_ 1112 GTW_nmWakeUpReason "Network management - Wakeup reason";
CM_ SG_ 1112 GTW_ethKeepAwakeReason "Reason GTW is keeping ETH bus awake; raw 0 = signal not available (SNA)";
CM_ SG_ 1112 GTW_nmDebugWakeUp "Gateway: nm debug wake up";
CM_ SG_ 1112 GTW_OTAKeepAwake "Signals that the vehicle buses should remain awake for an ongoing OTA update";
CM_ SG_ 1112 GTW_smsPokeReceived "The modem indicated it received an SMS poke";
CM_ BO_ 828 "IDB ECU message: info";
CM_ SG_ 828 IDB_infoIndex "IDB ECU: info index";
CM_ SG_ 828 IDB_infoPcbaID "IDB ECU: info pcba ID";
CM_ SG_ 828 IDB_infoAssemblyID "IDB ECU: info assembly ID";
CM_ SG_ 828 IDB_infoUsageID "IDB ECU: info usage ID";
CM_ SG_ 828 IDB_infoSubUsageID "IDB ECU: info sub usage ID";
CM_ BO_ 463 "PM ECU message: system state";
CM_ SG_ 463 PM_hvilSystemStatus "HVIL system status; raw 3 = signal not available (SNA)";
CM_ BO_ 1409 "TCU ECU message: log";
CM_ SG_ 1409 TCU_logMux "TCU ECU: log mux";
CM_ SG_ 1409 TCU_cpuTemp "Indicates the current temperature reported by the Central Processing Unit (CPU) in the modem application processor";
CM_ SG_ 1409 TCU_cpuUsage "Indicates the current CPU usage in percentage reported by the modem application processor";
CM_ SG_ 1409 TCU_mdmCoreTemperature "Indicates the current Communication Processor (CP) temperature reported by the modem CP.";
CM_ SG_ 1409 TCU_availableMemory "Indicates the currently available Random Access Memory in the modem application processor";
CM_ SG_ 1409 TCU_pwm "Indicates the active Pulse Width Modulation (PWM) duty cycle applied to the modem fan.";
CM_ SG_ 1409 TCU_pwmcap "Indicates the active Pulse Width Modulation (PWM) duty cycle restriciton applied to the modem fan.";
CM_ SG_ 1409 TCU_totalResumes "Indicates the total amount of times the modem has been resumed";
CM_ SG_ 1409 TCU_mdmUplinkQueueSize "TCU ECU: mdm uplink queue size";
CM_ SG_ 1409 TCU_mdmRSRP "TCU ECU: mdm RSRP";
CM_ SG_ 1409 TCU_mdmSINR "TCU ECU: mdm SINR";
CM_ SG_ 1409 TCU_mdmUplinkAllowedRate "TCU ECU: mdm uplink allowed rate";
CM_ SG_ 1409 TCU_mdmServiceState "TCU ECU: mdm service state";
CM_ SG_ 1409 TCU_mdmIMSStatus "Indicates the current IP Multimedia System (IMS) registration state.";
CM_ SG_ 1409 TCU_mdmSIMStatus "TCU ECU: mdm SIM status";
CM_ SG_ 1409 TCU_mdmBusyActive "Reports whether the modem busy service is active on the modem application processor.; raw 4294967295 = signal not available (SNA)";
CM_ BO_ 1056 "UIS ECU message: log";
CM_ SG_ 1056 UIS_logMux "UIS ECU: log mux";
CM_ SG_ 1056 UIS_wifiTemperature "Current temperature reported for wifi";
CM_ SG_ 1056 UIS_wifiStackState "WiFi stack state description";
CM_ SG_ 1056 UIS_wifiBars "WiFi bars for connected network";
CM_ SG_ 1056 UIS_wifiAutoJoinLowRSSI "Indicates an attempt to auto-join a known network with low Received Signal Strength Indicator (RSSI).";
CM_ SG_ 1056 UIS_valetMode "UI Valet Mode state";
CM_ SG_ 1056 UIS_uiQtCarUptime "Touchscreen UI software uptime";
CM_ SG_ 1056 UIS_uiMeanFPS "UI mean frames per second over a 60s period";
CM_ SG_ 1056 UIS_tunerVoltageOperation "Radio tuner operating voltage (mV)";
CM_ SG_ 1056 UIS_tunerVoltageAntenna2 "Radio tuner voltage (mV) for antenna 2";
CM_ SG_ 1056 UIS_tunerVoltageAntenna1 "Radio tuner voltage (mV) for antenna 1";
CM_ SG_ 1056 UIS_tunerCurrentAntenna2 "Radio tuner current (mA) for antenna 2";
CM_ SG_ 1056 UIS_tunerCurrentAntenna1 "Radio tuner current (mA) for antenna 1";
CM_ SG_ 1056 UIS_tegraModemManState "Tegra Cellular Modem Manager state";
CM_ SG_ 1056 UIS_systemWakeTime "Length of time since wake or boot if UI has not slept (seconds)";
CM_ SG_ 1056 UIS_systemUptime "Reports the system uptime duration.";
CM_ SG_ 1056 UIS_suspensionGeofence "Status of suspension geofence add or remove";
CM_ SG_ 1056 UIS_superchargePaymentNeeded "Reports that Supercharging payment is needed.";
CM_ SG_ 1056 UIS_sleepType "Reports the system sleep type.";
CM_ SG_ 1056 UIS_sleepTime "Reports the system sleep duration.";
CM_ SG_ 1056 UIS_sleepState "Reports the system sleep state.";
CM_ SG_ 1056 UIS_slackerLoginResult "Reports Slacker Media login events";
CM_ SG_ 1056 UIS_sentryState "Sentry Mode state";
CM_ SG_ 1056 UIS_sentryNeedsNap "Sentry Mode sleep indicator, max uptime reached";
CM_ SG_ 1056 UIS_sentryIncidentCount "Sentry Mode incident count, initializes to 0";
CM_ SG_ 1056 UIS_scheduledChargingMode "Scheduled charging mode";
CM_ SG_ 1056 UIS_scheduleChargeStartTime "Reports the scheduled charging start date time in MMDDHHMM format.";
CM_ SG_ 1056 UIS_scheduleChargeEndTime "Reports the scheduled charging end date time in MMDDHHMM format.";
CM_ SG_ 1056 UIS_remoteRequestType "Reports the signed remote request type sent to vehicle, excluding closures and start requests.";
CM_ SG_ 1056 UIS_rearDisplayUserPresent "Indicates if a user is present in the rear seat based on seat occupancy and rear display usage";
CM_ SG_ 1056 UIS_rearDisplayState "Reports the rear display state.";
CM_ SG_ 1056 UIS_powerManagerState "UI power manager state signal; raw 18 = signal not available (SNA)";
CM_ SG_ 1056 UIS_polytopiax8664MemUsage "polytopiax8664's Resident Memory usage in MB";
CM_ SG_ 1056 UIS_polytopiax8664CPUUsage "polytopiax8664's CPU usage in CPU usage %";
CM_ SG_ 1056 UIS_navAudioVolume "Navigation audio volume level";
CM_ SG_ 1056 UIS_muteNavVolume "Mute state of the navigation audio";
CM_ SG_ 1056 UIS_modemECallppAvail "Reports whether eCall++ is enabled and is running on Telematics Control Unit (TCU).";
CM_ SG_ 1056 UIS_modemBusyActive "Reports whether the modem busy logic is requested to be active on the modem application processor.";
CM_ SG_ 1056 UIS_mirrorGeofenceActive "Folding mirror geofence active status";
CM_ SG_ 1056 UIS_mediaPlaybackStatus "Media Current Playback Status";
CM_ SG_ 1056 UIS_mediaNeedAuthToken "Indicates whether the media system needs a new authentication token.";
CM_ SG_ 1056 UIS_inSuperchargerGeofence "Vehicle inside Supercharger Geofence";
CM_ SG_ 1056 UIS_homelinkState "State of Homelink sate machine";
CM_ SG_ 1056 UIS_headsetPairResult "Bluetooth headset pairing result";
CM_ SG_ 1056 UIS_headsetConnectionState "Bluetooth headset connection state";
CM_ SG_ 1056 UIS_gpsmanagerMemUsage "gpsManager's Resident Memory usage in MB";
CM_ SG_ 1056 UIS_gpsmanagerCPUUsage "gpsManager's CPU usage in CPU usage %";
CM_ SG_ 1056 UIS_featureSuperchargingEnabled "Reports the Supercharging enabled feature status.";
CM_ SG_ 1056 UIS_dmRearTouchDeviceExists "Reports status of rear display power state.";
CM_ SG_ 1056 UIS_dmRearPowerState "Logs rear display power state status";
CM_ SG_ 1056 UIS_dmRearLinkCheckOk "Logs whether rear display-hardware-init was successful";
CM_ SG_ 1056 UIS_dmRearEnabled "Rear display is enabled";
CM_ SG_ 1056 UIS_dmRearConnected "Rear display is connected";
CM_ SG_ 1056 UIS_dmRearBacklightDutyCycle "Logs rear backlight duty cycle status";
CM_ SG_ 1056 UIS_dmRearBacklightDevExists "Logs whether rear backlight device exists and was successfully detected";
CM_ SG_ 1056 UIS_dmIcuPowerState "Logs cluster display power state status";
CM_ SG_ 1056 UIS_dmIcuLinkCheckOk "Logs whether cluster display-hardware-init was successful";
CM_ SG_ 1056 UIS_dmIcuEnabled "Cluster display is enabled";
CM_ SG_ 1056 UIS_dmIcuConnected "Cluster display is connected";
CM_ SG_ 1056 UIS_dmIcuBacklightDutyCycle "Logs cluster backlight duty cycle status";
CM_ SG_ 1056 UIS_dmIcuBacklightDevExists "Logs whether cluster backlight device exists and was successfully detected";
CM_ SG_ 1056 UIS_dmGatewayLinkWedged "Indicates whether the center display gateway link is stuck.";
CM_ SG_ 1056 UIS_dmCenterTouchDeviceExists "Detects whether the center display touch input device is present.";
CM_ SG_ 1056 UIS_dmCenterPowerState "Logs center display power state status";
CM_ SG_ 1056 UIS_dmCenterOsdDisplayedState "Reports the center display On-Screen Display (OSD) shown state.";
CM_ SG_ 1056 UIS_dmCenterLinkCheckOk "Logs whether center display-hardware-init was successful";
CM_ SG_ 1056 UIS_dmCenterEnabled "Center display is enabled";
CM_ SG_ 1056 UIS_dmCenterConnected "Center display is connected";
CM_ SG_ 1056 UIS_dmCenterBacklightPowerLevel "Logs backlight power level for center display";
CM_ SG_ 1056 UIS_dmCenterBacklightDutyCycle "Logs center backlight duty cycle status";
CM_ SG_ 1056 UIS_dmCenterBacklightDevExists "Logs whether center backlight device exists and was successfully detected";
CM_ SG_ 1056 UIS_dgpuTemperature "Current temperature reported for dgpu";
CM_ SG_ 1056 UIS_dashcamviewerMemUsage "dashcamViewer's Resident Memory usage in MB";
CM_ SG_ 1056 UIS_dashcamviewerCPUUsage "dashcamViewer's CPU usage in CPU usage %";
CM_ SG_ 1056 UIS_dashcamStorageState "Internal state of the dashcam storage";
CM_ SG_ 1056 UIS_dashcamStorageSentryMB "Dashcam USB storage used by Sentry Clips in MB";
CM_ SG_ 1056 UIS_dashcamStorageSavedMB "Dashcam USB storage used by Saved Clips in MB";
CM_ SG_ 1056 UIS_dashcamStorageRecentMB "Dashcam USB storage used by Recent Clips in MB";
CM_ SG_ 1056 UIS_dashcamStorageAvailableMB "Dashcam USB storage that is Available in MB";
CM_ SG_ 1056 UIS_dashcamState "Internal state for the dashcam state machine";
CM_ SG_ 1056 UIS_cpuTemperature "Current temperature reported for cpu";
CM_ SG_ 1056 UIS_clusterMemUsage "cluster's Resident Memory usage in MB";
CM_ SG_ 1056 UIS_clusterDisplayState "Reports the instrument cluster display state.";
CM_ SG_ 1056 UIS_clusterCPUUsage "cluster's CPU usage in CPU usage %";
CM_ SG_ 1056 UIS_chargeOnSolarNoChargeReason "Reason car is not charging on solar";
CM_ SG_ 1056 UIS_centerDisplayState "Reports the center display state.";
CM_ SG_ 1056 UIS_centerDisplayEvent "Reports the events that cause center display state transitions.";
CM_ SG_ 1056 UIS_cellularLinkManagerState "CellLink Manager state";
CM_ SG_ 1056 UIS_carAssistState "Car Assist State";
CM_ SG_ 1056 UIS_carAssistSessionCount "Car Assist Session Count";
CM_ SG_ 1056 UIS_carAssistErrorCode "Car Assist Error Code";
CM_ SG_ 1056 UIS_cameraRRepeaterStreamMissing "Signal representing if left repeater camera stream is active within videod";
CM_ SG_ 1056 UIS_cameraRRepeaterPopup "Right repeater camera popup state";
CM_ SG_ 1056 UIS_cameraRRepeaterPipeline "Right repeater videod pipeline state";
CM_ SG_ 1056 UIS_cameraLRepeaterStreamMissing "Signal representing if left repeater camera stream is active within videod";
CM_ SG_ 1056 UIS_cameraLRepeaterPopup "Left repeater camera popup state";
CM_ SG_ 1056 UIS_cameraLRepeaterPipeline "Left repeater videod pipeline state";
CM_ SG_ 1056 UIS_cameraBackupStreamMissing "Signal representing if backup camera stream is active within videod";
CM_ SG_ 1056 UIS_cameraBackupPopup "Reports the backup camera popup state.";
CM_ SG_ 1056 UIS_cameraBackupPipeline "Reports the backup camera video pipeline state.";
CM_ SG_ 1056 UIS_cameraBackupFramerate "Reports the backup camera framerate.";
CM_ SG_ 1056 UIS_boardTemperature "Current temperature reported for board";
CM_ SG_ 1056 UIS_bluetoothStackState "Bluetooth stack state";
CM_ SG_ 1056 UIS_bluetoothStackRearState "Bluetooth rear stack state";
CM_ SG_ 1056 UIS_bluetoothPairResult "Bluetooth pairing result";
CM_ SG_ 1056 UIS_bluetoothMemUsage "Reports the Bluetooth process resident memory usage in megabytes.";
CM_ SG_ 1056 UIS_bluetoothConnectionState "Reports the Bluetooth connection state.";
CM_ SG_ 1056 UIS_bluetoothCPUUsage "Reports the Bluetooth process Central Processing Unit (CPU) usage percentage.";
CM_ SG_ 1056 UIS_bluetoothAutoConnectionState "Reports the Bluetooth auto-connection state.";
CM_ SG_ 1056 UIS_backlightUserRequest "Reports the Graphical User Interface (GUI) backlight user request value.";
CM_ SG_ 1056 UIS_audioVolumeLevel "User facing volume level";
CM_ SG_ 1056 UIS_audioType "Shows which audio amplifier type is currently configured";
CM_ SG_ 1056 UIS_audioState "Shows the state of the audio system";
CM_ SG_ 1056 UIS_audioSource "Shows which internal audio source is currently active";
CM_ SG_ 1056 UIS_audioPWSGain "Reports the pedestrian warning system volume in decibels.";
CM_ SG_ 1056 UIS_audioMediaPlaying "Shows which media source is currently being played";
CM_ SG_ 1056 UIS_audioMediaBrowsing "Shows which media source is currently being viewed";
CM_ SG_ 1056 UIS_audioA2BRediscoveryCount "Shows the count of a2b rediscoveries that have occurred";
CM_ SG_ 1056 UIS_activeAppView "Shows the currently displayed app";
CM_ BO_ 979 "Touchscreen user interface computer message: airbag cutoff status";
CM_ SG_ 979 UI_airbagCutoffSwState "Reports the front passenger airbag cutoff switch request.; raw 2 = signal not available (SNA)";
CM_ BO_ 1279 "Touchscreen user interface computer message: energy consumption info";
CM_ SG_ 1279 UI_energyConsumptionInfoIndex "Touchscreen user interface computer: energy consumption info index";
CM_ SG_ 1279 UI_energyLossTotal_epa "Energy amount for a given bucket for an energy consumption baseline (raw/real energy consumed)";
CM_ SG_ 1279 UI_energyLossDriving_epa "Energy amount for a given bucket for an energy consumption baseline (raw/real energy consumed)";
CM_ SG_ 1279 UI_energyLossClimate_epa "Energy amount for a given bucket for an energy consumption baseline (raw/real energy consumed)";
CM_ SG_ 1279 UI_energyLossBattCond_epa "Energy amount for a given bucket for an energy consumption baseline (raw/real energy consumed)";
CM_ SG_ 1279 UI_energyLossElevation_epa "Energy amount for a given bucket for an energy consumption baseline (raw/real energy consumed)";
CM_ SG_ 1279 UI_energyLossAcc_epa "Energy amount for a given bucket for an energy consumption baseline (raw/real energy consumed)";
CM_ SG_ 1279 UI_energyLossTotalSinceCharge_ep "Energy amount for a given bucket for an energy consumption baseline (raw/real energy consumed)";
CM_ SG_ 1279 UI_energyLossDrivingSinceCharge_ "Energy amount for a given bucket for an energy consumption baseline (raw/real energy consumed)";
CM_ SG_ 1279 UI_energyLossClimateSinceCharge_ "Energy amount for a given bucket for an energy consumption baseline (raw/real energy consumed)";
CM_ SG_ 1279 UI_energyLossBattCondSinceCharge "Energy amount for a given bucket for an energy consumption baseline (raw/real energy consumed)";
CM_ SG_ 1279 UI_energyLossElevationSinceCharg "Energy amount for a given bucket for an energy consumption baseline (raw/real energy consumed)";
CM_ SG_ 1279 UI_energyLossAccSinceCharge_epa "Energy amount for a given bucket for an energy consumption baseline (raw/real energy consumed)";
CM_ SG_ 1279 UI_energyLossTotalSinceTripStart "Energy amount for a given bucket for an energy consumption baseline (raw/real energy consumed)";
CM_ SG_ 1279 UI_energyLossDrivingSinceTripSta "Energy amount for a given bucket for an energy consumption baseline (raw/real energy consumed)";
CM_ SG_ 1279 UI_energyLossClimateSinceTripSta "Energy amount for a given bucket for an energy consumption baseline (raw/real energy consumed)";
CM_ SG_ 1279 UI_energyLossBattCondSinceTripSt "Energy amount for a given bucket for an energy consumption baseline (raw/real energy consumed)";
CM_ SG_ 1279 UI_energyLossElevationSinceTripS "Energy amount for a given bucket for an energy consumption baseline (raw/real energy consumed)";
CM_ SG_ 1279 UI_energyLossAccSinceTripStart "Energy amount for a given bucket for an energy consumption baseline (raw/real energy consumed)";
CM_ SG_ 1279 UI_energyDeltaTotal_epa "Energy amount for a given bucket for an energy consumption baseline (raw/real energy consumed)";
CM_ SG_ 1279 UI_energyDeltaDriving_epa "Energy amount for a given bucket for an energy consumption baseline (raw/real energy consumed)";
CM_ SG_ 1279 UI_energyDeltaClimate_epa "Energy amount for a given bucket for an energy consumption baseline (raw/real energy consumed)";
CM_ SG_ 1279 UI_energyDeltaBattCond_epa "Energy amount for a given bucket for an energy consumption baseline (raw/real energy consumed)";
CM_ SG_ 1279 UI_energyDeltaElevation_epa "Energy amount for a given bucket for an energy consumption baseline (raw/real energy consumed)";
CM_ SG_ 1279 UI_energyDeltaAcc_epa "Energy amount for a given bucket for an energy consumption baseline (raw/real energy consumed)";
CM_ SG_ 1279 UI_uiDeltaOffsetTotal_epa "Energy amount for a given bucket for an energy consumption baseline (raw/real energy consumed)";
CM_ SG_ 1279 UI_uiDeltaOffsetDriving_epa "Energy amount for a given bucket for an energy consumption baseline (raw/real energy consumed)";
CM_ SG_ 1279 UI_uiDeltaOffsetClimate_epa "Energy amount for a given bucket for an energy consumption baseline (raw/real energy consumed)";
CM_ SG_ 1279 UI_uiDeltaOffsetBattCond_epa "Energy amount for a given bucket for an energy consumption baseline (raw/real energy consumed)";
CM_ SG_ 1279 UI_uiDeltaOffsetElevation_epa "Energy amount for a given bucket for an energy consumption baseline (raw/real energy consumed)";
CM_ SG_ 1279 UI_uiDeltaOffsetAcc_epa "Energy amount for a given bucket for an energy consumption baseline (raw/real energy consumed)";
CM_ SG_ 1279 UI_rawToUiEnergyRatio_epa "Ratio used for conversion between UI and raw energy domains";
CM_ SG_ 1279 UI_driveDistance_epa "Distance driven for an energy consumption baseline";
CM_ SG_ 1279 UI_energyDeltaTotalSinceCharge_e "Energy amount for a given bucket for an energy consumption baseline (raw/real energy consumed)";
CM_ SG_ 1279 UI_energyDeltaDrivingSinceCharge "Energy amount for a given bucket for an energy consumption baseline (raw/real energy consumed)";
CM_ SG_ 1279 UI_energyDeltaClimateSinceCharge "Energy amount for a given bucket for an energy consumption baseline (raw/real energy consumed)";
CM_ SG_ 1279 UI_energyDeltaBattCondSinceCharg "Energy amount for a given bucket for an energy consumption baseline (raw/real energy consumed)";
CM_ SG_ 1279 UI_energyDeltaElevationSinceChar "Energy amount for a given bucket for an energy consumption baseline (raw/real energy consumed)";
CM_ SG_ 1279 UI_energyDeltaAccSinceCharge_epa "Energy amount for a given bucket for an energy consumption baseline (raw/real energy consumed)";
CM_ SG_ 1279 UI_uiDeltaOffsetTotalSinceCharge "Energy amount for a given bucket for an energy consumption baseline (raw/real energy consumed)";
CM_ SG_ 1279 UI_uiDeltaOffsetDrivingSinceChar "Energy amount for a given bucket for an energy consumption baseline (raw/real energy consumed)";
CM_ SG_ 1279 UI_uiDeltaOffsetClimateSinceChar "Energy amount for a given bucket for an energy consumption baseline (raw/real energy consumed)";
CM_ SG_ 1279 UI_uiDeltaOffsetBattCondSinceCha "Energy amount for a given bucket for an energy consumption baseline (raw/real energy consumed)";
CM_ SG_ 1279 UI_uiDeltaOffsetElevationSinceCh "Energy amount for a given bucket for an energy consumption baseline (raw/real energy consumed)";
CM_ SG_ 1279 UI_uiDeltaOffsetAccSinceCharge_e "Energy amount for a given bucket for an energy consumption baseline (raw/real energy consumed)";
CM_ SG_ 1279 UI_rawToUiEnergyRatioSinceCharge "Ratio used for conversion between UI and raw energy domains";
CM_ SG_ 1279 UI_driveDistanceSinceCharge_epa "Distance driven for an energy consumption baseline";
CM_ SG_ 1279 UI_energyDeltaTotalSinceTripStar "Energy amount for a given bucket for an energy consumption baseline (raw/real energy consumed)";
CM_ SG_ 1279 UI_energyDeltaDrivingSinceTripSt "Energy amount for a given bucket for an energy consumption baseline (raw/real energy consumed)";
CM_ SG_ 1279 UI_energyDeltaClimateSinceTripSt "Energy amount for a given bucket for an energy consumption baseline (raw/real energy consumed)";
CM_ SG_ 1279 UI_energyDeltaBattCondSinceTripS "Energy amount for a given bucket for an energy consumption baseline (raw/real energy consumed)";
CM_ SG_ 1279 UI_energyDeltaElevationSinceTrip "Energy amount for a given bucket for an energy consumption baseline (raw/real energy consumed)";
CM_ SG_ 1279 UI_energyDeltaAccSinceTripStart "Energy amount for a given bucket for an energy consumption baseline (raw/real energy consumed)";
CM_ SG_ 1279 UI_uiDeltaOffsetTotalSinceTripSt "Energy amount for a given bucket for an energy consumption baseline (raw/real energy consumed)";
CM_ SG_ 1279 UI_uiDeltaOffsetDrivingSinceTrip "Energy amount for a given bucket for an energy consumption baseline (raw/real energy consumed)";
CM_ SG_ 1279 UI_uiDeltaOffsetClimateSinceTrip "Energy amount for a given bucket for an energy consumption baseline (raw/real energy consumed)";
CM_ SG_ 1279 UI_uiDeltaOffsetBattCondSinceTri "Energy amount for a given bucket for an energy consumption baseline (raw/real energy consumed)";
CM_ SG_ 1279 UI_uiDeltaOffsetElevationSinceTr "Energy amount for a given bucket for an energy consumption baseline (raw/real energy consumed)";
CM_ SG_ 1279 UI_uiDeltaOffsetAccSinceTripStar "Energy amount for a given bucket for an energy consumption baseline (raw/real energy consumed)";
CM_ SG_ 1279 UI_rawToUiEnergyRatioSinceTripSt "Ratio used for conversion between UI and raw energy domains";
CM_ SG_ 1279 UI_driveDistanceSinceTripStart "Distance driven for an energy consumption baseline";
CM_ SG_ 1279 UI_trailerMass "Trailer mass from user input";
CM_ BO_ 563 "Touchscreen user interface computer message: stalkless control";
CM_ SG_ 563 UI_gearRequest "UI gear request from UI; raw 0 = signal not available (SNA)";
CM_ SG_ 563 UI_fullScreenMode "Aggregates all situations with which the UI is using the entire screen so stalkless gear controls are not present";
CM_ SG_ 563 UI_gearStripShowing "UI communicating to GTW that the gear strip is visible on the screen as part of a handshake";
CM_ SG_ 563 UI_gearStripForceShow "UI request to GTW to show the gear strip";
CM_ SG_ 563 UI_autoParkAvailable "UI communicating to GTW that the autpark functionality is available";
CM_ SG_ 563 UI_gearStripSuppressActive "UI communicating to GTW that the gear strip should not be shown";
CM_ SG_ 563 UI_gearNeutralPressed "Neutral button is being pressed";
CM_ BO_ 699 "Touchscreen user interface computer message: stalkless health status";
CM_ SG_ 699 UI_centerDisplayRunning "is center display running";
CM_ SG_ 699 UI_centerDisplayPowerOn "center display power on";
CM_ BO_ 661 "Touchscreen user interface computer message: system monitor";
CM_ SG_ 661 UI_systemMonitorIndex "Touchscreen user interface computer: system monitor index";
CM_ SG_ 661 UI_SystemMemUsage "Monitors system memory usage";
CM_ SG_ 661 UI_QtCarMemUsage "Monitors memory usage of the primary User Interface application";
CM_ SG_ 661 UI_QtCarCPUUsage "Monitors CPU usage of the primary User Interface application";
CM_ SG_ 661 UI_SystemCPUUsage "Monitors system CPU usage";
CM_ BO_ 139 "Touchscreen user interface computer message: trip planning2";
CM_ SG_ 139 UI_maxSpeedToReachDestination "maximum speed to reach destination without significant risk of running out of energy; raw 65535 = signal not available (SNA)";
CM_ SG_ 139 UI_timeToDestination "remaining time to reach destination; raw 65535 = signal not available (SNA)";
CM_ BO_ 1173 "Touchscreen user interface computer message: trip planning3";
CM_ SG_ 1173 UI_predictedEnergy "initially predicted energy in kWh for current location along navigation route; raw 32768 = signal not available (SNA)";
CM_ SG_ 1173 UI_hindsightEnergy "hindsight energy, the model predicted energy based on measured speed and acceleration for the current location along navigation route; raw 32768 = signal not available (SNA)";
BA_DEF_ "BusType" STRING;
BA_DEF_ "DBName" STRING;
BA_DEF_ "Baudrate" INT 0 1000000;
BA_DEF_ "BaudrateCANFD" INT 0 16000000;
BA_DEF_ "Manufacturer" STRING;
BA_DEF_ "FirmwareVersion" STRING;
BA_DEF_ "VehicleModel" STRING;
BA_DEF_ BU_ "ECU" STRING;
BA_DEF_ BO_ "GenMsgCycleTime" INT 0 3600000;
BA_DEF_ BO_ "GenMsgSendType" ENUM "Cyclic","NotUsed","NotUsed","NotUsed","NotUsed","NotUsed","NotUsed","IfActive","NoMsgSendType","NotUsed";
BA_DEF_ BO_ "VFrameFormat" ENUM "StandardCAN","ExtendedCAN","reserved","J1939PG","reserved","reserved","reserved","reserved","reserved","reserved","reserved","reserved","reserved","reserved","StandardCAN_FD","ExtendedCAN_FD";
BA_DEF_ BO_ "CANFD_BRS" ENUM "0","1";
BA_DEF_ SG_ "GenSigSNA" STRING;
BA_DEF_ SG_ "SystemSignalLongSymbol" STRING;
BA_DEF_ SG_ "Confidence" ENUM "validated","plausible","layout-only","contradicted";
BA_DEF_DEF_ "BusType" "CAN";
BA_DEF_DEF_ "DBName" "";
BA_DEF_DEF_ "Baudrate" 500000;
BA_DEF_DEF_ "BaudrateCANFD" 2000000;
BA_DEF_DEF_ "Manufacturer" "";
BA_DEF_DEF_ "FirmwareVersion" "";
BA_DEF_DEF_ "VehicleModel" "";
BA_DEF_DEF_ "ECU" "";
BA_DEF_DEF_ "GenMsgCycleTime" 0;
BA_DEF_DEF_ "GenMsgSendType" "NoMsgSendType";
BA_DEF_DEF_ "VFrameFormat" "StandardCAN";
BA_DEF_DEF_ "CANFD_BRS" "1";
BA_DEF_DEF_ "GenSigSNA" "";
BA_DEF_DEF_ "SystemSignalLongSymbol" "";
BA_DEF_DEF_ "Confidence" "layout-only";
BA_ "DBName" "Model3_ETH";
BA_ "Manufacturer" "Tesla";
BA_ "FirmwareVersion" "2025.20.8";
BA_ "VehicleModel" "Model 3";
BA_ "ECU" BU_ BB "BB";
BA_ "ECU" BU_ BMS "BMS";
BA_ "ECU" BU_ GTW "GTW";
BA_ "ECU" BU_ IDB "IDB";
BA_ "ECU" BU_ PM "PM";
BA_ "ECU" BU_ TCU "TCU";
BA_ "ECU" BU_ UI "UI";
BA_ "ECU" BU_ UIS "UIS";
BA_ "GenMsgCycleTime" BO_ 943 10;
BA_ "GenMsgSendType" BO_ 943 0;
BA_ "GenMsgCycleTime" BO_ 2029 100;
BA_ "GenMsgSendType" BO_ 2029 0;
BA_ "GenMsgCycleTime" BO_ 2028 1000;
BA_ "GenMsgSendType" BO_ 2028 0;
BA_ "GenMsgCycleTime" BO_ 888 1000;
BA_ "GenMsgSendType" BO_ 888 0;
BA_ "GenMsgCycleTime" BO_ 282 1000;
BA_ "GenMsgSendType" BO_ 282 0;
BA_ "GenMsgCycleTime" BO_ 838 1000;
BA_ "GenMsgSendType" BO_ 838 0;
BA_ "GenMsgCycleTime" BO_ 904 1000;
BA_ "GenMsgSendType" BO_ 904 0;
BA_ "GenMsgCycleTime" BO_ 2047 100;
BA_ "GenMsgSendType" BO_ 2047 0;
BA_ "GenMsgCycleTime" BO_ 1638 250;
BA_ "GenMsgSendType" BO_ 1638 0;
BA_ "GenMsgCycleTime" BO_ 1080 100;
BA_ "GenMsgSendType" BO_ 1080 0;
BA_ "GenMsgCycleTime" BO_ 1656 100;
BA_ "GenMsgSendType" BO_ 1656 0;
BA_ "GenMsgCycleTime" BO_ 2033 2000;
BA_ "GenMsgSendType" BO_ 2033 0;
BA_ "GenMsgCycleTime" BO_ 60 2000;
BA_ "GenMsgSendType" BO_ 60 0;
BA_ "GenMsgCycleTime" BO_ 1370 250;
BA_ "GenMsgSendType" BO_ 1370 0;
BA_ "GenMsgCycleTime" BO_ 840 1000;
BA_ "GenMsgSendType" BO_ 840 0;
BA_ "GenMsgCycleTime" BO_ 1005 1000;
BA_ "GenMsgSendType" BO_ 1005 0;
BA_ "GenMsgCycleTime" BO_ 1112 100;
BA_ "GenMsgSendType" BO_ 1112 0;
BA_ "GenMsgCycleTime" BO_ 828 10000;
BA_ "GenMsgSendType" BO_ 828 0;
BA_ "GenMsgCycleTime" BO_ 463 10;
BA_ "GenMsgSendType" BO_ 463 0;
BA_ "GenMsgCycleTime" BO_ 1409 1000;
BA_ "GenMsgSendType" BO_ 1409 0;
BA_ "GenMsgCycleTime" BO_ 979 500;
BA_ "GenMsgSendType" BO_ 979 0;
BA_ "GenMsgCycleTime" BO_ 1279 1000;
BA_ "GenMsgSendType" BO_ 1279 0;
BA_ "GenMsgCycleTime" BO_ 563 500;
BA_ "GenMsgSendType" BO_ 563 0;
BA_ "GenMsgCycleTime" BO_ 699 500;
BA_ "GenMsgSendType" BO_ 699 0;
BA_ "GenMsgCycleTime" BO_ 661 15000;
BA_ "GenMsgSendType" BO_ 661 0;
BA_ "GenMsgCycleTime" BO_ 139 1000;
BA_ "GenMsgSendType" BO_ 139 0;
BA_ "GenMsgCycleTime" BO_ 1173 1000;
BA_ "GenMsgSendType" BO_ 1173 0;
BA_ "Confidence" SG_ 943 BB_statusChecksum 0;
BA_ "Confidence" SG_ 943 BB_statusCounter 0;
BA_ "Confidence" SG_ 943 BB_sOutputRod 0;
BA_ "Confidence" SG_ 943 BB_sOutputRodQF 0;
BA_ "Confidence" SG_ 943 BB_sInputRod 0;
BA_ "Confidence" SG_ 943 BB_sInputRodQF 0;
BA_ "Confidence" SG_ 943 BB_driverBrakeApply 0;
BA_ "Confidence" SG_ 943 BB_driverBrakeApplyQF 0;
BA_ "Confidence" SG_ 943 BB_boosterStatus 0;
BA_ "Confidence" SG_ 943 BB_warningLampRequest 0;
BA_ "Confidence" SG_ 943 BB_brakeFluidLevel 0;
BA_ "Confidence" SG_ 943 BB_internalState 0;
BA_ "Confidence" SG_ 2029 BMS_10HzDebug_Id 1;
BA_ "Confidence" SG_ 2029 BMS_activeCoolCellTargetT 1;
BA_ "Confidence" SG_ 2029 BMS_passiveCoolCellTargetT 1;
BA_ "Confidence" SG_ 2028 BMS_coldStagnationLimit 1;
BA_ "Confidence" SG_ 2028 BMS_hotStagnationLimit 1;
BA_ "Confidence" SG_ 2028 BMS_hotCellTempLimit 1;
BA_ "Confidence" SG_ 2028 BMS_activeCoolCellReferenceT 1;
BA_ "Confidence" SG_ 2028 BMS_activeHeatCellTargetT 1;
BA_ "Confidence" SG_ 2028 BMS_cellTempTargetMode 1;
BA_ "Confidence" SG_ 2028 BMS_requestDischarge 1;
BA_ "Confidence" SG_ 888 GTW_GTW_SOS_ECALL_RQST 0;
BA_ "Confidence" SG_ 888 GTW_LTE_ECALL_LOCK 0;
BA_ "Confidence" SG_ 282 GTW_BKP_BATT_MON 1;
BA_ "GenSigSNA" SG_ 282 GTW_BKP_BATT_MON "4095";
BA_ "Confidence" SG_ 282 GTW_BKP_BATT_NTC_P 1;
BA_ "GenSigSNA" SG_ 282 GTW_BKP_BATT_NTC_P "4095";
BA_ "Confidence" SG_ 282 GTW_ECALL_GPS_ANT_BIAS 1;
BA_ "GenSigSNA" SG_ 282 GTW_ECALL_GPS_ANT_BIAS "4095";
BA_ "Confidence" SG_ 282 GTW_ECALL_MIC_DIAG 1;
BA_ "GenSigSNA" SG_ 282 GTW_ECALL_MIC_DIAG "4095";
BA_ "Confidence" SG_ 282 GTW_SOS_ECALL_nRQST_BUF 1;
BA_ "GenSigSNA" SG_ 282 GTW_SOS_ECALL_nRQST_BUF "4095";
BA_ "Confidence" SG_ 838 GTW_autopilotOverrideState 1;
BA_ "Confidence" SG_ 838 GTW_autopilotConfig 1;
BA_ "Confidence" SG_ 838 GTW_autopilotOverrideConfig 1;
BA_ "Confidence" SG_ 838 GTW_autopilotOverrideExpireTime 0;
BA_ "Confidence" SG_ 904 GTW_VEH_canBusActivity 0;
BA_ "Confidence" SG_ 904 GTW_PARTY_canBusActivity 0;
BA_ "Confidence" SG_ 904 GTW_CH_canBusActivity 0;
BA_ "Confidence" SG_ 904 GTW_VEH_txWarning 0;
BA_ "Confidence" SG_ 904 GTW_PARTY_txWarning 0;
BA_ "Confidence" SG_ 904 GTW_CH_txWarning 0;
BA_ "Confidence" SG_ 904 GTW_VEH_rxWarning 0;
BA_ "Confidence" SG_ 904 GTW_PARTY_rxWarning 0;
BA_ "Confidence" SG_ 904 GTW_CH_rxWarning 0;
BA_ "Confidence" SG_ 904 GTW_VEH_faultConfinement 0;
BA_ "Confidence" SG_ 904 GTW_PARTY_faultConfinement 0;
BA_ "Confidence" SG_ 904 GTW_CH_faultConfinement 0;
BA_ "Confidence" SG_ 2047 GTW_deliveryStatus 0;
BA_ "Confidence" SG_ 2047 GTW_cabinPTCHeaterType 0;
BA_ "Confidence" SG_ 2047 GTW_rightHandDrive 0;
BA_ "Confidence" SG_ 2047 GTW_rearLightType 0;
BA_ "Confidence" SG_ 2047 GTW_headlamps 0;
BA_ "Confidence" SG_ 2047 GTW_country 0;
BA_ "Confidence" SG_ 2047 GTW_tireType 0;
BA_ "Confidence" SG_ 2047 GTW_roofGlassType 1;
BA_ "Confidence" SG_ 2047 GTW_dasHw 0;
BA_ "Confidence" SG_ 2047 GTW_brakeHWType 0;
BA_ "Confidence" SG_ 2047 GTW_restraintsHardwareType 0;
BA_ "Confidence" SG_ 2047 GTW_drivetrainType 0;
BA_ "Confidence" SG_ 2047 GTW_radarHeaterType 0;
BA_ "Confidence" SG_ 2047 GTW_exteriorTrimType 0;
BA_ "Confidence" SG_ 2047 GTW_frontSeatHeaters 0;
BA_ "Confidence" SG_ 2047 GTW_rearSeatHeaters 0;
BA_ "Confidence" SG_ 2047 GTW_eCallAntennaHW 0;
BA_ "Confidence" SG_ 2047 GTW_homelinkType 0;
BA_ "Confidence" SG_ 2047 GTW_vdcType 0;
BA_ "Confidence" SG_ 2047 GTW_memoryMirrors 0;
BA_ "Confidence" SG_ 2047 GTW_powerLiftgateType 0;
BA_ "Confidence" SG_ 2047 GTW_lumbarECUType 0;
BA_ "Confidence" SG_ 2047 GTW_rearSeatHeaterType 0;
BA_ "Confidence" SG_ 2047 GTW_auxParkLamps 0;
BA_ "Confidence" SG_ 2047 GTW_interiorCabinRadarType 0;
BA_ "Confidence" SG_ 2047 GTW_hvacPanelVaneType 0;
BA_ "Confidence" SG_ 2047 GTW_intakeAirFilterType 0;
BA_ "Confidence" SG_ 2047 GTW_eBuckConfig 0;
BA_ "Confidence" SG_ 2047 GTW_steeringHeaterEnabled 0;
BA_ "Confidence" SG_ 2047 GTW_activeHighBeam 0;
BA_ "Confidence" SG_ 2047 GTW_airbagCutoffSwitch 0;
BA_ "Confidence" SG_ 2047 GTW_intrusionSensorType 0;
BA_ "Confidence" SG_ 2047 GTW_spoilerType 0;
BA_ "Confidence" SG_ 2047 GTW_rearFogLamps 0;
BA_ "Confidence" SG_ 2047 GTW_roofType 0;
BA_ "Confidence" SG_ 2047 GTW_thirdRowSeatType 0;
BA_ "Confidence" SG_ 2047 GTW_autopilot 0;
BA_ "Confidence" SG_ 2047 GTW_superchargingAccess 0;
BA_ "Confidence" SG_ 2047 GTW_exteriorColor 0;
BA_ "Confidence" SG_ 2047 GTW_pedestrianWarningSound 0;
BA_ "Confidence" SG_ 2047 GTW_steeringColumnUJointType 0;
BA_ "Confidence" SG_ 2047 GTW_bPillarNFCParam 0;
BA_ "Confidence" SG_ 2047 GTW_interiorLighting 0;
BA_ "Confidence" SG_ 2047 GTW_headlightLevelerType 0;
BA_ "Confidence" SG_ 2047 GTW_numberHVILNodes 0;
BA_ "Confidence" SG_ 2047 GTW_mapRegion 0;
BA_ "Confidence" SG_ 2047 GTW_performancePackage 0;
BA_ "Confidence" SG_ 2047 GTW_chassisType 0;
BA_ "Confidence" SG_ 2047 GTW_airSuspension 0;
BA_ "Confidence" SG_ 2047 GTW_centerConsoleControllerType 0;
BA_ "Confidence" SG_ 2047 GTW_autopilotCameraType 0;
BA_ "Confidence" SG_ 2047 GTW_connectivityPackage 0;
BA_ "Confidence" SG_ 2047 GTW_plcSupportType 0;
BA_ "Confidence" SG_ 2047 GTW_packEnergy 0;
BA_ "Confidence" SG_ 2047 GTW_frontSeatReclinerHardware 0;
BA_ "Confidence" SG_ 2047 GTW_brakeLineSwitchType 0;
BA_ "Confidence" SG_ 2047 GTW_softRange 0;
BA_ "Confidence" SG_ 2047 GTW_refrigerantType 0;
BA_ "Confidence" SG_ 2047 GTW_wheelType 0;
BA_ "Confidence" SG_ 2047 GTW_brakeActuationType 0;
BA_ "Confidence" SG_ 2047 GTW_secondRowSeatType 0;
BA_ "Confidence" SG_ 2047 GTW_secondRowSeatMotorType 0;
BA_ "Confidence" SG_ 2047 GTW_birthday 0;
BA_ "Confidence" SG_ 2047 GTW_eCallEnabled 0;
BA_ "Confidence" SG_ 2047 GTW_parkAssistECUType 0;
BA_ "Confidence" SG_ 2047 GTW_passengerAirbagType 0;
BA_ "Confidence" SG_ 2047 GTW_forwardRadarHw 0;
BA_ "Confidence" SG_ 2047 GTW_frontSeatType 0;
BA_ "Confidence" SG_ 2047 GTW_secondRowDisplayType 0;
BA_ "Confidence" SG_ 2047 GTW_wirelessPhoneChargerType 0;
BA_ "Confidence" SG_ 2047 GTW_ethernetTunerType 0;
BA_ "Confidence" SG_ 2047 GTW_interiorTrimType 0;
BA_ "Confidence" SG_ 2047 GTW_gloveboxUSBType 0;
BA_ "Confidence" SG_ 2047 GTW_coolantPumpType 0;
BA_ "Confidence" SG_ 2047 GTW_epblHwType 0;
BA_ "Confidence" SG_ 2047 GTW_epbrHwType 0;
BA_ "Confidence" SG_ 2047 GTW_blowerMotorType 0;
BA_ "Confidence" SG_ 2047 GTW_frontUsbHubType 0;
BA_ "Confidence" SG_ 2047 GTW_superManifoldType 0;
BA_ "Confidence" SG_ 2047 GTW_rcmLocation 0;
BA_ "Confidence" SG_ 2047 GTW_interiorCamFanType 1;
BA_ "Confidence" SG_ 2047 GTW_sirenType 0;
BA_ "Confidence" SG_ 2047 GTW_hornType 0;
BA_ "Confidence" SG_ 2047 GTW_badgingVersion 1;
BA_ "Confidence" SG_ 2047 GTW_steeringColumnMotorType 0;
BA_ "Confidence" SG_ 2047 GTW_refrigACLineType 0;
BA_ "Confidence" SG_ 2047 GTW_refrigFilterType 0;
BA_ "Confidence" SG_ 2047 GTW_diBurnInType 0;
BA_ "Confidence" SG_ 2047 GTW_specialBadgingType 0;
BA_ "Confidence" SG_ 2047 GTW_chassisSubType 1;
BA_ "Confidence" SG_ 2047 GTW_frontSeatVentilationType 1;
BA_ "Confidence" SG_ 2047 GTW_towPackage 0;
BA_ "Confidence" SG_ 2047 GTW_refrigLccType 0;
BA_ "Confidence" SG_ 2047 GTW_caliperColorType 0;
BA_ "Confidence" SG_ 2047 GTW_wiperMotorType 0;
BA_ "Confidence" SG_ 2047 GTW_frontOverheadConsoleType 0;
BA_ "Confidence" SG_ 2047 GTW_shifterType 0;
BA_ "Confidence" SG_ 2047 GTW_compressorType 0;
BA_ "Confidence" SG_ 2047 GTW_twelveVBatteryType 0;
BA_ "Confidence" SG_ 2047 GTW_efuseSWConfig 0;
BA_ "Confidence" SG_ 2047 GTW_tollCollectionModuleType 0;
BA_ "Confidence" SG_ 2047 GTW_bleEndpointUpdateMethod 0;
BA_ "Confidence" SG_ 2047 GTW_steeringWheelControllerType 0;
BA_ "Confidence" SG_ 2047 GTW_frontSeatVentilationEnabled 0;
BA_ "Confidence" SG_ 2047 GTW_gloveboxActuatorType 0;
BA_ "Confidence" SG_ 2047 GTW_epasType 0;
BA_ "Confidence" SG_ 2047 GTW_homologationRegionOverride 0;
BA_ "Confidence" SG_ 2047 GTW_windowCommandsPermissionType 0;
BA_ "Confidence" SG_ 2047 GTW_rgbInteriorLightingEnabled 0;
BA_ "Confidence" SG_ 2047 GTW_windshieldWiperHeaterType 0;
BA_ "Confidence" SG_ 2047 GTW_driveInterfaceType 0;
BA_ "Confidence" SG_ 2047 GTW_efficiencyPackage 0;
BA_ "Confidence" SG_ 2047 GTW_visorLightType 0;
BA_ "Confidence" SG_ 2047 GTW_gnssAntennaType 0;
BA_ "Confidence" SG_ 2047 GTW_frontSeatHeatersEnabled 0;
BA_ "Confidence" SG_ 2047 GTW_windshieldWiperHeaterEnabled 0;
BA_ "Confidence" SG_ 2047 GTW_tcuType 1;
BA_ "Confidence" SG_ 2047 GTW_fasciaType 0;
BA_ "Confidence" SG_ 2047 GTW_powerSteeringColumn 0;
BA_ "Confidence" SG_ 2047 GTW_frontSeatHeaterType 0;
BA_ "Confidence" SG_ 2047 GTW_softPerformanceLimit 0;
BA_ "Confidence" SG_ 2047 GTW_alcoholInterlockType 1;
BA_ "Confidence" SG_ 2047 GTW_immersiveAudio 0;
BA_ "Confidence" SG_ 2047 GTW_passengerOccupancySensorType 0;
BA_ "Confidence" SG_ 2047 GTW_packPerformanceDeviation 0;
BA_ "Confidence" SG_ 2047 GTW_frontFogLamps 0;
BA_ "Confidence" SG_ 2047 GTW_driverOccupancySensorType 0;
BA_ "Confidence" SG_ 2047 GTW_audioType 0;
BA_ "Confidence" SG_ 2047 GTW_occupancyClassificationFeatu 0;
BA_ "SystemSignalLongSymbol" SG_ 2047 GTW_occupancyClassificationFeatu "GTW_occupancyClassificationFeatureType";
BA_ "Confidence" SG_ 2047 GTW_domeLightType 0;
BA_ "Confidence" SG_ 2047 GTW_tpmsType 0;
BA_ "Confidence" SG_ 2047 GTW_authenticationEndpointLayout 0;
BA_ "Confidence" SG_ 2047 GTW_socSleepOverride 0;
BA_ "Confidence" SG_ 2047 GTW_r79BehaviorOverride 0;
BA_ "Confidence" SG_ 2047 GTW_steeringHeaterType 0;
BA_ "Confidence" SG_ 2047 GTW_sohRegulatoryStatus 0;
BA_ "Confidence" SG_ 2047 GTW_m3yBusArchitecture 0;
BA_ "Confidence" SG_ 2047 GTW_blindSpotIndicatorLightType 1;
BA_ "Confidence" SG_ 2047 GTW_hvacCaseDoorType 0;
BA_ "Confidence" SG_ 2047 GTW_rduCableType 0;
BA_ "Confidence" SG_ 2047 GTW_interiorCameraType 0;
BA_ "Confidence" SG_ 2047 GTW_frontFasciaCameraType 0;
BA_ "Confidence" SG_ 1638 GTW_diagRemainingSeconds 0;
BA_ "Confidence" SG_ 1638 GTW_diagSessionActive 0;
BA_ "Confidence" SG_ 1638 GTW_diagLevel 0;
BA_ "Confidence" SG_ 1638 GTW_diagUnlockProcedureActive 0;
BA_ "Confidence" SG_ 1638 GTW_diagOverrideActive 0;
BA_ "Confidence" SG_ 1638 GTW_diagPhysicalLinkEstablished 0;
BA_ "Confidence" SG_ 1080 GTW_ethGotoSleep 0;
BA_ "Confidence" SG_ 1080 GTW_ethWakeUpBus 0;
BA_ "Confidence" SG_ 1080 GTW_vehBusAsleep 0;
BA_ "Confidence" SG_ 1080 GTW_ethHeartBeatCounter 0;
BA_ "Confidence" SG_ 1080 GTW_ethWakeUpReason 1;
BA_ "Confidence" SG_ 1656 GTW_gearControlChecksum 0;
BA_ "Confidence" SG_ 1656 GTW_gearControlCounter 0;
BA_ "Confidence" SG_ 1656 GTW_gearShiftRequest 0;
BA_ "GenSigSNA" SG_ 1656 GTW_gearShiftRequest "0";
BA_ "Confidence" SG_ 1656 GTW_osdActive 0;
BA_ "Confidence" SG_ 1656 GTW_primaryGearControlStatus 0;
BA_ "Confidence" SG_ 1656 GTW_gearStripEnable 0;
BA_ "Confidence" SG_ 1656 GTW_showNeutralButton 0;
BA_ "Confidence" SG_ 1656 GTW_showAutoParkButton 0;
BA_ "Confidence" SG_ 1656 GTW_autoParkRequest 0;
BA_ "Confidence" SG_ 1656 GTW_smartShiftStatus 0;
BA_ "GenSigSNA" SG_ 1656 GTW_smartShiftStatus "0";
BA_ "Confidence" SG_ 1656 GTW_processingRDgestures 0;
BA_ "Confidence" SG_ 1656 GTW_processingTapPgestures 0;
BA_ "Confidence" SG_ 1656 GTW_gearStripChangeReason 0;
BA_ "GenSigSNA" SG_ 1656 GTW_gearStripChangeReason "0";
BA_ "Confidence" SG_ 1656 GTW_touchActive 0;
BA_ "Confidence" SG_ 1656 GTW_steamOff 0;
BA_ "Confidence" SG_ 1656 GTW_screenPCBTemperature 1;
BA_ "GenSigSNA" SG_ 1656 GTW_screenPCBTemperature "2047";
BA_ "Confidence" SG_ 2033 GTW_hrlIndex 1;
BA_ "Confidence" SG_ 2033 GTW_hrlState 0;
BA_ "Confidence" SG_ 2033 GTW_hrlTriggerDuration 1;
BA_ "Confidence" SG_ 2033 GTW_hrlTriggerType 0;
BA_ "Confidence" SG_ 2033 GTW_hrlTriggerId 1;
BA_ "Confidence" SG_ 60 GTW_infoIndex 1;
BA_ "Confidence" SG_ 60 GTW_buildType 0;
BA_ "Confidence" SG_ 60 GTW_hardwareId 0;
BA_ "Confidence" SG_ 60 GTW_platformType 0;
BA_ "Confidence" SG_ 60 GTW_appCrc 0;
BA_ "Confidence" SG_ 60 GTW_applicationGitHash 0;
BA_ "Confidence" SG_ 60 GTW_bootGitHash 0;
BA_ "Confidence" SG_ 1370 GTW_mismatchFaultIndex 1;
BA_ "Confidence" SG_ 1370 GTW_mismatchFaultChecksum 0;
BA_ "Confidence" SG_ 1370 GTW_mismatchFaultCounter 0;
BA_ "Confidence" SG_ 1370 GTW_GTWmismatchFault 0;
BA_ "Confidence" SG_ 1370 GTW_BMSmismatchFault 0;
BA_ "Confidence" SG_ 1370 GTW_APSmismatchFault 0;
BA_ "Confidence" SG_ 1370 GTW_BLEEPCENTERmismatchFault 0;
BA_ "Confidence" SG_ 1370 GTW_BLEEPLEFTmismatchFault 0;
BA_ "Confidence" SG_ 1370 GTW_BLEEPREARmismatchFault 0;
BA_ "Confidence" SG_ 1370 GTW_BLEEPRIGHTmismatchFault 0;
BA_ "Confidence" SG_ 1370 GTW_CBCmismatchFault 0;
BA_ "Confidence" SG_ 1370 GTW_CMPmismatchFault 0;
BA_ "Confidence" SG_ 1370 GTW_CPmismatchFault 0;
BA_ "Confidence" SG_ 1370 GTW_DIFmismatchFault 0;
BA_ "Confidence" SG_ 1370 GTW_DIRmismatchFault 0;
BA_ "Confidence" SG_ 1370 GTW_EPAS3PmismatchFault 0;
BA_ "Confidence" SG_ 1370 GTW_EPAS3SmismatchFault 0;
BA_ "Confidence" SG_ 1370 GTW_EPBLmismatchFault 0;
BA_ "Confidence" SG_ 1370 GTW_EPBRmismatchFault 0;
BA_ "Confidence" SG_ 1370 GTW_ESPCALmismatchFault 0;
BA_ "Confidence" SG_ 1370 GTW_ESPmismatchFault 0;
BA_ "Confidence" SG_ 1370 GTW_HCM3LmismatchFault 0;
BA_ "Confidence" SG_ 1370 GTW_HCM3RmismatchFault 0;
BA_ "Confidence" SG_ 1370 GTW_HCMLmismatchFault 0;
BA_ "Confidence" SG_ 1370 GTW_HCMRmismatchFault 0;
BA_ "Confidence" SG_ 1370 GTW_HVPmismatchFault 0;
BA_ "Confidence" SG_ 1370 GTW_IBSTCALmismatchFault 0;
BA_ "Confidence" SG_ 1370 GTW_IBSTmismatchFault 0;
BA_ "Confidence" SG_ 1370 GTW_LVBMSmismatchFault 0;
BA_ "Confidence" SG_ 1370 GTW_OCS1PmismatchFault 0;
BA_ "Confidence" SG_ 1370 GTW_OPCFmismatchFault 0;
BA_ "Confidence" SG_ 1370 GTW_OPCRmismatchFault 0;
BA_ "Confidence" SG_ 1370 GTW_PARKmismatchFault 0;
BA_ "Confidence" SG_ 1370 GTW_PCSCPU2mismatchFault 0;
BA_ "Confidence" SG_ 1370 GTW_PCSmismatchFault 0;
BA_ "Confidence" SG_ 1370 GTW_PMFmismatchFault 0;
BA_ "Confidence" SG_ 1370 GTW_PMRmismatchFault 0;
BA_ "Confidence" SG_ 1370 GTW_PTCmismatchFault 0;
BA_ "Confidence" SG_ 1370 GTW_RCMCALmismatchFault 0;
BA_ "Confidence" SG_ 1370 GTW_RCMmismatchFault 0;
BA_ "Confidence" SG_ 1370 GTW_SCCMmismatchFault 0;
BA_ "Confidence" SG_ 1370 GTW_SDCRmismatchFault 0;
BA_ "Confidence" SG_ 1370 GTW_SWCmismatchFault 0;
BA_ "Confidence" SG_ 1370 GTW_THSmismatchFault 0;
BA_ "Confidence" SG_ 1370 GTW_VCFRONTmismatchFault 0;
BA_ "Confidence" SG_ 1370 GTW_VCLEFTmismatchFault 0;
BA_ "Confidence" SG_ 1370 GTW_VCRIGHTmismatchFault 0;
BA_ "Confidence" SG_ 1370 GTW_VCSECmismatchFault 0;
BA_ "Confidence" SG_ 1370 GTW_PMmismatchFault 0;
BA_ "Confidence" SG_ 840 GTW_vehicleVersionMatchStatus 0;
BA_ "Confidence" SG_ 840 GTW_hwtype 0;
BA_ "GenSigSNA" SG_ 840 GTW_hwtype "0";
BA_ "Confidence" SG_ 840 GTW_jcanProductName 0;
BA_ "GenSigSNA" SG_ 840 GTW_jcanProductName "0";
BA_ "Confidence" SG_ 840 GTW_uptimeSeconds 1;
BA_ "Confidence" SG_ 840 GTW_boardRevision 0;
BA_ "Confidence" SG_ 840 GTW_sentryModeState 1;
BA_ "GenSigSNA" SG_ 840 GTW_sentryModeState "6";
BA_ "Confidence" SG_ 840 GTW_socSleepType 0;
BA_ "GenSigSNA" SG_ 840 GTW_socSleepType "0";
BA_ "Confidence" SG_ 840 GTW_resetType 1;
BA_ "GenSigSNA" SG_ 840 GTW_resetType "0";
BA_ "Confidence" SG_ 1005 GTW_ecuUpdateStarted 0;
BA_ "Confidence" SG_ 1005 GTW_updateStarted 1;
BA_ "Confidence" SG_ 1112 GTW_nmGoingToSleep 0;
BA_ "Confidence" SG_ 1112 GTW_nmWakeUpBus 0;
BA_ "Confidence" SG_ 1112 GTW_chBusAsleep 0;
BA_ "Confidence" SG_ 1112 GTW_ethBusAsleep 0;
BA_ "Confidence" SG_ 1112 GTW_nmKeepAwakeReason 0;
BA_ "GenSigSNA" SG_ 1112 GTW_nmKeepAwakeReason "0";
BA_ "Confidence" SG_ 1112 GTW_nmWakeUpReason 1;
BA_ "Confidence" SG_ 1112 GTW_ethKeepAwakeReason 1;
BA_ "GenSigSNA" SG_ 1112 GTW_ethKeepAwakeReason "0";
BA_ "Confidence" SG_ 1112 GTW_nmDebugWakeUp 1;
BA_ "Confidence" SG_ 1112 GTW_OTAKeepAwake 1;
BA_ "Confidence" SG_ 1112 GTW_smsPokeReceived 1;
BA_ "Confidence" SG_ 828 IDB_infoIndex 1;
BA_ "Confidence" SG_ 828 IDB_infoPcbaID 0;
BA_ "Confidence" SG_ 828 IDB_infoAssemblyID 0;
BA_ "Confidence" SG_ 828 IDB_infoUsageID 0;
BA_ "Confidence" SG_ 828 IDB_infoSubUsageID 0;
BA_ "Confidence" SG_ 463 PM_hvilSystemStatus 1;
BA_ "GenSigSNA" SG_ 463 PM_hvilSystemStatus "3";
BA_ "Confidence" SG_ 1409 TCU_logMux 1;
BA_ "Confidence" SG_ 1409 TCU_cpuTemp 0;
BA_ "Confidence" SG_ 1409 TCU_cpuUsage 0;
BA_ "Confidence" SG_ 1409 TCU_mdmCoreTemperature 0;
BA_ "Confidence" SG_ 1409 TCU_availableMemory 0;
BA_ "Confidence" SG_ 1409 TCU_pwm 0;
BA_ "Confidence" SG_ 1409 TCU_pwmcap 0;
BA_ "Confidence" SG_ 1409 TCU_totalResumes 0;
BA_ "Confidence" SG_ 1409 TCU_mdmUplinkQueueSize 0;
BA_ "Confidence" SG_ 1409 TCU_mdmRSRP 0;
BA_ "Confidence" SG_ 1409 TCU_mdmSINR 0;
BA_ "Confidence" SG_ 1409 TCU_mdmUplinkAllowedRate 0;
BA_ "Confidence" SG_ 1409 TCU_mdmServiceState 0;
BA_ "Confidence" SG_ 1409 TCU_mdmIMSStatus 0;
BA_ "Confidence" SG_ 1409 TCU_mdmSIMStatus 0;
BA_ "Confidence" SG_ 1409 TCU_mdmBusyActive 0;
BA_ "GenSigSNA" SG_ 1409 TCU_mdmBusyActive "4294967295";
BA_ "Confidence" SG_ 1056 UIS_logMux 1;
BA_ "Confidence" SG_ 1056 UIS_wifiTemperature 0;
BA_ "Confidence" SG_ 1056 UIS_wifiStackState 0;
BA_ "Confidence" SG_ 1056 UIS_wifiBars 0;
BA_ "Confidence" SG_ 1056 UIS_wifiAutoJoinLowRSSI 0;
BA_ "Confidence" SG_ 1056 UIS_valetMode 0;
BA_ "Confidence" SG_ 1056 UIS_uiQtCarUptime 0;
BA_ "Confidence" SG_ 1056 UIS_uiMeanFPS 0;
BA_ "Confidence" SG_ 1056 UIS_tunerVoltageOperation 0;
BA_ "Confidence" SG_ 1056 UIS_tunerVoltageAntenna2 0;
BA_ "Confidence" SG_ 1056 UIS_tunerVoltageAntenna1 0;
BA_ "Confidence" SG_ 1056 UIS_tunerCurrentAntenna2 0;
BA_ "Confidence" SG_ 1056 UIS_tunerCurrentAntenna1 0;
BA_ "Confidence" SG_ 1056 UIS_tegraModemManState 0;
BA_ "Confidence" SG_ 1056 UIS_systemWakeTime 0;
BA_ "Confidence" SG_ 1056 UIS_systemUptime 0;
BA_ "Confidence" SG_ 1056 UIS_suspensionGeofence 0;
BA_ "Confidence" SG_ 1056 UIS_superchargePaymentNeeded 0;
BA_ "Confidence" SG_ 1056 UIS_sleepType 0;
BA_ "Confidence" SG_ 1056 UIS_sleepTime 0;
BA_ "Confidence" SG_ 1056 UIS_sleepState 0;
BA_ "Confidence" SG_ 1056 UIS_slackerLoginResult 0;
BA_ "Confidence" SG_ 1056 UIS_sentryState 0;
BA_ "Confidence" SG_ 1056 UIS_sentryNeedsNap 0;
BA_ "Confidence" SG_ 1056 UIS_sentryIncidentCount 0;
BA_ "Confidence" SG_ 1056 UIS_scheduledChargingMode 0;
BA_ "Confidence" SG_ 1056 UIS_scheduleChargeStartTime 0;
BA_ "Confidence" SG_ 1056 UIS_scheduleChargeEndTime 0;
BA_ "Confidence" SG_ 1056 UIS_remoteRequestType 0;
BA_ "Confidence" SG_ 1056 UIS_rearDisplayUserPresent 0;
BA_ "Confidence" SG_ 1056 UIS_rearDisplayState 0;
BA_ "Confidence" SG_ 1056 UIS_powerManagerState 0;
BA_ "GenSigSNA" SG_ 1056 UIS_powerManagerState "18";
BA_ "Confidence" SG_ 1056 UIS_polytopiax8664MemUsage 0;
BA_ "Confidence" SG_ 1056 UIS_polytopiax8664CPUUsage 0;
BA_ "Confidence" SG_ 1056 UIS_navAudioVolume 0;
BA_ "Confidence" SG_ 1056 UIS_muteNavVolume 0;
BA_ "Confidence" SG_ 1056 UIS_modemECallppAvail 0;
BA_ "Confidence" SG_ 1056 UIS_modemBusyActive 0;
BA_ "Confidence" SG_ 1056 UIS_mirrorGeofenceActive 0;
BA_ "Confidence" SG_ 1056 UIS_mediaPlaybackStatus 0;
BA_ "Confidence" SG_ 1056 UIS_mediaNeedAuthToken 0;
BA_ "Confidence" SG_ 1056 UIS_inSuperchargerGeofence 0;
BA_ "Confidence" SG_ 1056 UIS_homelinkState 0;
BA_ "Confidence" SG_ 1056 UIS_headsetPairResult 0;
BA_ "Confidence" SG_ 1056 UIS_headsetConnectionState 0;
BA_ "Confidence" SG_ 1056 UIS_gpsmanagerMemUsage 0;
BA_ "Confidence" SG_ 1056 UIS_gpsmanagerCPUUsage 0;
BA_ "Confidence" SG_ 1056 UIS_featureSuperchargingEnabled 0;
BA_ "Confidence" SG_ 1056 UIS_dmRearTouchDeviceExists 0;
BA_ "Confidence" SG_ 1056 UIS_dmRearPowerState 0;
BA_ "Confidence" SG_ 1056 UIS_dmRearLinkCheckOk 0;
BA_ "Confidence" SG_ 1056 UIS_dmRearEnabled 0;
BA_ "Confidence" SG_ 1056 UIS_dmRearConnected 0;
BA_ "Confidence" SG_ 1056 UIS_dmRearBacklightDutyCycle 0;
BA_ "Confidence" SG_ 1056 UIS_dmRearBacklightDevExists 0;
BA_ "Confidence" SG_ 1056 UIS_dmIcuPowerState 0;
BA_ "Confidence" SG_ 1056 UIS_dmIcuLinkCheckOk 0;
BA_ "Confidence" SG_ 1056 UIS_dmIcuEnabled 0;
BA_ "Confidence" SG_ 1056 UIS_dmIcuConnected 0;
BA_ "Confidence" SG_ 1056 UIS_dmIcuBacklightDutyCycle 0;
BA_ "Confidence" SG_ 1056 UIS_dmIcuBacklightDevExists 0;
BA_ "Confidence" SG_ 1056 UIS_dmGatewayLinkWedged 0;
BA_ "Confidence" SG_ 1056 UIS_dmCenterTouchDeviceExists 0;
BA_ "Confidence" SG_ 1056 UIS_dmCenterPowerState 0;
BA_ "Confidence" SG_ 1056 UIS_dmCenterOsdDisplayedState 0;
BA_ "Confidence" SG_ 1056 UIS_dmCenterLinkCheckOk 0;
BA_ "Confidence" SG_ 1056 UIS_dmCenterEnabled 0;
BA_ "Confidence" SG_ 1056 UIS_dmCenterConnected 0;
BA_ "Confidence" SG_ 1056 UIS_dmCenterBacklightPowerLevel 0;
BA_ "Confidence" SG_ 1056 UIS_dmCenterBacklightDutyCycle 0;
BA_ "Confidence" SG_ 1056 UIS_dmCenterBacklightDevExists 0;
BA_ "Confidence" SG_ 1056 UIS_dgpuTemperature 0;
BA_ "Confidence" SG_ 1056 UIS_dashcamviewerMemUsage 0;
BA_ "Confidence" SG_ 1056 UIS_dashcamviewerCPUUsage 0;
BA_ "Confidence" SG_ 1056 UIS_dashcamStorageState 0;
BA_ "Confidence" SG_ 1056 UIS_dashcamStorageSentryMB 0;
BA_ "Confidence" SG_ 1056 UIS_dashcamStorageSavedMB 0;
BA_ "Confidence" SG_ 1056 UIS_dashcamStorageRecentMB 0;
BA_ "Confidence" SG_ 1056 UIS_dashcamStorageAvailableMB 0;
BA_ "Confidence" SG_ 1056 UIS_dashcamState 0;
BA_ "Confidence" SG_ 1056 UIS_cpuTemperature 0;
BA_ "Confidence" SG_ 1056 UIS_clusterMemUsage 0;
BA_ "Confidence" SG_ 1056 UIS_clusterDisplayState 0;
BA_ "Confidence" SG_ 1056 UIS_clusterCPUUsage 0;
BA_ "Confidence" SG_ 1056 UIS_chargeOnSolarNoChargeReason 0;
BA_ "Confidence" SG_ 1056 UIS_centerDisplayState 0;
BA_ "Confidence" SG_ 1056 UIS_centerDisplayEvent 0;
BA_ "Confidence" SG_ 1056 UIS_cellularLinkManagerState 0;
BA_ "Confidence" SG_ 1056 UIS_carAssistState 0;
BA_ "Confidence" SG_ 1056 UIS_carAssistSessionCount 0;
BA_ "Confidence" SG_ 1056 UIS_carAssistErrorCode 0;
BA_ "Confidence" SG_ 1056 UIS_cameraRRepeaterStreamMissing 0;
BA_ "Confidence" SG_ 1056 UIS_cameraRRepeaterPopup 0;
BA_ "Confidence" SG_ 1056 UIS_cameraRRepeaterPipeline 0;
BA_ "Confidence" SG_ 1056 UIS_cameraLRepeaterStreamMissing 0;
BA_ "Confidence" SG_ 1056 UIS_cameraLRepeaterPopup 0;
BA_ "Confidence" SG_ 1056 UIS_cameraLRepeaterPipeline 0;
BA_ "Confidence" SG_ 1056 UIS_cameraBackupStreamMissing 0;
BA_ "Confidence" SG_ 1056 UIS_cameraBackupPopup 0;
BA_ "Confidence" SG_ 1056 UIS_cameraBackupPipeline 0;
BA_ "Confidence" SG_ 1056 UIS_cameraBackupFramerate 0;
BA_ "Confidence" SG_ 1056 UIS_boardTemperature 0;
BA_ "Confidence" SG_ 1056 UIS_bluetoothStackState 0;
BA_ "Confidence" SG_ 1056 UIS_bluetoothStackRearState 0;
BA_ "Confidence" SG_ 1056 UIS_bluetoothPairResult 0;
BA_ "Confidence" SG_ 1056 UIS_bluetoothMemUsage 0;
BA_ "Confidence" SG_ 1056 UIS_bluetoothConnectionState 0;
BA_ "Confidence" SG_ 1056 UIS_bluetoothCPUUsage 0;
BA_ "Confidence" SG_ 1056 UIS_bluetoothAutoConnectionState 0;
BA_ "Confidence" SG_ 1056 UIS_backlightUserRequest 0;
BA_ "Confidence" SG_ 1056 UIS_audioVolumeLevel 0;
BA_ "Confidence" SG_ 1056 UIS_audioType 0;
BA_ "Confidence" SG_ 1056 UIS_audioState 0;
BA_ "Confidence" SG_ 1056 UIS_audioSource 0;
BA_ "Confidence" SG_ 1056 UIS_audioPWSGain 0;
BA_ "Confidence" SG_ 1056 UIS_audioMediaPlaying 0;
BA_ "Confidence" SG_ 1056 UIS_audioMediaBrowsing 0;
BA_ "Confidence" SG_ 1056 UIS_audioA2BRediscoveryCount 0;
BA_ "Confidence" SG_ 1056 UIS_activeAppView 0;
BA_ "Confidence" SG_ 979 UI_airbagCutoffSwState 0;
BA_ "GenSigSNA" SG_ 979 UI_airbagCutoffSwState "2";
BA_ "Confidence" SG_ 1279 UI_energyConsumptionInfoIndex 1;
BA_ "Confidence" SG_ 1279 UI_energyLossTotal_epa 0;
BA_ "Confidence" SG_ 1279 UI_energyLossDriving_epa 0;
BA_ "Confidence" SG_ 1279 UI_energyLossClimate_epa 0;
BA_ "Confidence" SG_ 1279 UI_energyLossBattCond_epa 0;
BA_ "Confidence" SG_ 1279 UI_energyLossElevation_epa 0;
BA_ "Confidence" SG_ 1279 UI_energyLossAcc_epa 0;
BA_ "Confidence" SG_ 1279 UI_energyLossTotalSinceCharge_ep 0;
BA_ "SystemSignalLongSymbol" SG_ 1279 UI_energyLossTotalSinceCharge_ep "UI_energyLossTotalSinceCharge_epa";
BA_ "Confidence" SG_ 1279 UI_energyLossDrivingSinceCharge_ 0;
BA_ "SystemSignalLongSymbol" SG_ 1279 UI_energyLossDrivingSinceCharge_ "UI_energyLossDrivingSinceCharge_epa";
BA_ "Confidence" SG_ 1279 UI_energyLossClimateSinceCharge_ 0;
BA_ "SystemSignalLongSymbol" SG_ 1279 UI_energyLossClimateSinceCharge_ "UI_energyLossClimateSinceCharge_epa";
BA_ "Confidence" SG_ 1279 UI_energyLossBattCondSinceCharge 0;
BA_ "SystemSignalLongSymbol" SG_ 1279 UI_energyLossBattCondSinceCharge "UI_energyLossBattCondSinceCharge_epa";
BA_ "Confidence" SG_ 1279 UI_energyLossElevationSinceCharg 0;
BA_ "SystemSignalLongSymbol" SG_ 1279 UI_energyLossElevationSinceCharg "UI_energyLossElevationSinceCharge_epa";
BA_ "Confidence" SG_ 1279 UI_energyLossAccSinceCharge_epa 0;
BA_ "Confidence" SG_ 1279 UI_energyLossTotalSinceTripStart 0;
BA_ "Confidence" SG_ 1279 UI_energyLossDrivingSinceTripSta 0;
BA_ "SystemSignalLongSymbol" SG_ 1279 UI_energyLossDrivingSinceTripSta "UI_energyLossDrivingSinceTripStart";
BA_ "Confidence" SG_ 1279 UI_energyLossClimateSinceTripSta 0;
BA_ "SystemSignalLongSymbol" SG_ 1279 UI_energyLossClimateSinceTripSta "UI_energyLossClimateSinceTripStart";
BA_ "Confidence" SG_ 1279 UI_energyLossBattCondSinceTripSt 0;
BA_ "SystemSignalLongSymbol" SG_ 1279 UI_energyLossBattCondSinceTripSt "UI_energyLossBattCondSinceTripStart";
BA_ "Confidence" SG_ 1279 UI_energyLossElevationSinceTripS 0;
BA_ "SystemSignalLongSymbol" SG_ 1279 UI_energyLossElevationSinceTripS "UI_energyLossElevationSinceTripStart";
BA_ "Confidence" SG_ 1279 UI_energyLossAccSinceTripStart 0;
BA_ "Confidence" SG_ 1279 UI_energyDeltaTotal_epa 0;
BA_ "Confidence" SG_ 1279 UI_energyDeltaDriving_epa 0;
BA_ "Confidence" SG_ 1279 UI_energyDeltaClimate_epa 0;
BA_ "Confidence" SG_ 1279 UI_energyDeltaBattCond_epa 0;
BA_ "Confidence" SG_ 1279 UI_energyDeltaElevation_epa 0;
BA_ "Confidence" SG_ 1279 UI_energyDeltaAcc_epa 0;
BA_ "Confidence" SG_ 1279 UI_uiDeltaOffsetTotal_epa 0;
BA_ "Confidence" SG_ 1279 UI_uiDeltaOffsetDriving_epa 0;
BA_ "Confidence" SG_ 1279 UI_uiDeltaOffsetClimate_epa 0;
BA_ "Confidence" SG_ 1279 UI_uiDeltaOffsetBattCond_epa 0;
BA_ "Confidence" SG_ 1279 UI_uiDeltaOffsetElevation_epa 0;
BA_ "Confidence" SG_ 1279 UI_uiDeltaOffsetAcc_epa 0;
BA_ "Confidence" SG_ 1279 UI_rawToUiEnergyRatio_epa 0;
BA_ "Confidence" SG_ 1279 UI_driveDistance_epa 0;
BA_ "Confidence" SG_ 1279 UI_energyDeltaTotalSinceCharge_e 0;
BA_ "SystemSignalLongSymbol" SG_ 1279 UI_energyDeltaTotalSinceCharge_e "UI_energyDeltaTotalSinceCharge_epa";
BA_ "Confidence" SG_ 1279 UI_energyDeltaDrivingSinceCharge 0;
BA_ "SystemSignalLongSymbol" SG_ 1279 UI_energyDeltaDrivingSinceCharge "UI_energyDeltaDrivingSinceCharge_epa";
BA_ "Confidence" SG_ 1279 UI_energyDeltaClimateSinceCharge 0;
BA_ "SystemSignalLongSymbol" SG_ 1279 UI_energyDeltaClimateSinceCharge "UI_energyDeltaClimateSinceCharge_epa";
BA_ "Confidence" SG_ 1279 UI_energyDeltaBattCondSinceCharg 0;
BA_ "SystemSignalLongSymbol" SG_ 1279 UI_energyDeltaBattCondSinceCharg "UI_energyDeltaBattCondSinceCharge_epa";
BA_ "Confidence" SG_ 1279 UI_energyDeltaElevationSinceChar 0;
BA_ "SystemSignalLongSymbol" SG_ 1279 UI_energyDeltaElevationSinceChar "UI_energyDeltaElevationSinceCharge_epa";
BA_ "Confidence" SG_ 1279 UI_energyDeltaAccSinceCharge_epa 0;
BA_ "Confidence" SG_ 1279 UI_uiDeltaOffsetTotalSinceCharge 0;
BA_ "SystemSignalLongSymbol" SG_ 1279 UI_uiDeltaOffsetTotalSinceCharge "UI_uiDeltaOffsetTotalSinceCharge_epa";
BA_ "Confidence" SG_ 1279 UI_uiDeltaOffsetDrivingSinceChar 0;
BA_ "SystemSignalLongSymbol" SG_ 1279 UI_uiDeltaOffsetDrivingSinceChar "UI_uiDeltaOffsetDrivingSinceCharge_epa";
BA_ "Confidence" SG_ 1279 UI_uiDeltaOffsetClimateSinceChar 0;
BA_ "SystemSignalLongSymbol" SG_ 1279 UI_uiDeltaOffsetClimateSinceChar "UI_uiDeltaOffsetClimateSinceCharge_epa";
BA_ "Confidence" SG_ 1279 UI_uiDeltaOffsetBattCondSinceCha 0;
BA_ "SystemSignalLongSymbol" SG_ 1279 UI_uiDeltaOffsetBattCondSinceCha "UI_uiDeltaOffsetBattCondSinceCharge_epa";
BA_ "Confidence" SG_ 1279 UI_uiDeltaOffsetElevationSinceCh 0;
BA_ "SystemSignalLongSymbol" SG_ 1279 UI_uiDeltaOffsetElevationSinceCh "UI_uiDeltaOffsetElevationSinceCharge_epa";
BA_ "Confidence" SG_ 1279 UI_uiDeltaOffsetAccSinceCharge_e 0;
BA_ "SystemSignalLongSymbol" SG_ 1279 UI_uiDeltaOffsetAccSinceCharge_e "UI_uiDeltaOffsetAccSinceCharge_epa";
BA_ "Confidence" SG_ 1279 UI_rawToUiEnergyRatioSinceCharge 0;
BA_ "SystemSignalLongSymbol" SG_ 1279 UI_rawToUiEnergyRatioSinceCharge "UI_rawToUiEnergyRatioSinceCharge_epa";
BA_ "Confidence" SG_ 1279 UI_driveDistanceSinceCharge_epa 0;
BA_ "Confidence" SG_ 1279 UI_energyDeltaTotalSinceTripStar 0;
BA_ "SystemSignalLongSymbol" SG_ 1279 UI_energyDeltaTotalSinceTripStar "UI_energyDeltaTotalSinceTripStart";
BA_ "Confidence" SG_ 1279 UI_energyDeltaDrivingSinceTripSt 0;
BA_ "SystemSignalLongSymbol" SG_ 1279 UI_energyDeltaDrivingSinceTripSt "UI_energyDeltaDrivingSinceTripStart";
BA_ "Confidence" SG_ 1279 UI_energyDeltaClimateSinceTripSt 0;
BA_ "SystemSignalLongSymbol" SG_ 1279 UI_energyDeltaClimateSinceTripSt "UI_energyDeltaClimateSinceTripStart";
BA_ "Confidence" SG_ 1279 UI_energyDeltaBattCondSinceTripS 0;
BA_ "SystemSignalLongSymbol" SG_ 1279 UI_energyDeltaBattCondSinceTripS "UI_energyDeltaBattCondSinceTripStart";
BA_ "Confidence" SG_ 1279 UI_energyDeltaElevationSinceTrip 0;
BA_ "SystemSignalLongSymbol" SG_ 1279 UI_energyDeltaElevationSinceTrip "UI_energyDeltaElevationSinceTripStart";
BA_ "Confidence" SG_ 1279 UI_energyDeltaAccSinceTripStart 0;
BA_ "Confidence" SG_ 1279 UI_uiDeltaOffsetTotalSinceTripSt 0;
BA_ "SystemSignalLongSymbol" SG_ 1279 UI_uiDeltaOffsetTotalSinceTripSt "UI_uiDeltaOffsetTotalSinceTripStart";
BA_ "Confidence" SG_ 1279 UI_uiDeltaOffsetDrivingSinceTrip 0;
BA_ "SystemSignalLongSymbol" SG_ 1279 UI_uiDeltaOffsetDrivingSinceTrip "UI_uiDeltaOffsetDrivingSinceTripStart";
BA_ "Confidence" SG_ 1279 UI_uiDeltaOffsetClimateSinceTrip 0;
BA_ "SystemSignalLongSymbol" SG_ 1279 UI_uiDeltaOffsetClimateSinceTrip "UI_uiDeltaOffsetClimateSinceTripStart";
BA_ "Confidence" SG_ 1279 UI_uiDeltaOffsetBattCondSinceTri 0;
BA_ "SystemSignalLongSymbol" SG_ 1279 UI_uiDeltaOffsetBattCondSinceTri "UI_uiDeltaOffsetBattCondSinceTripStart";
BA_ "Confidence" SG_ 1279 UI_uiDeltaOffsetElevationSinceTr 0;
BA_ "SystemSignalLongSymbol" SG_ 1279 UI_uiDeltaOffsetElevationSinceTr "UI_uiDeltaOffsetElevationSinceTripStart";
BA_ "Confidence" SG_ 1279 UI_uiDeltaOffsetAccSinceTripStar 0;
BA_ "SystemSignalLongSymbol" SG_ 1279 UI_uiDeltaOffsetAccSinceTripStar "UI_uiDeltaOffsetAccSinceTripStart";
BA_ "Confidence" SG_ 1279 UI_rawToUiEnergyRatioSinceTripSt 0;
BA_ "SystemSignalLongSymbol" SG_ 1279 UI_rawToUiEnergyRatioSinceTripSt "UI_rawToUiEnergyRatioSinceTripStart";
BA_ "Confidence" SG_ 1279 UI_driveDistanceSinceTripStart 0;
BA_ "Confidence" SG_ 1279 UI_trailerMass 0;
BA_ "Confidence" SG_ 563 UI_gearRequest 0;
BA_ "GenSigSNA" SG_ 563 UI_gearRequest "0";
BA_ "Confidence" SG_ 563 UI_fullScreenMode 1;
BA_ "Confidence" SG_ 563 UI_gearStripShowing 1;
BA_ "Confidence" SG_ 563 UI_gearStripForceShow 1;
BA_ "Confidence" SG_ 563 UI_autoParkAvailable 1;
BA_ "Confidence" SG_ 563 UI_gearStripSuppressActive 1;
BA_ "Confidence" SG_ 563 UI_gearNeutralPressed 1;
BA_ "Confidence" SG_ 699 UI_centerDisplayRunning 0;
BA_ "Confidence" SG_ 699 UI_centerDisplayPowerOn 0;
BA_ "Confidence" SG_ 661 UI_systemMonitorIndex 1;
BA_ "Confidence" SG_ 661 UI_SystemMemUsage 0;
BA_ "Confidence" SG_ 661 UI_QtCarMemUsage 0;
BA_ "Confidence" SG_ 661 UI_QtCarCPUUsage 0;
BA_ "Confidence" SG_ 661 UI_SystemCPUUsage 0;
BA_ "Confidence" SG_ 139 UI_maxSpeedToReachDestination 0;
BA_ "GenSigSNA" SG_ 139 UI_maxSpeedToReachDestination "65535";
BA_ "Confidence" SG_ 139 UI_timeToDestination 0;
BA_ "GenSigSNA" SG_ 139 UI_timeToDestination "65535";
BA_ "Confidence" SG_ 1173 UI_predictedEnergy 0;
BA_ "GenSigSNA" SG_ 1173 UI_predictedEnergy "32768";
BA_ "Confidence" SG_ 1173 UI_hindsightEnergy 0;
BA_ "GenSigSNA" SG_ 1173 UI_hindsightEnergy "32768";
VAL_ 943 BB_sOutputRodQF 2 "Faulty" 1 "Normal" 0 "NotInit_orOff" ;
VAL_ 943 BB_sInputRodQF 2 "Faulty" 1 "Normal" 0 "NotInit_orOff" ;
VAL_ 943 BB_driverBrakeApply 1 "DRIVER_APPLYING_BRAKES" 0 "BRAKES_NOT_APPLIED" ;
VAL_ 943 BB_driverBrakeApplyQF 2 "Faulty" 1 "Normal" 0 "NotInit_orOff" ;
VAL_ 943 BB_boosterStatus 6 "ACTUATION" 5 "READY" 4 "ACTIVE_GOOD_CHECK" 3 "DIAGNOSTIC" 2 "FAILURE" 1 "INIT" 0 "OFF" ;
VAL_ 943 BB_warningLampRequest 2 "RED_BRAKE_LAMP_REQUEST" 1 "YELLOW_BRAKE_LAMP_REQUEST" 0 "NO_LAMP_REQUEST" ;
VAL_ 943 BB_brakeFluidLevel 3 "BRAKE_FLUID_LEVEL_INVALID" 2 "BRAKE_FLUID_LEVEL_NORMAL" 1 "BRAKE_FLUID_LEVEL_LOW" 0 "BRAKE_FLUID_LEVEL_UNKNOWN" ;
VAL_ 943 BB_internalState 7 "READY_TO_SHUTDOWN" 6 "POST_DRIVE_CHECK" 5 "TRANSITION_TO_IDLE" 4 "DIAGNOSTIC" 3 "EXTERNAL_BRAKE_REQUEST" 2 "LOCAL_BRAKE_REQUEST" 1 "PRE_DRIVE_CHECK" 0 "NO_MODE_ACTIVE" ;
VAL_ 2029 BMS_10HzDebug_Id 34 "AGED_SOC_OCV" 33 "THM_TARGETS" 32 "SOC_AND_OCV" 31 "DRIVE_LIMITS" 30 "STANDBY_SUPPLY" 29 "SLEEP_WAKE" 28 "POWER_PREDICTION_3" 27 "POWER_PREDICTION_2" 26 "POWER_PREDICTION_1" 25 "ADC_FLOOD" 24 "ADC_MISC" 23 "ADC_DCLINK" 22 "ADC_CP" 21 "ADC_VREF" 20 "WAKE_TIMERS" 19 "CAC_3" 18 "CAC_2" 17 "CAC_1" 16 "HYST" 15 "PACK_VOLTAGES" 14 "THM_MODEL_DATA_11" 13 "THM_MODEL_DATA_10" 12 "THM_MODEL_DATA_9" 3 "SOC_RESTING" 2 "ISOLATION" 1 "AHR_COUNTER" 0 "STATE" ;
VAL_ 2028 BMS_cellTempTargetMode 11 "V2X_SESSION" 10 "PASSIVE_COOL_ON_NAV" 9 "ACTIVE_COOL_ON_NAV" 8 "SOH_HEAT_PACK" 7 "DRAGSTRIP" 6 "PASSIVE_HEAT_ON_NAV" 5 "ACTIVE_HEAT_ON_NAV" 4 "DISCONNECTED_PRECONDITION" 3 "CONNECTED_PRECONDITION" 2 "HIGH_POWER_CHARGE" 1 "LOW_POWER_CHARGE" 0 "DEFAULT" ;
VAL_ 282 GTW_BKP_BATT_MON 4095 "SNA" ;
VAL_ 282 GTW_BKP_BATT_NTC_P 4095 "SNA" ;
VAL_ 282 GTW_ECALL_GPS_ANT_BIAS 4095 "SNA" ;
VAL_ 282 GTW_ECALL_MIC_DIAG 4095 "SNA" ;
VAL_ 282 GTW_SOS_ECALL_nRQST_BUF 4095 "SNA" ;
VAL_ 838 GTW_autopilotOverrideState 3 "TIMEBOUND_SUBSCRIPTION" 2 "TRIAL" 1 "SUBSCRIPTION" 0 "BASE" ;
VAL_ 838 GTW_autopilotConfig 4 "BASIC" 3 "SELF_DRIVING" 2 "ENHANCED" 1 "HIGHWAY" 0 "NONE" ;
VAL_ 838 GTW_autopilotOverrideConfig 4 "BASIC" 3 "SELF_DRIVING" 2 "ENHANCED" 1 "HIGHWAY" 0 "NONE" ;
VAL_ 904 GTW_VEH_faultConfinement 2 "BUS_OFF" 1 "ERROR_PASSIVE" 0 "ERROR_ACTIVE" ;
VAL_ 904 GTW_PARTY_faultConfinement 2 "BUS_OFF" 1 "ERROR_PASSIVE" 0 "ERROR_ACTIVE" ;
VAL_ 904 GTW_CH_faultConfinement 2 "BUS_OFF" 1 "ERROR_PASSIVE" 0 "ERROR_ACTIVE" ;
VAL_ 2047 GTW_deliveryStatus 1 "DELIVERED" 0 "NOT_DELIVERED" ;
VAL_ 2047 GTW_cabinPTCHeaterType 1 "NONE" 0 "BORGWARNER" ;
VAL_ 2047 GTW_rightHandDrive 1 "RIGHT" 0 "LEFT" ;
VAL_ 2047 GTW_rearLightType 2 "GLOBAL" 1 "EU_CN" 0 "NA" ;
VAL_ 2047 GTW_headlamps 2 "GLOBAL" 1 "PREMIUM" 0 "BASE" ;
VAL_ 2047 GTW_tireType 38 "HANKOOK_SUMMER_18" 37 "GITI_SUMMER_18" 36 "KUMHO_ALL_SEASON_18" 35 "GOODYEAR_ALL_SEASON_18" 34 "CONTI_SUMMER_19" 33 "BRIDGESTONE_ALL_SEASON_20" 32 "HANKOOK_ALL_SEASON_20" 31 "GOODYEAR_SUMMER_19" 30 "KUMHO_ALL_SEASON_19" 29 "HANKOOK_ALL_SEASON_21" 28 "PIRELLI_ALL_SEASON_19" 27 "GOODYEAR_ALL_SEASON_21" 26 "HANKOOK_ALL_SEASON_18" 25 "PIRELLI_ALL_SEASON_22" 24 "CONTI_SUMMER_22" 23 "CONTI_ALL_SEASON_20" 22 "MICHELIN_SUMMER_21" 21 "PIRELLI_SUMMER_20" 20 "PIRELLI_SUMMER_19" 19 "MICHELIN_ALL_SEASON_21" 18 "PIRELLI_SUMMER_21" 17 "GOODYEAR_ALL_SEASON_20" 16 "BRIDGESTONE_SUMMER_18" 7 "GOODYEAR_ALL_TERRAIN_20" 6 "PIRELLI_ALL_SEASON_20" 5 "MICHELIN_SUMMER_20" 4 "CONTI_ALL_SEASON_19" 3 "HANKOOK_SUMMER_19" 2 "MICHELIN_SUMMER_18" 1 "MICHELIN_ALL_SEASON_18" 0 "UNKNOWN" ;
VAL_ 2047 GTW_roofGlassType 3 "UNCOATED" 2 "NONE" 1 "TSA5_NOPET" 0 "TSA3_PET" ;
VAL_ 2047 GTW_dasHw 5 "TESLA_AP4" 4 "TESLA_AP3" 3 "PARKER_PASCAL_2_5" ;
VAL_ 2047 GTW_brakeHWType 21 "HITACHI_P42_V2_MANDO_43MOC_LOW_DRAG" 20 "BREMBO_LARGE_P42_V2_MANDO_43MOC_LOW_DRAG" 18 "BREMBO_LARGE_P42_V2_BREMBO_44MOC_GA" 17 "HITACHI_P42_V2_MANDO_43MOC" 16 "BREMBO_P42LD_V2_MANDO_43MOC" 15 "BREMBO_P42LD_ZF_43MOC" 13 "BREMBO_P42_ZF_43MOC" 9 "BREMBO_P42_V2_MANDO_43MOC" 8 "BREMBO_LARGE_P42_V2_MANDO_43MOC" 7 "BREMBO_LARGE_P42_V2_BREMBO_LARGE_44MOC" 6 "BREMBO_LARGE_P42_V2_BREMBO_44MOC" 3 "BREMBO_LARGE_P42_BREMBO_LARGE_44MOC" 2 "BREMBO_LARGE_P42_MANDO_43MOC" 1 "BREMBO_LARGE_P42_BREMBO_44MOC" 0 "BREMBO_P42_MANDO_43MOC" ;
VAL_ 2047 GTW_restraintsHardwareType 239 "NA_NO_KAB_MYB" 238 "ROW_ECALL_E41_MYB" 237 "EU_ECALL_E41_MYB" 236 "NA_E41_MYB" 233 "NA_MYL" 232 "ECE_ECALL_PEDPRO_MYL" 89 "ROW_ECALL_PEDPRO_MYL" 88 "ROW_PEDPRO_MYB" 87 "ROW_PERF_ECALL_PEDPRO_MYB" 86 "EU_PERF_ECALL_PEDPRO_MYB" 85 "EU_ECALL_PEDPRO_MYB" 84 "ROW_ECALL_PEDPRO_MYB" 83 "ROW_MYB" 82 "ROW_ECALL_MYB" 81 "NA_MYB" ;
VAL_ 2047 GTW_drivetrainType 1 "AWD" 0 "RWD" ;
VAL_ 2047 GTW_radarHeaterType 1 "MODELY_BACKER_THIN_3M" 0 "NONE" ;
VAL_ 2047 GTW_exteriorTrimType 1 "SATIN_BLACK" 0 "STANDARD_CHROME" ;
VAL_ 2047 GTW_frontSeatHeaters 1 "KONGSBERG_LOW_POWER" 0 "NONE" ;
VAL_ 2047 GTW_rearSeatHeaters 1 "KONGSBERG_LOW_POWER" 0 "NONE" ;
VAL_ 2047 GTW_eCallAntennaHW 1 "MAIN_ANT_ONLY" 0 "BACKUP_OR_MAIN_ANT" ;
VAL_ 2047 GTW_homelinkType 1 "HOMELINK_V_OPT_2" 0 "NONE" ;
VAL_ 2047 GTW_vdcType 1 "TESLA_VDC" 0 "BOSCH_VDC" ;
VAL_ 2047 GTW_memoryMirrors 1 "SMR" 0 "NOT_INSTALLED" ;
VAL_ 2047 GTW_powerLiftgateType 2 "HUADE_REV1" 1 "TESLA_REV1" 0 "NOT_INSTALLED" ;
VAL_ 2047 GTW_lumbarECUType 10 "AEW_SINGLE_AXIS_DRIVER_ONLY_RHD" 9 "AEW_SINGLE_AXIS_DRIVER_ONLY_LHD" 8 "ND_DRIVER_ONLY_RHD" 7 "ND_DRIVER_ONLY_LHD" 6 "AEW_DRIVER_ONLY_RHD" 5 "AEW_DRIVER_ONLY_LHD" 4 "AEW" 3 "ALFMEIER_DRIVER_ONLY_RHD" 2 "ALFMEIER_DRIVER_ONLY_LHD" 1 "ALFMEIER" 0 "NONE" ;
VAL_ 2047 GTW_rearSeatHeaterType 3 "LEFT_RIGHT_ONLY_GENTHERM" 2 "NONE" 1 "LEFT_RIGHT_ONLY_KONGSBERG" ;
VAL_ 2047 GTW_auxParkLamps 3 "NONE" 2 "EU" 1 "NA_PREMIUM" 0 "NA_BASE" ;
VAL_ 2047 GTW_interiorCabinRadarType 1 "TESLA" 0 "NONE" ;
VAL_ 2047 GTW_hvacPanelVaneType 1 "CONVERGENT_V1" 0 "PARALLEL_V1" ;
VAL_ 2047 GTW_intakeAirFilterType 1 "HEPA" 0 "STANDARD" ;
VAL_ 2047 GTW_eBuckConfig 1 "DEV_BUCK" 0 "NONE" ;
VAL_ 2047 GTW_steeringHeaterEnabled 1 "ENABLED" 0 "DISABLED" ;
VAL_ 2047 GTW_activeHighBeam 1 "ACTIVE" 0 "NOT_ACTIVE" ;
VAL_ 2047 GTW_airbagCutoffSwitch 1 "CUTOFF_SWITCH_ENABLED" 0 "CUTOFF_SWITCH_DISABLED" ;
VAL_ 2047 GTW_intrusionSensorType 1 "VODAFONE" 0 "NOT_INSTALLED" ;
VAL_ 2047 GTW_spoilerType 1 "PASSIVE" 0 "NOT_INSTALLED" ;
VAL_ 2047 GTW_rearFogLamps 1 "INSTALLED" 0 "NOT_INSTALLED" ;
VAL_ 2047 GTW_roofType 1 "FIXED_GLASS" ;
VAL_ 2047 GTW_thirdRowSeatType 1 "FLAT_FOLD" 0 "NONE" ;
VAL_ 2047 GTW_autopilot 4 "BASIC" 3 "SELF_DRIVING" 2 "ENHANCED" 1 "HIGHWAY" 0 "NONE" ;
VAL_ 2047 GTW_superchargingAccess 2 "PAY_AS_YOU_GO" 1 "ALLOWED" 0 "NOT_ALLOWED" ;
VAL_ 2047 GTW_exteriorColor 20 "COASTAL_BLUE" 17 "MARINE_BLUE" 16 "SILKROAD_SILVER" 15 "DIAMOND_BLACK" 14 "GLACIER_BLUE" 13 "FROST_BLUE" 11 "STEALTH_GREY" 10 "ULTRA_RED" 9 "QUICKSILVER" 8 "ABYSS_BLUE" 7 "MIDNIGHT_CHERRY_RED" 6 "PEARL_WHITE" 5 "DEEP_BLUE" 3 "MIDNIGHT_SILVER" 2 "SILVER_METALLIC" 1 "SOLID_BLACK" 0 "RED_MULTICOAT" ;
VAL_ 2047 GTW_pedestrianWarningSound 2 "EXT_SPEAKER_V2" 1 "SPEAKER" 0 "NONE" ;
VAL_ 2047 GTW_steeringColumnUJointType 1 "C_SAMPLE_PHASING" ;
VAL_ 2047 GTW_bPillarNFCParam 1 "MODEL_Y" 0 "MODEL_3" ;
VAL_ 2047 GTW_interiorLighting 6 "FOOTWELL" 5 "FOOTWELL_RGB_IP" 4 "PREMIUM_WITH_RGB_IP_ONLY" 3 "PREMIUM_WITH_RGB" 2 "PREMIUM_NO_POCKET_LIGHT" 1 "PREMIUM" 0 "BASE" ;
VAL_ 2047 GTW_headlightLevelerType 2 "VIRTUAL_PITCH_SENSOR" 1 "GEN1" 0 "NONE" ;
VAL_ 2047 GTW_numberHVILNodes 3 "HVIL_NODES_3" 2 "HVIL_NODES_2" 0 "HVIL_NODES_0" ;
VAL_ 2047 GTW_mapRegion 13 "LA" 12 "IN" 11 "SE" 10 "MO" 9 "HK" 8 "ME" 7 "KR" 6 "TW" 5 "JP" 4 "AU" 3 "CN" 2 "NONE" 1 "EU" 0 "US" ;
VAL_ 2047 GTW_performancePackage 4 "BASE_2022" 3 "BASE_PLUS" 2 "BASE_2024" 1 "PERFORMANCE" 0 "BASE" ;
VAL_ 2047 GTW_chassisType 7 "MODEL_Y_LONG_WHEELBASE_CHASSIS_PATRONUS" 3 "MODEL_Y_CHASSIS" 2 "MODEL_3_CHASSIS" ;
VAL_ 2047 GTW_airSuspension 3 "COIL_ADAPTIVE_DAMPING" 0 "NONE" ;
VAL_ 2047 GTW_centerConsoleControllerType 2 "INSTALLED_NO_AIRWAVE" 1 "INSTALLED_V1" 0 "NONE" ;
VAL_ 2047 GTW_autopilotCameraType 1 "RGGB_CAMERAS" 0 "RCCB_CAMERAS" ;
VAL_ 2047 GTW_connectivityPackage 1 "PREMIUM" 0 "BASE" ;
VAL_ 2047 GTW_plcSupportType 2 "NATIVE_CHARGE_PORT" 1 "ONBOARD_ADAPTER" 0 "NONE" ;
VAL_ 2047 GTW_packEnergy 2 "MR" 1 "LR" 0 "SR" ;
VAL_ 2047 GTW_frontSeatReclinerHardware 3 "LEFT_RIGHT_SEAT_REDUCED_RANGE" 2 "LEFT_SEAT_REDUCED_RANGE" 1 "RIGHT_SEAT_REDUCED_RANGE" 0 "STANDARD_RANGE" ;
VAL_ 2047 GTW_brakeLineSwitchType 1 "VC_ONLY" 0 "DI_VC_SHARED" ;
VAL_ 2047 GTW_softRange 4 "RANGE_260_MILES" 3 "RANGE_343_MILES" 2 "RANGE_93_MILES" 1 "RANGE_220_MILES" 0 "STANDARD" ;
VAL_ 2047 GTW_refrigerantType 2 "R1234YF" 1 "R134A" 0 "Default" ;
VAL_ 2047 GTW_wheelType 52 "UBERHELIX_20" 51 "GEMINI_19_DARK_STAGGERED" 50 "HELIX_V2_20_DARK" 48 "MACHINA_V2_19_STAGGERED" 47 "GLIDER_18_CAP_KIT" 46 "APERTURE_18" 41 "ARACHNID_V2_21" 40 "HELIX_V2_20" 39 "CROSSFLOW_19" 33 "WISHBONE_20_STAGGERED" 31 "HELIX_19" 30 "GLIDER_18" 27 "ZEROG_19_GUNPOWDER" 24 "PINWHEEL_REFRESH_18_CAP_KIT" 23 "UBERTURBINE_20_GUNPOWDER" 22 "PINWHEEL_REFRESH_18" 21 "STILETTO_REFRESH_19" 19 "ZEROG_20_GUNPOWDER" 18 "PINWHEEL_18_CAP_KIT" 14 "STILETTO_20_DARK_SQUARE" 5 "GEMINI_19_STAGGERED" 4 "GEMINI_19_SQUARE" 3 "STILETTO_20_DARK_STAGGERED" 2 "STILETTO_20" 1 "STILETTO_19" 0 "PINWHEEL_18" ;
VAL_ 2047 GTW_brakeActuationType 2 "ESP_DPB" 1 "IDB_RCU" 0 "ESP_IBST" ;
VAL_ 2047 GTW_secondRowSeatType 6 "TWO_SEATS_POWERED_RECLINE" 5 "FLAT_FOLD_V2" 4 "EASY_ENTRY_POWERED_RECLINE" 3 "POWERED_RECLINE" ;
VAL_ 2047 GTW_secondRowSeatMotorType 1 "KEIPER" 0 "SHB" ;
VAL_ 2047 GTW_eCallEnabled 2 "ENABLED_UI_SOS" 1 "ENABLED_OHC_SOS" 0 "DISABLED" ;
VAL_ 2047 GTW_parkAssistECUType 2 "NONE" 1 "TESLA" 0 "VALEO" ;
VAL_ 2047 GTW_passengerAirbagType 2 "EUROW" 1 "SAFETY_VENT" 0 "FULL_SUPPRESSION" ;
VAL_ 2047 GTW_forwardRadarHw 2 "NONE" 0 "CONTI_ARS410" ;
VAL_ 2047 GTW_frontSeatType 13 "PREMIUM_L_YANFENG_MINITILT_R_TESLA_MINITILT" 12 "PREMIUM_L_YANFENG_MINITILT_R_YANFENG_MINITILT" 11 "PREMIUM_L_YANFENG_MINITILT_R_YANFENG" 10 "PREMIUM_L_YANFENG_R_YANFENG_MINITILT" 9 "PREMIUM_L_TESLA_MINITILT_R_YANFENG_MINITILT" 8 "PREMIUM_L_TESLA_MINITILT_R_TESLA_MINITILT" 7 "PREMIUM_L_TESLA_MINITILT_R_TESLA" 6 "PREMIUM_L_TESLA_R_TESLA_MINITILT" 5 "PREMIUM_BROSE" 4 "PREMIUM_YANFENG" 3 "PREMIUM_L_TESLA_R_YANFENG" 2 "PREMIUM_L_YANFENG_R_TESLA" 1 "PREMIUM_TESLA" 0 "BASE_TESLA" ;
VAL_ 2047 GTW_secondRowDisplayType 1 "TYPE_1" 0 "NONE" ;
VAL_ 2047 GTW_wirelessPhoneChargerType 3 "FRONT_HIGH_POWER_UART" 1 "FRONT_LIN" 0 "NONE_OR_USB" ;
VAL_ 2047 GTW_ethernetTunerType 3 "HARMAN_GEN3" 2 "HIRSCHMANN" 1 "NONE" 0 "HARMAN" ;
VAL_ 2047 GTW_interiorTrimType 3 "WHITE_CONSOLE_2" 2 "BLACK_CONSOLE_2" 1 "WHITE" 0 "BLACK" ;
VAL_ 2047 GTW_gloveboxUSBType 2 "TSC_USB3_A_PLUS_BT" 1 "TSC_USB3_A" 0 "NOT_INSTALLED" ;
VAL_ 2047 GTW_coolantPumpType 5 "DUAL_MIX" 4 "DUAL_SAN_P4_LUB" 2 "DUAL_SAN_P4" 1 "SINGLE_PUMP_BATT" 0 "DUAL" ;
VAL_ 2047 GTW_epblHwType 8 "ZF" 5 "BREMBO_V2" 4 "BREMBO_V1" 2 "MANDO_V2" 1 "MANDO_V1" 0 "NOT_SET" ;
VAL_ 2047 GTW_epbrHwType 8 "ZF" 5 "BREMBO_V2" 4 "BREMBO_V1" 2 "MANDO_V2" 1 "MANDO_V1" 0 "NOT_SET" ;
VAL_ 2047 GTW_blowerMotorType 1 "DELTA" 0 "SHINANO" ;
VAL_ 2047 GTW_frontUsbHubType 4 "NO_DATA" 0 "2" ;
VAL_ 2047 GTW_superManifoldType 2 "TYPE2" 1 "TYPE1" 0 "TYPE0" ;
VAL_ 2047 GTW_rcmLocation 0 "CENTER_CONSOLE" ;
VAL_ 2047 GTW_interiorCamFanType 3 "NIDEC" 2 "DELTA_FDB" 0 "NONE" ;
VAL_ 2047 GTW_sirenType 1 "VODAPHONE_IF_INTRUSION" 0 "NONE" ;
VAL_ 2047 GTW_hornType 1 "EXT_SPEAKER_V2" 0 "TRUMPET" ;
VAL_ 2047 GTW_badgingVersion 1 "VERSION_1" 0 "VERSION_0" ;
VAL_ 2047 GTW_steeringColumnMotorType 3 "NEXTEER" 2 "BOSCH_COMMON_TO_JE" 1 "JE" 0 "BOSCH" ;
VAL_ 2047 GTW_refrigACLineType 2 "CONTI_LIMITED" 1 "SAAA_LIMITED" 0 "UNLIMITED" ;
VAL_ 2047 GTW_refrigFilterType 2 "BLOCKED_V2" 1 "BLOCKED_V1" 0 "UNBLOCKED" ;
VAL_ 2047 GTW_diBurnInType 1 "ENABLED_V1" 0 "NONE" ;
VAL_ 2047 GTW_specialBadgingType 2 "LAUNCH_SERIES" 0 "NONE" ;
VAL_ 2047 GTW_chassisSubType 3 "TRIM_DEVIATION_1" 2 "PERFORMANCE" 1 "BASE" 0 "UNKNOWN" ;
VAL_ 2047 GTW_frontSeatVentilationType 1 "TYPE_1" 0 "NONE" ;
VAL_ 2047 GTW_towPackage 2 "TESLA_REV2" 1 "TESLA_REV1" 0 "NONE" ;
VAL_ 2047 GTW_refrigLccType 1 "LCCR" 0 "LCC" ;
VAL_ 2047 GTW_caliperColorType 2 "RED" 1 "GREY" 0 "UNKNOWN" ;
VAL_ 2047 GTW_wiperMotorType 1 "SHB" 0 "NOT_UPDATEABLE" ;
VAL_ 2047 GTW_frontOverheadConsoleType 3 "KOSTAL" 2 "PREH" 1 "BITRON" 0 "VALEO" ;
VAL_ 2047 GTW_shifterType 1 "DISPLAY" 0 "STALK" ;
VAL_ 2047 GTW_compressorType 10 "SANDEN_V4_1" 8 "SANDEN_V4" 7 "SANDEN_V3" 6 "SANDEN_V1_1" 5 "SANDEN_V2" 4 "DENSO_11K_COP1_ENABLED" 3 "SANDEN" 2 "DENSO_41CC_11K" 1 "DENSO_41CC_8K" 0 "HANON_33CC" ;
VAL_ 2047 GTW_twelveVBatteryType 3 "TESLA_16V_LI_ION" 2 "CATL_LI_ION" 1 "CLARIOS_B24_FLOODED" 0 "ATLASBX_B24_FLOODED" ;
VAL_ 2047 GTW_efuseSWConfig 3 "ALL_ENABLED" 2 "SQUARE_ENABLED" 1 "ROUND_ENABLED" 0 "DISABLED" ;
VAL_ 2047 GTW_tollCollectionModuleType 1 "WANJI_V1" 0 "NONE" ;
VAL_ 2047 GTW_bleEndpointUpdateMethod 1 "BOOTLOADER_UPDATE" ;
VAL_ 2047 GTW_steeringWheelControllerType 5 "DUAL_TESLA_GEN5" 2 "DUAL_KOSTAL" 1 "DUAL_PREH" ;
VAL_ 2047 GTW_frontSeatVentilationEnabled 1 "ENABLED" 0 "DISABLED" ;
VAL_ 2047 GTW_gloveboxActuatorType 2 "ELECTROMAGNET" 1 "SMA" 0 "SOLENOID" ;
VAL_ 2047 GTW_epasType 8 "THYSSENKRUPP_CGR65" 7 "MANDO_CGR65" 6 "THYSSENKRUPP_VGR69" 5 "MANDO_CGR69_SINGLE_ECU" 4 "MANDO_CGR69" 3 "MANDO_VGR69_GEN3_SINGLE_ECU" 0 "MANDO_VGR69_GEN3" ;
VAL_ 2047 GTW_homologationRegionOverride 2 "MX_UNECE" 1 "KR_UNECE" 0 "DEFAULT_FOR_COUNTRY_CODE" ;
VAL_ 2047 GTW_windowCommandsPermissionType 2 "US_FMVSS_S6" 1 "US_FMVSS_S4" 0 "ROW_OR_US_FMVSS_S5" ;
VAL_ 2047 GTW_rgbInteriorLightingEnabled 2 "ALL_COLORS" 1 "WHITE_ONLY" 0 "DISABLED_OR_NA" ;
VAL_ 2047 GTW_windshieldWiperHeaterType 1 "TYPE_1" 0 "NOT_INSTALLED" ;
VAL_ 2047 GTW_driveInterfaceType 1 "EXTERNAL" 0 "COMBINED" ;
VAL_ 2047 GTW_efficiencyPackage 42 "MY_2026_US" 39 "MY_2025_CN_PLUS" 38 "MY_2026_M53" 34 "MY_STANDARD_2026" 33 "MY_REFRESH_2025_CN_ALL_US_LR_RWD" 32 "MY_REFRESH_2025_ROW" 24 "MY_2024_GFSH_EXPORT_NA_SR_RWD" 23 "MY_2024C" 20 "MY_2023_SR_RWD" 16 "MY_2024" 15 "MY_2023_GFSH_EXPORT_NA" 12 "MY_RWD_EU_2022" 11 "MY_SR_PLUS_2022_Q1_TX" 9 "MY_SR_PLUS_2021_Q3_GFSH" 7 "MY_2021" 5 "MY_2020" 0 "DEFAULT" ;
VAL_ 2047 GTW_visorLightType 1 "DIMMABLE_TYPE_1" 0 "NON_DIMMABLE" ;
VAL_ 2047 GTW_gnssAntennaType 2 "GEN2_WITH_METAL_INSERT" 1 "GEN2_NO_METAL_INSERT" 0 "NA_OR_GEN1" ;
VAL_ 2047 GTW_frontSeatHeatersEnabled 1 "ENABLED" 0 "DISABLED" ;
VAL_ 2047 GTW_windshieldWiperHeaterEnabled 1 "ENABLED_OR_NA" 0 "DISABLED" ;
VAL_ 2047 GTW_tcuType 1 "5G" 0 "4G" ;
VAL_ 2047 GTW_fasciaType 8 "E41_BAYBERRY" 4 "PERFORMANCE_BAYBERRY" 3 "BASE_BAYBERRY" 0 "ORIGINAL" ;
VAL_ 2047 GTW_powerSteeringColumn 1 "TK" 0 "NOT_INSTALLED" ;
VAL_ 2047 GTW_frontSeatHeaterType 1 "GENTHERM" 0 "KONGSBERG" ;
VAL_ 2047 GTW_softPerformanceLimit 6 "LIMIT_230_KW" 4 "LIMIT_110_MPH" 2 "LIMIT_110_KW" 1 "LIMIT_160_KW" 0 "NONE" ;
VAL_ 2047 GTW_alcoholInterlockType 1 "TYPE_1" 0 "NONE" ;
VAL_ 2047 GTW_immersiveAudio 2 "PREMIUM" 1 "BASE" 0 "DISABLED" ;
VAL_ 2047 GTW_passengerOccupancySensorType 4 "NONE" 1 "RESISTIVE_PAD" 0 "OCS" ;
VAL_ 2047 GTW_packPerformanceDeviation 5 "PACK_POWER_DEVIATION_2" 4 "PACK_MASS_DEVIATION_2" 3 "PACK_STRUCTURAL_DEVIATION_1" 2 "PACK_POWER_DEVIATION_1" 1 "PACK_MASS_DEVIATION_1" 0 "NO_DEVIATION" ;
VAL_ 2047 GTW_frontFogLamps 1 "INSTALLED" 0 "NOT_INSTALLED" ;
VAL_ 2047 GTW_driverOccupancySensorType 1 "NONE" 0 "RESISTIVE_PAD" ;
VAL_ 2047 GTW_audioType 4 "ESSENTIAL_WITH_COMMODITY100" 3 "ESSENTIAL" 1 "PREMIUM" 0 "BASE" ;
VAL_ 2047 GTW_occupancyClassificationFeatu 1 "TESLA_CABIN_RADAR" 0 "DISCRETE_SENSOR_OR_NA" ;
VAL_ 2047 GTW_domeLightType 2 "TESLA_2R" ;
VAL_ 2047 GTW_tpmsType 2 "INDIRECT" 1 "TESLA_BLE" 0 "CONTI_2" ;
VAL_ 2047 GTW_authenticationEndpointLayout 2 "MY_LAYOUT_2" 1 "M3_LAYOUT_2" 0 "LAYOUT_1" ;
VAL_ 2047 GTW_socSleepOverride 2 "FORCE_SHALLOW" 1 "FORCE_S3" 0 "PN_DERIVED" ;
VAL_ 2047 GTW_r79BehaviorOverride 1 "R79_ENABLED" 0 "NO_OVERRIDE" ;
VAL_ 2047 GTW_steeringHeaterType 7 "YF_V2" 4 "ZF_ROUND" 0 "NONE" ;
VAL_ 2047 GTW_sohRegulatoryStatus 1 "REGULATED_SOH" 0 "NON_REGULATED_SOH" ;
VAL_ 2047 GTW_m3yBusArchitecture 2 "PRIVATE_TORQUE_CHASSIS" 1 "PRIVATE_TORQUE" 0 "PUBLIC_TORQUE" ;
VAL_ 2047 GTW_blindSpotIndicatorLightType 1 "INSTALLED_TYPE_1" 0 "NOT_INSTALLED" ;
VAL_ 2047 GTW_hvacCaseDoorType 1 "FLAT_EDGE" 0 "SERRATED_EDGE" ;
VAL_ 2047 GTW_rduCableType 1 "COPPER" 0 "ALUMINUM" ;
VAL_ 2047 GTW_interiorCameraType 1 "VD6763" 0 "AR0136" ;
VAL_ 2047 GTW_frontFasciaCameraType 2 "IMX00N" 1 "IMX963" 0 "NONE" ;
VAL_ 1638 GTW_diagLevel 100 "LEVEL_NORMAL_OPERATION" 80 "LEVEL_PARK" 70 "LEVEL_PARK_ROBOTAXI" 50 "LEVEL_SERVICE_DRIVE" 25 "LEVEL_SERVICE" 10 "LEVEL_DIAG_LINK_ACTIVE" 0 "LEVEL_FACTORY" ;
VAL_ 1080 GTW_ethWakeUpReason 15 "GTW_WAKEUP_REASON_RCMPRIVATE_CAN" 14 "GTW_WAKEUP_REASON_VCLEFT" 13 "GTW_WAKEUP_REASON_LOOP" 12 "GTW_WAKEUP_REASON_DISPLAY_TAP" 11 "GTW_WAKEUP_REASON_URGENT_TRANSMIT_ALERT" 10 "GTW_WAKEUP_REASON_BDY_CAN" 9 "GTW_WAKEUP_REASON_PT_CAN" 8 "GTW_WAKEUP_REASON_UI_SCHEDULED" 7 "GTW_WAKEUP_REASON_RTC_ALARM" 6 "GTW_WAKEUP_REASON_VCFRONT" 5 "GTW_WAKEUP_REASON_VEH_CAN" 4 "GTW_WAKEUP_REASON_ETH_CAN" 3 "GTW_WAKEUP_REASON_CH_CAN" 2 "GTW_WAKEUP_REASON_GSM_RI" 1 "GTW_WAKEUP_REASON_RESET" 0 "GTW_WAKEUP_REASON_NONE" ;
VAL_ 1656 GTW_gearShiftRequest 4 "GEAR_REQUEST_DRIVE" 3 "GEAR_REQUEST_NEUTRAL" 2 "GEAR_REQUEST_REVERSE" 1 "GEAR_REQUEST_PARK" 0 "GEAR_REQUEST_IDLE_SNA" ;
VAL_ 1656 GTW_primaryGearControlStatus 14 "NOT_QUALIFIED_RHD_CONFIG_UNAVAILABLE" 13 "NOT_QUALIFIED_DISPLAY_KNOWN_FROZEN_SCREEN" 12 "NOT_QUALIFIED_DISPLAY_ASIL_VIDEO_ERROR" 11 "NOT_QUALIFIED_GEAR_STRIP_MISMATCH" 10 "NOT_QUALIFIED_DISPLAY_UNTRAINED" 9 "NOT_QUALIFIED_UI_NO_RESP_GEAR_STRIP" 8 "NOT_QUALIFIED_CENTER_DISP_UI_UNHEALTHY" 7 "NOT_QUALIFIED_DISPLAY_FROZEN_ON_GESTURE" 6 "NOT_QUALIFIED_LOW_BRIGHTNESS" 5 "NOT_QUALIFIED_FALSE_TOUCH" 4 "NOT_QUALIFIED_MANUAL" 3 "NOT_QUALIFIED_DISPLAY_ERRS" 2 "NOT_QUALIFIED_FULLSCREEN" 1 "QUALIFIED" 0 "NOT_QUALIFIED" ;
VAL_ 1656 GTW_autoParkRequest 1 "ACTIVE" 0 "IDLE" ;
VAL_ 1656 GTW_smartShiftStatus 9 "DISABLED_AUDIO_NOT_READY" 8 "DISABLED_OSD_ACTIVATED" 7 "DISABLED_DISQUALIFIED" 6 "DISABLED_FULLSCREEN" 5 "DISABLED_UI_MIA" 4 "DISABLED_CLUSTER_DISP_ERR" 3 "DISABLED_CENTER_DISP_ERR" 2 "DISABLED_UI_CONFIG" 1 "ENABLED" 0 "DISABLED_SNA" ;
VAL_ 1656 GTW_gearStripChangeReason 27 "EBUCK_DISABLE" 26 "SLEEP_DISABLE" 25 "VC_MIA_GRACE_DISABLE" 24 "VC_MIA_ENABLE" 23 "DRIVERLESS_NO_TAKEOVER_DISABLE" 22 "EMERGENCY_OPERATION_ENABLE" 21 "WOT_ENABLE" 20 "PARK_ENGAGED_ENABLE" 19 "MISSING_SPEED_OR_STEERING_ESTIMATE_IN_D_ENABLE" 18 "UI_MIA_ENABLE" 16 "NOT_DRIVE_STATE_DISABLE" 15 "FULLSCREEN_DISABLE" 14 "DEFAULT_DISABLE" 13 "REVERSE_ENABLE" 12 "NEUTRAL_ENABLE" 11 "P_AND_BRAKE_ENABLE" 10 "CHARGING_DISABLE" 9 "CRUISE_ACTIVE_DISABLE" 8 "DI_MIA_ENABLE" 7 "HIGH_ACCEL_DISABLE" 6 "MEDIUM_SPEED_DISABLE" 5 "TRAFFIC_CONTROL_NO_CHANGE" 4 "VERY_LOW_SPEED_ENABLE" 3 "HIGH_STEERING_ANGLE_ENABLE" 2 "HIGH_JERK_ENABLE" 1 "DRIVER_BRAKE_APPLY_ENABLE" 0 "SNA" ;
VAL_ 1656 GTW_screenPCBTemperature 2047 "GTW_I2C_TEMP_SNA" ;
VAL_ 2033 GTW_hrlIndex 2 "Mux2" 1 "Mux1" ;
VAL_ 2033 GTW_hrlState 1 "ENABLED" 0 "DISABLED" ;
VAL_ 2033 GTW_hrlTriggerType 15 "HRL_TRIGGER_NONE" 5 "HRL_TRIGGER_EVENT_EXTERNAL" 4 "HRL_TRIGGER_PSEUDONYMOUS" 3 "HRL_TRIGGER_CONTINUOUS" 2 "HRL_TRIGGER_GAME_MODE" 1 "HRL_TRIGGER_EVENT" 0 "HRL_TRIGGER_UDPAPI" ;
VAL_ 60 GTW_infoIndex 255 "END" 31 "SUBCOMPONENT_GITHASH" 30 "PACKAGE_SN_8_14" 29 "PACKAGE_SN_1_7" 27 "PACKAGE_PN_15_20" 26 "PACKAGE_PN_8_14" 25 "PACKAGE_PN_1_7" 23 "SUBCOMPONENT2" 22 "VARIANTCRC" 20 "UDS_PROTOCOL_BOOTCRC" 19 "VERSION_DEPRECATED" 18 "BOOTLOADER_GITHASH" 17 "APP_GITHASH" 16 "SUBCOMPONENT" 15 "BOOTLOADER_CRC" 14 "BOOTLOADER_SVN" 13 "APP_CRC" 11 "PCBAID_ASSYID_USAGEID" 10 "BUILD_HWID_COMPONENTID" 9 "DEPRECATED_9" 8 "DEPRECATED_8" 7 "DEPRECATED_7" 6 "DEPRECATED_6" 5 "DEPRECATED_5" 4 "DEPRECATED_4" 3 "DEPRECATED_3" 2 "DEPRECATED_2" 1 "DEPRECATED_1" 0 "DEPRECATED_0" ;
VAL_ 60 GTW_buildType 4 "INFO_MFG_BUILD" 3 "INFO_TRACEABLE_CI_BUILD" 2 "INFO_LOCAL_BUILD" 1 "INFO_PLATFORM_BUILD" 0 "INFO_UNKNOWN_BUILD" ;
VAL_ 60 GTW_platformType 255 "GTW_PLATFORM_END" 3 "GTW_PLATFORM_MODEL3" 0 "GTW_PLATFORM_UNKNOWN" ;
VAL_ 1370 GTW_mismatchFaultIndex 4 "Mux4" 3 "Mux3" 2 "Mux2" 1 "Mux1" ;
VAL_ 840 GTW_vehicleVersionMatchStatus 2 "MATCHED" 1 "MISMATCHED" 0 "NOT_CALCULATED_YET" ;
VAL_ 840 GTW_hwtype 3 "TRAVEO2" 2 "SPC58" 1 "MPC57" 0 "SNA" ;
VAL_ 840 GTW_jcanProductName 11 "SEMITRUCKV2" 10 "GOLDENSNITCH" 8 "BAYBERRY" 7 "CYBERTRUCK" 6 "POPPYSEED" 5 "SEMITRUCK" 4 "TAMARIND" 3 "LYCHEE" 2 "MODELY" 1 "MODEL3" 0 "SNA" ;
VAL_ 840 GTW_sentryModeState 6 "SNA" 5 "QUIET" 4 "PANIC" 3 "AWARE" 2 "ARMED" 1 "IDLE" 0 "OFF" ;
VAL_ 840 GTW_socSleepType 2 "SHALLOW" 1 "S3" 0 "SNA" ;
VAL_ 840 GTW_resetType 7 "TOUCHCORE_WATCHDOG" 6 "CANCORE_WATCHDOG" 5 "MAINCORE_WATCHDOG" 4 "WAKE" 3 "BUTTON" 2 "SOFTWARE" 1 "POR" 0 "SNA" ;
VAL_ 1112 GTW_nmKeepAwakeReason 15 "GTW_KEEPAWAKE_REASON_TBD" 7 "GTW_KEEPAWAKE_REASON_TCU_TC10_VERSION_UNSUPPORTED" 6 "GTW_KEEPAWAKE_REASON_TCU_TC10_VERSION_CHECK" 5 "GTW_KEEPAWAKE_REASON_EGGLEFT_LINK_DOWN" 4 "GTW_KEEPAWAKE_REASON_URGENT_TRANSMIT_ALERT" 3 "GTW_KEEPAWAKE_REASON_FCSM_ACTIVE" 2 "GTW_KEEPAWAKE_REASON_GSM_RI" 1 "GTW_KEEPAWAKE_REASON_UI_SCHEDULED" 0 "GTW_KEEPAWAKE_REASON_NONE_SNA" ;
VAL_ 1112 GTW_nmWakeUpReason 15 "GTW_WAKEUP_REASON_RCMPRIVATE_CAN" 14 "GTW_WAKEUP_REASON_VCLEFT" 13 "GTW_WAKEUP_REASON_LOOP" 12 "GTW_WAKEUP_REASON_DISPLAY_TAP" 11 "GTW_WAKEUP_REASON_URGENT_TRANSMIT_ALERT" 10 "GTW_WAKEUP_REASON_BDY_CAN" 9 "GTW_WAKEUP_REASON_PT_CAN" 8 "GTW_WAKEUP_REASON_UI_SCHEDULED" 7 "GTW_WAKEUP_REASON_RTC_ALARM" 6 "GTW_WAKEUP_REASON_VCFRONT" 5 "GTW_WAKEUP_REASON_VEH_CAN" 4 "GTW_WAKEUP_REASON_ETH_CAN" 3 "GTW_WAKEUP_REASON_CH_CAN" 2 "GTW_WAKEUP_REASON_GSM_RI" 1 "GTW_WAKEUP_REASON_RESET" 0 "GTW_WAKEUP_REASON_NONE" ;
VAL_ 1112 GTW_ethKeepAwakeReason 3 "TCU_TC10_VERSION_UNSUPPORTED" 2 "TCU_TC10_VERSION_CHECK" 1 "URGENT_TRANSMIT_ALERT" 0 "NONE_SNA" ;
VAL_ 1112 GTW_nmDebugWakeUp 2147483648 "WKPU_31" 1073741824 "WKPU_30" 536870912 "WKPU_29" 268435456 "WKPU_28" 134217728 "WKPU_27" 67108864 "WKPU_26" 33554432 "WKPU_25" 16777216 "WKPU_24" 8388608 "WKPU_23" 4194304 "WKPU_22" 2097152 "WKPU_21" 1048576 "WKPU_20" 524288 "WKPU_19" 262144 "WKPU_18" 131072 "WKPU_17" 65536 "WKPU_16" 32768 "WKPU_15" 16384 "WKPU_14" 8192 "WKPU_13" 4096 "WKPU_12" 2048 "WKPU_11" 1024 "WKPU_10" 512 "WKPU_9" 256 "WKPU_8" 128 "WKPU_7" 64 "WKPU_6" 32 "WKPU_5" 16 "WKPU_4" 8 "WKPU_3" 4 "WKPU_2" 2 "WKPU_1" 1 "WKPU_0" 0 "WKPU_NONE" ;
VAL_ 828 IDB_infoIndex 255 "END" 31 "SUBCOMPONENT_GITHASH" 30 "PACKAGE_SN_8_14" 29 "PACKAGE_SN_1_7" 27 "PACKAGE_PN_15_20" 26 "PACKAGE_PN_8_14" 25 "PACKAGE_PN_1_7" 23 "SUBCOMPONENT2" 22 "VARIANTCRC" 20 "UDS_PROTOCOL_BOOTCRC" 19 "VERSION_DEPRECATED" 18 "BOOTLOADER_GITHASH" 17 "APP_GITHASH" 16 "SUBCOMPONENT" 15 "BOOTLOADER_CRC" 14 "BOOTLOADER_SVN" 13 "APP_CRC" 11 "PCBAID_ASSYID_USAGEID" 10 "BUILD_HWID_COMPONENTID" 9 "DEPRECATED_9" 8 "DEPRECATED_8" 7 "DEPRECATED_7" 6 "DEPRECATED_6" 5 "DEPRECATED_5" 4 "DEPRECATED_4" 3 "DEPRECATED_3" 2 "DEPRECATED_2" 1 "DEPRECATED_1" 0 "DEPRECATED_0" ;
VAL_ 463 PM_hvilSystemStatus 3 "SNA" 2 "CLOSED" 1 "OPEN" 0 "DISABLED" ;
VAL_ 1409 TCU_logMux 15 "mdmBusyActive" 14 "mdmSIMStatus" 13 "mdmIMSStatus" 12 "mdmServiceState" 11 "mdmUplinkAvgRage" 10 "mdmUplinkAllowedRate" 9 "mdmSINR" 8 "mdmRSRP" 7 "mdmUplinkQueueSize" 6 "totalResumes" 5 "pwmcap" 4 "pwm" 3 "availableMemory" 2 "mdmCoreTemperature" 1 "cpuUsage" 0 "cpuTemp" ;
VAL_ 1409 TCU_mdmBusyActive 4294967295 "SNA" ;
VAL_ 1056 UIS_logMux 354 "activeAppView" 353 "amdSocPkgPower" 352 "audioA2BRediscoveryCount" 351 "audioMediaBrowsing" 350 "audioMediaPlaying" 349 "audioPWSGain" 348 "audioSource" 347 "audioState" 346 "audioType" 345 "audioVolumeLevel" 344 "backlightUserRequest" 343 "bifrostCPUUsage" 342 "bifrostMemUsage" 341 "bifrostOdinEngineRequests" 340 "bifrostOdinEngineUp" 339 "bluetoothAutoConnectionState" 338 "bluetoothCPUUsage" 337 "bluetoothConnectionState" 336 "bluetoothMemUsage" 335 "bluetoothPairResult" 334 "bluetoothStackRearState" 333 "bluetoothStackState" 332 "boardTemperature" 331 "bootCount" 330 "camBackupDecodeAvgFrametime" 329 "camBackupDecodeFramecount" 328 "camBackupDecodeMaxFrametime" 327 "camBackupDecodeMinFrametime" 326 "cameraBackupFramerate" 325 "cameraBackupLateFrames" 324 "cameraBackupMaxFrametime" 323 "cameraBackupPipeline" 322 "cameraBackupPopup" 321 "cameraBackupStream" 320 "cameraBackupStreamMissing" 319 "cameraBackupStreamQuality" 318 "cameraFrontPipeline" 317 "cameraFrontPopup" 316 "cameraFrontStream" 315 "cameraFrontStreamMissing" 314 "cameraLRepeaterFramerate" 313 "cameraLRepeaterLateFrames" 312 "cameraLRepeaterMaxFrametime" 311 "cameraLRepeaterPipeline" 310 "cameraLRepeaterPopup" 309 "cameraLRepeaterStream" 308 "cameraLRepeaterStreamMissing" 307 "cameraRRepeaterFramerate" 306 "cameraRRepeaterLateFrames" 305 "cameraRRepeaterMaxFrametime" 304 "cameraRRepeaterPipeline" 303 "cameraRRepeaterPopup" 302 "cameraRRepeaterStream" 301 "cameraRRepeaterStreamMissing" 300 "carAssistErrorCode" 299 "carAssistSessionCount" 298 "carAssistState" 297 "cellularLinkManagerState" 296 "centerDispAsilA_lsb" 295 "centerDispAsilA_msb" 294 "centerDispAsilB_lsb" 293 "centerDispAsilB_msb" 292 "centerDisplayEvent" 291 "centerDisplayState" 290 "ceruleanx8664CPUUsage" 289 "ceruleanx8664MemUsage" 288 "chargeOnSolarNoChargeReason" 287 "chromiumadapterCPUUsage" 286 "chromiumadapterMemUsage" 285 "clusterCPUUsage" 284 "clusterDisplayState" 283 "clusterFramesOver100Ms" 282 "clusterFramesOver200Ms" 281 "clusterMaxFrametime" 280 "clusterMeanFPS" 279 "clusterMemUsage" 278 "cobaltlinuxCPUUsage" 277 "cobaltlinuxMemUsage" 276 "compositorFrameMonitorState" 275 "compositorRenderAvgRenderTime" 274 "compositorRenderFrameCount" 273 "compositorRenderFrameRate" 272 "compositorRenderGpuPercentage" 271 "compositorRenderMaxFrameTime" 270 "compositorRenderMaxRenderTime" 269 "compositorRenderMinFrameTime" 268 "compositorRenderMinRenderTime" 267 "cpuTemperature" 266 "dashcamOnboardAvailableMB" 265 "dashcamOnboardMB" 264 "dashcamOnboardSavePressCount" 263 "dashcamOnboardTransferCount" 262 "dashcamSavedToOnboardCount" 261 "dashcamSavedToSavedCount" 260 "dashcamSavedToSentryCount" 259 "dashcamState" 258 "dashcamStorageAvailableMB" 257 "dashcamStorageRecentMB" 256 "dashcamStorageSavedMB" 255 "dashcamStorageSentryMB" 254 "dashcamStorageState" 253 "dashcamTransferCount" 252 "dashcamTransferFileCount" 251 "dashcamTransferRateMBps" 250 "dashcamTransferSizeMB" 249 "dashcamTransferTimeMs" 248 "dashcamviewerCPUUsage" 247 "dashcamviewerMemUsage" 246 "developerMode" 245 "dgpuTemperature" 244 "dmCenterAsilFirmwareStatus" 243 "dmCenterAsilOpenFlag" 242 "dmCenterAsilResumeFlag" 241 "dmCenterAsilShortFlag" 240 "dmCenterBacklightDevExists" 239 "dmCenterBacklightDutyCycle" 238 "dmCenterBacklightFault" 237 "dmCenterBacklightNits" 236 "dmCenterBacklightPowerLevel" 235 "dmCenterConnected" 234 "dmCenterEnabled" 233 "dmCenterLinkCheckOk" 232 "dmCenterMOsdExactCrcCheck" 231 "dmCenterMOsdVideoCrcData" 230 "dmCenterModeSettingStatus" 229 "dmCenterOsdDayNightState" 228 "dmCenterOsdDisplayedState" 227 "dmCenterPowerState" 226 "dmCenterSOsdExactCrcCheck" 225 "dmCenterSOsdVideoCrcData" 224 "dmCenterTouchDeviceExists" 223 "dmCenterTouchIrqCount" 222 "dmGatewayLinkWedged" 221 "dmIcuAsilFirmwareStatus" 220 "dmIcuAsilOpenFlag" 219 "dmIcuAsilResumeFlag" 218 "dmIcuAsilShortFlag" 217 "dmIcuBacklightDevExists" 216 "dmIcuBacklightDutyCycle" 215 "dmIcuBacklightFault" 214 "dmIcuBacklightNits" 213 "dmIcuBacklightPowerLevel" 212 "dmIcuConnected" 211 "dmIcuEnabled" 210 "dmIcuLinkCheckOk" 209 "dmIcuPowerState" 208 "dmIcuTouchIrqCount" 207 "dmRearAsilStatusLsb" 206 "dmRearAsilStatusMsb" 205 "dmRearBacklightDevExists" 204 "dmRearBacklightDutyCycle" 203 "dmRearBacklightFault" 202 "dmRearBacklightNits" 201 "dmRearBacklightPowerLevel" 200 "dmRearConnected" 199 "dmRearEnabled" 198 "dmRearLinkCheckOk" 197 "dmRearPowerState" 196 "dmRearTouchDeviceExists" 195 "dumTclipClipCount" 194 "dumTclipSuccessfulUploadCount" 193 "dumTclipTransferCount" 192 "dumTclipUploadActive" 191 "dumTclipUploadState" 190 "embeddedGameName" 189 "embeddedGameState" 188 "estimatedOccupancyCount" 187 "featureSuperchargingEnabled" 186 "firmwareReleaseScope" 185 "godotCPUUsage" 184 "godotMemUsage" 183 "godot_MEMORY_DYNAMIC" 182 "godot_MEMORY_STATIC" 181 "godot_TIME_FPS" 180 "godot_TIME_PROCESS" 179 "gpsmanagerCPUUsage" 178 "gpsmanagerMemUsage" 177 "gtwSocUartRxStatBadChecksum" 176 "gtwSocUartRxStatBadTooBig" 175 "gtwSocUartRxStatBadTooSmall" 174 "gtwSocUartRxStatHandleErr" 173 "gtwSocUartRxStatHeartbeats" 172 "gtwSocUartRxStatMsgErr" 171 "gtwSocUartRxStatUnhandled" 170 "gtwSocUartRxStatValidPackets" 169 "gtwSocUartTxStatAnsMismatch" 168 "gtwSocUartTxStatBadTooBig" 167 "gtwSocUartTxStatNacks" 166 "gtwSocUartTxStatPackets" 165 "gtwSocUartTxStatTimeouts" 164 "headsetConnectionState" 163 "headsetPairResult" 162 "hermesclientCPUUsage" 161 "hermesclientMemUsage" 160 "hermesdynamicCPUUsage" 159 "hermesdynamicMemUsage" 158 "homelinkState" 157 "igpuTemperature" 156 "inSuperchargerGeofence" 155 "limex8664CPUUsage" 154 "limex8664MemUsage" 153 "mediaImageCacheCost" 152 "mediaImageCacheSize" 151 "mediaNeedAuthToken" 150 "mediaPlaybackStatus" 149 "mediaserveCPUUsage" 148 "mediaserveMemUsage" 147 "mirrorGeofenceActive" 146 "modemBusyActive" 145 "modemECallppAvail" 144 "mounterdDashcamCapacityGB" 143 "mounterdDeviceCount" 142 "mounterdEncryptionCapacityGB" 141 "mounterdFilesystemCountExfat" 140 "mounterdFilesystemCountExt3" 139 "mounterdFilesystemCountExt4" 138 "mounterdFilesystemCountFat32" 137 "mounterdFrontHubConnected" 136 "mounterdFrontHubDisconnected" 135 "mounterdMountCountTotal" 134 "mounterdState" 133 "muteNavVolume" 132 "navAudioVolume" 131 "nuanceserverCPUUsage" 130 "nuanceserverMemUsage" 129 "numCorrMemErrorsECC" 128 "numUncorrMemErrorsECC" 127 "nvmeDataUnitsWritten100mb" 126 "nvmePercentLifetimeUsed" 125 "nvmeTemperature" 124 "odinAuthCount" 123 "odinAuthFailCount" 122 "odinCPUUsage" 121 "odinEcuLogForceTriggerUploadState" 120 "odinEcuLogUploadState" 119 "odinFileSystemState" 118 "odinGatewayConnectionState" 117 "odinHermesConnectionState" 116 "odinHrlLogUploadState" 115 "odinHrlUploadLimits" 114 "odinListTasksCmdDurationMs" 113 "odinListTasksCmdResult" 112 "odinMemUsage" 111 "odinNetworkFailCount" 110 "odinNetworkStartCount" 109 "odinOrchestratorFailCount" 108 "odinOrchestratorStartCount" 107 "odinProcessState" 106 "odinStatusCmdDurationMs" 105 "odinStatusCmdResult" 104 "odincefCPUUsage" 103 "odincefMemUsage" 102 "polytopiax8664CPUUsage" 101 "polytopiax8664MemUsage" 100 "powerManagerState" 99 "psiCpuSome" 98 "psiIOFull" 97 "psiIOSome" 96 "psiMemFull" 95 "psiMemSome" 94 "qtcarCPUUsage" 93 "qtcarMemUsage" 92 "radioserveCPUUsage" 91 "radioserveMemUsage" 90 "rearDisplayState" 89 "rearDisplayUserPresent" 88 "releasenotesCPUUsage" 87 "releasenotesMemUsage" 86 "remoteRequestType" 85 "scheduleChargeEndTime" 84 "scheduleChargeStartTime" 83 "scheduledChargingMode" 82 "sentryIncidentCount" 81 "sentryNeedsNap" 80 "sentryState" 79 "serverCPUUsage" 78 "serverMemUsage" 77 "serviceMode" 76 "serviceModePlus" 75 "settingsAutoTurnSignal" 74 "slackerLoginResult" 73 "sleepCount" 72 "sleepState" 71 "sleepTime" 70 "sleepType" 69 "solitaireCPUUsage" 68 "solitaireMemUsage" 67 "speechrecoCPUUsage" 66 "speechrecoMemUsage" 65 "spotifyserverCPUUsage" 64 "spotifyserverMemUsage" 63 "sudokuCPUUsage" 62 "sudokuMemUsage" 61 "superchargePaymentNeeded" 60 "suspensionGeofence" 59 "systemMemSwapUsage" 58 "systemUptime" 57 "systemWakeTime" 56 "tegraModemManState" 55 "teslaMediaCacheCost" 54 "teslaMediaCacheSize" 53 "teslacefgpuCPUUsage" 52 "teslacefgpuMemUsage" 51 "teslacefzygotCPUUsage" 50 "teslacefzygotMemUsage" 49 "teslachromiumCPUUsage" 48 "teslachromiumMemUsage" 47 "testDriveMode" 46 "tmserverCPUUsage" 45 "tmserverMemUsage" 44 "touchEventsAggCount" 43 "tunerCurrentAntenna1" 42 "tunerCurrentAntenna2" 41 "tunerTemperatureCelsius" 40 "tunerTemperatureFahrenheit" 39 "tunerVoltage1V8" 38 "tunerVoltage3V3" 37 "tunerVoltageAntenna1" 36 "tunerVoltageAntenna2" 35 "tunerVoltageMQS" 34 "tunerVoltageOperation" 33 "tunerVoltageUBatt" 32 "uiFramesOver100Ms" 31 "uiFramesOver200Ms" 30 "uiMaxFrametime" 29 "uiMeanFPS" 28 "uiQtCarSwapUsage" 27 "uiQtCarUptime" 26 "valetMode" 25 "valhallaserverCPUUsage" 24 "valhallaserverMemUsage" 23 "vehicleCPUUsage" 22 "vehicleMemUsage" 21 "videodCPUUsage" 20 "videodMemUsage" 19 "vmtouchCPUUsage" 18 "vmtouchMemUsage" 17 "webbrowserCPUUsage" 16 "webbrowserMemUsage" 15 "wifiAutoJoinLowRSSI" 14 "wifiBars" 13 "wifiStackReady" 12 "wifiStackState" 11 "wifiTemperature" 10 "zramCompressedSize" 9 "zramCompressionRatio" 8 "zramFailedReads" 7 "zramFailedWrites" 6 "zramInvalidIO" 5 "zramNotifyFree" 4 "zramOriginalSize" 3 "zramReadIO" 2 "zramReadTicks" 1 "zramWriteIO" 0 "zramWriteTicks" ;
VAL_ 1056 UIS_wifiStackState 17 "WL_RESET_CONNMAN" 16 "WL_RUNNING_LOCAL" 15 "WL_CAPTIVE" 14 "WL_DISCONNECTING" 13 "WL_RUNNING" 12 "WL_WAITING_ONLINE" 11 "WL_CHECKING" 10 "WL_CONFIGURING" 9 "WL_CONNECTING" 8 "WL_SELECTING_NETWORK" 7 "WL_WAITING_AUTOCONNECT" 6 "WL_SEARCHING" 5 "WL_POWERING_ON" 4 "WL_DISABLED_WAIT" 3 "WL_POWERING_OFF" 2 "WL_WAITING_TECHNOLOGY" 1 "WL_RESETTING" 0 "DEFAULT" ;
VAL_ 1056 UIS_wifiAutoJoinLowRSSI 1 "TRUE" 0 "FALSE" ;
VAL_ 1056 UIS_valetMode 1 "TRUE" 0 "FALSE" ;
VAL_ 1056 UIS_tegraModemManState 20 "INVALID" 19 "CHECKINGMODEM" 18 "CHECKINGPORTS" 17 "STOPPINGLINK" 16 "UNCONFIGURINGLINK" 15 "RUNNINGSTATUS" 14 "RUNNING" 13 "CHECKINGLINK" 12 "CONFIGURINGLINK" 11 "RETRYINGLINK" 10 "STARTINLINK" 9 "PRECONDITIONINGLINK" 8 "INITIALIZING2" 7 "CHECKINGANTENNA" 6 "ENABLINGSIM" 5 "INITIALIZING1" 4 "RECOVERING" 3 "WAKING" 2 "SLEEPING" 1 "RESTARTING" 0 "ABORTINGLINK" ;
VAL_ 1056 UIS_suspensionGeofence 1 "REQUESTED" 0 "REMOVED" ;
VAL_ 1056 UIS_sleepType 4 "Unknown" 3 "ModernStandby" 2 "S2Idle" 1 "S3" 0 "Shallow" ;
VAL_ 1056 UIS_sleepState 3 "Wake" 2 "Sleep" 1 "Run" 0 "Boot" ;
VAL_ 1056 UIS_slackerLoginResult 5000 "SLACKER_LOGIN_CREDENTIALS_MISSING" 444 "SLACKER_LOGIN_USER_BUMPED" 412 "SLACKER_LOGIN_TOKEN_INVALID_TIMESTAMP" 409 "SLACKER_LOGIN_TOKEN_REVOKED_KEY" 403 "SLACKER_LOGIN_CAPTCHA_REQUIRED" 401 "SLACKER_LOGIN_INCORRECT_CREDENTIALS" 400 "SLACKER_LOGIN_TOKEN_INVALID_SIGNATURE" 6 "SLACKER_LOGIN_BAD_ACCOUNT_LEVEL" 5 "SLACKER_LOGIN_OTHER_ERROR" 4 "SLACKER_LOGIN_NET_ERROR" 3 "SLACKER_LOGIN_TOKEN_UNKNOWN_ERROR" 2 "SLACKER_LOGIN_SUCCESS" 1 "SLACKER_LOGIN_SERVERTIME_FAILED" ;
VAL_ 1056 UIS_sentryState 5 "QUIET" 4 "PANIC" 3 "AWARE" 2 "ARMED" 1 "IDLE" 0 "OFF" ;
VAL_ 1056 UIS_scheduledChargingMode 3 "TIME_WINDOW" 2 "END_BY" 1 "START_AT" 0 "OFF" ;
VAL_ 1056 UIS_remoteRequestType 106 "NAV_GPS_DESTINATION_REQUEST" 105 "TESLA_AUTH_RESPONSE" 104 "GET_MESSAGE" 103 "SET_LIGHTBAR_DITCH" 102 "SET_LIGHTBAR_MIDDLE" 101 "SET_LIGHTBAR_BRIGHTNESS" 100 "REMOVE_PRECONDITION_SCHEDULE" 99 "ADD_PRECONDITION_SCHEDULE" 98 "REMOVE_CHARGE_SCHEDULE" 97 "ADD_CHARGE_SCHEDULE" 96 "SET_REAR_ZONE_LIGHT_REQUEST" 95 "SET_FRONT_ZONE_LIGHT_REQUEST" 94 "SET_TENT_MODE_REQUEST" 93 "SET_POWERSHARE_REQUEST" 92 "SET_POWERSHARE_DISCHARGE_LIMIT" 91 "SET_POWERSHARE_FEATURE" 90 "NAVIGATION_WAYPOINTS_REQUEST" 89 "VEHICLE_CONTROL_RESET_PIN_TO_DRIVE_ADMIN" 88 "SET_TRUCK_BED_LIGHT_BRIGHTNESS" 87 "SET_TRUCK_BED_LIGHT_AUTO_STATE" 86 "SET_TRAILER_LIGHT_TEST_START_STOP" 85 "SET_POWER_FEED_SOC_LIMIT" 84 "SET_POWER_FEED_TIMER" 83 "SET_POWER_FEED_ON_OFF" 82 "SET_OUTLET_SOC_LIMIT" 81 "SET_OUTLET_TIMER" 80 "SET_OUTLETS_ON_OFF" 79 "DRIVING_CLEAR_SPEED_LIMIT_PIN_ADMIN" 78 "VEHICLE_CONTROL_RESET_PIN_TO_DRIVE" 77 "VEHICLE_CONTROL_SET_PIN_TO_DRIVE" 76 "RESERVED_SEVENTY_SIX" 75 "GET_CHARGE_ON_SOLAR_FEATURE" 74 "UPDATE_CHARGE_ON_SOLAR_FEATURE" 73 "GET_MANAGED_CHARGING_SITES" 72 "ERASE_USER_DATA" 71 "STW_HEAT_LEVEL" 70 "AUTO_STW_HEAT" 69 "NAVIGATION_ROUTE" 68 "REMOVE_MANAGED_CHARGING_SITE" 67 "ADD_MANAGED_CHARGING_SITE" 66 "SET_COP_TEMP" 65 "GUEST_MODE" 64 "BOOMBOX" 63 "BLUETOOTH_CLASSIC_PAIRING_REQUEST" 62 "CHARGE_PORT_DOOR_OPEN" 61 "CHARGE_PORT_DOOR_CLOSE" 60 "RESERVED_SIXTY" 59 "RESERVED_FIFTY_NINE" 58 "TAKE_DRIVENOTE" 57 "VIDEO_REQUEST" 56 "GET_RATE_TARIFF" 55 "RESERVED_FIFTY_FIVE" 54 "SET_VEHICLE_NAME" 53 "NAVIGATION_GPS_REQUEST" 52 "PSEUDONYM_SYNC_REQUEST" 51 "PII_KEY_REQUEST" 50 "SET_CABIN_OVERHEAT_PROTECTION" 49 "HVAC_SEAT_COOLER_ACTIONS" 48 "AUTO_SEAT_CLIMATE" 47 "DASHCAM_SAVE_CLIP" 46 "PING" 45 "HVAC_RECIRCULATION" 44 "HVAC_CLIMATE_KEEPER" 43 "SET_CHARGING_AMPS" 42 "SCHEDULED_DEPARTURE" 41 "SCHEDULED_CHARGING" 40 "VITALS_ACK" 39 "VITALS_SUBSCRIPTION" 38 "VEHICLE_DATA_ACK" 37 "VEHICLE_DATA_SUBSCRIPTION" 36 "HVAC_SEAT_HEATER_ACTIONS" 35 "HVAC_BIO_WEAPON_MODE" 34 "VEHICLE_CONTROL_WINDOW" 33 "VEHICLE_CONTROL_TRIGGER_HOMELINK" 32 "VEHICLE_CONTROL_SUNROOF_OPEN_CLOSE" 31 "VEHICLE_CONTROL_SET_VALET_MODE" 30 "VEHICLE_CONTROL_SET_SENTRY_MODE" 29 "VEHICLE_CONTROL_SCHEDULE_SOFTWARE_UPDATE" 28 "VEHICLE_CONTROL_RESET_VALET_PIN" 27 "VEHICLE_CONTROL_HONK_HORN" 26 "VEHICLE_CONTROL_FLASH_LIGHTS" 25 "VEHICLE_CONTROL_CANCEL_SOFTWARE_UPDATE" 24 "UI_SET_UPCOMING_CALENDAR_ENTRIES" 23 "GET_NEARBY_CHARGING_SITES" 22 "NAVIGATION_SUPERCHARGER_REQUEST" 21 "NAVIGATION_REQUEST" 20 "MEDIA_PREVIOUS_TRACK" 19 "MEDIA_NEXT_TRACK" 18 "MEDIA_PREVIOUS_FAVORITE" 17 "MEDIA_NEXT_FAVORITE" 16 "MEDIA_UPDATE_VOLUME" 15 "MEDIA_PLAY" 14 "HVAC_TEMPERATURE_ADJUSTMENT" 13 "HVAC_STEERING_WHEEL_HEATER" 12 "HVAC_SET_PRECONDITIONING_MAX" 11 "RESERVED_ELEVEN" 10 "HVAC_AUTO" 9 "DRIVING_SPEED_LIMIT" 8 "DRIVING_SET_SPEED_LIMIT" 7 "DRIVING_CLEAR_SPEED_LIMIT_PIN" 6 "CHARGING_START_STOP" 5 "CHARGING_SET_LIMIT" 4 "STREAM_MESSAGE" 3 "CREATE_STREAM_SESSION" 2 "REMOTE_START_DRIVE" 1 "GET_VEHICLE_DATA" 0 "UNKNOWN" ;
VAL_ 1056 UIS_rearDisplayUserPresent 1 "TRUE" 0 "FALSE" ;
VAL_ 1056 UIS_rearDisplayState 9 "ENTERTAINMENT" 8 "DOG" 7 "SENTRY" 6 "LOCK" 5 "CHARGING" 4 "DRIVING" 3 "ON" 2 "ACCESSORY" 1 "DIM" 0 "OFF" ;
VAL_ 1056 UIS_powerManagerState 31 "PMS_ENTERINGROBOTAXILOADSHED" 30 "PMS_ROBOTAXILOADSHEDDING" 29 "PMS_UPLOADDATA" 28 "PMS_EXTREMELOADSHEDDING" 27 "PMS_ENTERINGEXTREMELOADSHED" 26 "PMS_PREPARINGSLEEP" 25 "PMS_ENTERINGLOADSHED" 24 "PMS_SENTRYACTIVE" 23 "PMS_EXITINGLOADSHED" 22 "PMS_LOADSHEDDING" 21 "PMS_EXITINGSENTRY" 20 "PMS_SENTRYARMED" 19 "PMS_ENTERINGSENTRY" 18 "PMS_UNKNOWN_SNA" 17 "PMS_EXITINGSLEEP" 16 "PMS_READYFORSLEEP" 15 "PMS_WAITINGONRAILS" 14 "PMS_PERFORMANCE" 13 "PMS_HIGHPOWERSTARTED" 12 "PMS_HIGHPOWERSTOPPING" 11 "PMS_HIGHPOWERSTARTING" 10 "PMS_REBOOT" 9 "PMS_ENTERINGSLEEP" 8 "PMS_ALLTUCKEDIN" 7 "PMS_CHARGING" 6 "PMS_AUDIOSTOPPED" 5 "PMS_AUDIOSTOPPING" 4 "PMS_POWERBROWNOUT" 3 "PMS_AUDIOSTARTING" 2 "PMS_ACCDELAY" 1 "PMS_FULLPOWER" 0 "PMS_CHECKING" ;
VAL_ 1056 UIS_modemECallppAvail 1 "ENABLED" 0 "DISABLED" ;
VAL_ 1056 UIS_modemBusyActive 1 "RUNNING" 0 "OFF" ;
VAL_ 1056 UIS_mirrorGeofenceActive 1 "TRUE" 0 "FALSE" ;
VAL_ 1056 UIS_mediaPlaybackStatus 2 "PAUSED" 1 "PLAYING" 0 "STOPPED" ;
VAL_ 1056 UIS_mediaNeedAuthToken 1 "TRUE" 0 "FALSE" ;
VAL_ 1056 UIS_inSuperchargerGeofence 1 "TRUE" 0 "FALSE" ;
VAL_ 1056 UIS_homelinkState 23 "HW_ERROR" 22 "UNIVERSAL_RECEIVER_ERROR" 21 "UNIVERSAL_RECEIVER_SUCCESS" 20 "UNIVERSAL_RECEIVER_WAIT" 19 "DEFAULT_FAIL" 18 "DEFAULT_SUCCESS" 17 "DEFAULT_WAIT" 16 "STANDARD_FAIL" 15 "STANDARD_SUCCESS" 14 "STANDARD_WAIT" 13 "CLEAR_FAIL" 12 "CLEAR_SUCCESS" 11 "CLEAR_WAIT" 10 "TIMEOUT" 9 "LEARN_FAIL" 8 "LEARN_CANCLE" 7 "LEARN_SUCCESS_NOT_ROLLING" 6 "LEARN_SUCCESS_ROLLING" 5 "LEARN_TEST" 4 "LEARN_SUCCESS" 3 "LEARN_WAIT" 2 "PROGRAM_WAIT" 1 "TRANSMITTING" 0 "IDLE" ;
VAL_ 1056 UIS_headsetPairResult 23 "HID_PAIRED" 22 "HID_MAX_NR_OF_CONNS" 21 "HID_PAGE_TIMEOUT" 20 "HID_OETC_USER" 19 "HID_REJ_BY_REMOTE_NO_RES" 18 "HID_LMP_RESPONSE_TIMEOUT" 17 "HID_AUTH_FAILURE" 16 "HID_KEY_MISSING" 15 "HID_NO_RESPONSE" 14 "HID_ALREADY_REQUESTED_BY_REMOTE" 13 "HID_UNKNOWN" 12 "HID_UNPAIRED" 11 "PAIRED" 10 "MAX_NR_OF_CONNS" 9 "PAGE_TIMEOUT" 8 "OETC_USER" 7 "REJ_BY_REMOTE_NO_RES" 6 "LMP_RESPONSE_TIMEOUT" 5 "AUTH_FAILURE" 4 "KEY_MISSING" 3 "NO_RESPONSE" 2 "ALREADY_REQUESTED_BY_REMOTE" 1 "UNKNOWN" 0 "UNPAIRED" ;
VAL_ 1056 UIS_headsetConnectionState 77 "HID_ERROR_UNKNOWN" 76 "HID_ERROR_ANTENNA_DISCONNECTED" 75 "HID_CONNECTED" 74 "HID_CONNECT_CANCELLED" 73 "HID_CONNECT_PROFILE_UNAVAILABLE" 72 "HID_CONNECT_INVALID_ARGUMENT" 71 "HID_CONNECT_ADAPTER_OFF" 70 "HID_CONNECT_NOT_SUPPORTED" 69 "HID_CONNECT_ALREADY_CONN" 68 "HID_CONNECT_DEVICE_NOT_FOUND_NO_RESOURCES" 67 "HID_CONNECT_DEVICE_NOT_FOUND_PAGE_TIMEOUT" 66 "HID_CONNECT_DEVICE_NOT_FOUND" 65 "HID_CONNECT_FAILED_REMOTE_TERMINATED" 64 "HID_CONNECT_FAILED_NO_RESOURCES" 63 "HID_CONNECT_FAILED_CONNECTION_TIMEOUT" 62 "HID_CONNECT_FAILED" 61 "HID_CONNECT_SDP_FAILURE" 60 "HID_CONNECT_PIN_MISSING" 59 "HID_CONNECT_PAGE_TIMEOUT" 58 "HID_CONNECT_REJ_BY_REMOTE_NO_RES" 57 "HID_CONNECT_MAX_NR_OF_CONNS" 56 "HID_CONNECT_CONTROLLER_BUSY" 55 "HID_CONNECT_CONN_TIMEOUT" 54 "HID_CONNECT_MAX_NR_OF_ACL" 53 "HID_CONNECT_LMP_RESPONSE_TIMEOUT" 52 "HID_CONNECT_HOST_TIMEOUT" 51 "HID_CONNECT_UNKNOWN_FAILURE" 50 "HID_DISCONNECT_UNKNOWN" 49 "HID_DISCONNECT_OETC_POWERING_OFF" 48 "HID_DISCONNECT_OETC_LOW_RESOURCE" 47 "HID_DISCONNECT_REJ_BY_REMOTE_SEC" 46 "HID_DISCONNECT_AUTH_FAIL" 45 "HID_DISCONNECT_LMP_RESPONSE_TIMEOUT" 44 "HID_DISCONNECT_OETC_USER" 43 "HID_DISCONNECT_CONN_TIMEOUT" 42 "HID_DISCONNECT_CONN_TERM_LOCAL_HOST" 41 "HID_DISCONNECT_LINKLOSS" 40 "HID_DISCONNECT_FROM_REMOTE" 39 "HID_DISCONNECTED" 38 "ERROR_UNKNOWN" 37 "ERROR_ANTENNA_DISCONNECTED" 36 "CONNECTED" 35 "CONNECT_CANCELLED" 34 "CONNECT_PROFILE_UNAVAILABLE" 33 "CONNECT_INVALID_ARGUMENT" 32 "CONNECT_ADAPTER_OFF" 31 "CONNECT_NOT_SUPPORTED" 30 "CONNECT_ALREADY_CONN" 29 "CONNECT_DEVICE_NOT_FOUND_NO_RESOURCES" 28 "CONNECT_DEVICE_NOT_FOUND_PAGE_TIMEOUT" 27 "CONNECT_DEVICE_NOT_FOUND" 26 "CONNECT_FAILED_REMOTE_TERMINATED" 25 "CONNECT_FAILED_NO_RESOURCES" 24 "CONNECT_FAILED_CONNECTION_TIMEOUT" 23 "CONNECT_FAILED" 22 "CONNECT_SDP_FAILURE" 21 "CONNECT_PIN_MISSING" 20 "CONNECT_PAGE_TIMEOUT" 19 "CONNECT_REJ_BY_REMOTE_NO_RES" 18 "CONNECT_MAX_NR_OF_CONNS" 17 "CONNECT_CONTROLLER_BUSY" 16 "CONNECT_CONN_TIMEOUT" 15 "CONNECT_MAX_NR_OF_ACL" 14 "CONNECT_LMP_RESPONSE_TIMEOUT" 13 "CONNECT_HOST_TIMEOUT" 12 "CONNECT_UNKNOWN_FAILURE" 11 "DISCONNECT_UNKNOWN" 10 "DISCONNECT_OETC_POWERING_OFF" 9 "DISCONNECT_OETC_LOW_RESOURCE" 8 "DISCONNECT_REJ_BY_REMOTE_SEC" 7 "DISCONNECT_AUTH_FAIL" 6 "DISCONNECT_LMP_RESPONSE_TIMEOUT" 5 "DISCONNECT_OETC_USER" 4 "DISCONNECT_CONN_TIMEOUT" 3 "DISCONNECT_CONN_TERM_LOCAL_HOST" 2 "DISCONNECT_LINKLOSS" 1 "DISCONNECT_FROM_REMOTE" 0 "DISCONNECTED" ;
VAL_ 1056 UIS_dmRearPowerState 1 "ON" 0 "OFF" ;
VAL_ 1056 UIS_dmRearLinkCheckOk 1 "PASSED" 0 "FAILED" ;
VAL_ 1056 UIS_dmRearBacklightDevExists 1 "PASSED" 0 "FAILED" ;
VAL_ 1056 UIS_dmIcuPowerState 1 "ON" 0 "OFF" ;
VAL_ 1056 UIS_dmIcuLinkCheckOk 1 "PASSED" 0 "FAILED" ;
VAL_ 1056 UIS_dmIcuBacklightDevExists 1 "PASSED" 0 "FAILED" ;
VAL_ 1056 UIS_dmCenterPowerState 1 "ON" 0 "OFF" ;
VAL_ 1056 UIS_dmCenterOsdDisplayedState 1 "SHOWING" 0 "HIDDEN" ;
VAL_ 1056 UIS_dmCenterLinkCheckOk 1 "PASSED" 0 "FAILED" ;
VAL_ 1056 UIS_dmCenterBacklightPowerLevel 2 "HIGH_POWER" 1 "LOW_POWER" 0 "OFF" ;
VAL_ 1056 UIS_dmCenterBacklightDevExists 1 "PASSED" 0 "FAILED" ;
VAL_ 1056 UIS_dashcamStorageState 8 "RECENT_BUFFER_DURATION_REDUCED" 7 "SLOW" 6 "READ_ONLY" 5 "FULL" 4 "GETTING_FULL" 3 "ERROR" 2 "READY" 1 "REMOVED" 0 "INVALID" ;
VAL_ 1056 UIS_dashcamState 7 "STREAMING" 6 "SAVING" 5 "PAUSED" 4 "RECORDING" 3 "STOPPED" 2 "ERROR" 1 "TERMINATED" 0 "INVALID" ;
VAL_ 1056 UIS_clusterDisplayState 9 "ENTERTAINMENT" 8 "DOG" 7 "SENTRY" 6 "LOCK" 5 "CHARGING" 4 "DRIVING" 3 "ON" 2 "ACCESSORY" 1 "DIM" 0 "OFF" ;
VAL_ 1056 UIS_chargeOnSolarNoChargeReason 3 "ALTERNATIVE_VEHICLE_CHARGE_PRIORITY" 2 "GRID_EXPORT_PRIORITY" 1 "POWERWALL_CHRAGE_PRIORITY" 0 "INSUFFICIENT_SOLAR" ;
VAL_ 1056 UIS_centerDisplayState 9 "ENTERTAINMENT" 8 "DOG" 7 "SENTRY" 6 "LOCK" 5 "CHARGING" 4 "DRIVING" 3 "ON" 2 "ACCESSORY" 1 "DIM" 0 "OFF" ;
VAL_ 1056 UIS_centerDisplayEvent 21 "CPD_TRIGGERED" 20 "CAR_LOCKED" 19 "ENTERTAINMENT_OFF" 18 "ALL_STATES_EXCEPT_ENTERTAINMENT_TURNED_ON" 17 "IC_HAZARDS_OFF_DOOR_CLOSED_NO_OCCUPANTS" 16 "IC_HAZARDS_ON" 15 "ALL_DOORS_CLOSED_NO_OCCUPANTS_CHARGE_ACTIVE" 14 "TIMEOUT" 13 "DOOR_HANDLE_PULLED" 12 "ALL_STATES_EXCEPT_SENTRY" 11 "SENTRY_PANIC_ENDED" 10 "POWER_OFF_REQUEST" 9 "DRIVE_RAIL_OFF_NO_DRIVER_PRESENT" 8 "DRIVE_RAIL_OFF_DOOR_OPEN" 7 "DRIVE_RAIL_OFF_DRIVE_PRESENT" 6 "POWER_ON_REQUEST" 5 "DOOR_OPENED" 4 "ALL_STATES_EXCEPT_ENTERTAINMENT_DRIVE_RAIL_TURNED_ON" 3 "ALL_DOORS_CLOSED_NO_OCCUPANTS" 2 "PASSED_SPEED_THRESHOLD" 1 "SHIFTED_P_TO_N" 0 "OTHER" ;
VAL_ 1056 UIS_cellularLinkManagerState 16 "INVALID" 15 "RUNNING" 14 "DISCONNECTING" 13 "ROAMINGDISALLOWED" 12 "ENTERINGAIRPLANEMODE" 11 "CHECKING" 10 "RETRYING" 9 "CONFIGURING" 8 "CONNECTING" 7 "OFONOMODEMRELOADING" 6 "SEARCHING" 5 "CONFIGURINGAPN" 4 "QUERYDIAGNOSTIC" 3 "STARTING" 2 "UPDATING" 1 "RESETTING" 0 "RECOVERING" ;
VAL_ 1056 UIS_carAssistState 5 "GROK" 4 "DICTATION" 3 "COMMAND" 2 "ERROR" 1 "IDLE" 0 "DISABLED" ;
VAL_ 1056 UIS_carAssistErrorCode 17 "CLIENT_LOGGED_OUT_TOKEN_EXPIRED" 16 "CLIENT_PROVIDER_RATE_LIMTED" 15 "CLIENT_PROVIDER_AT_CAPACITY" 14 "CLIENT_ANON_USAGE_LIMITED" 13 "CLIENT_PREM_CONN" 12 "CLIENT_SPEECH" 11 "CLIENT_REMOTE" 10 "CLIENT_DBUS" 9 "CLIENT_DISCONNECTED" 8 "CLIENT_CONNECTIVITY" 7 "CLIENT_AUDIO" 6 "CLIENT_ERROR" 5 "COMMAND_NOT_IMPLEMENTED" 4 "COMMAND_NOT_AVAILABLE" 3 "COMMAND_NOT_UNDERSTOOD" 2 "REMOTE_ERROR" 1 "REMOTE_UNKNOWN" 0 "NONE" ;
VAL_ 1056 UIS_cameraRRepeaterStreamMissing 1 "MISSING" 0 "ACTIVE" ;
VAL_ 1056 UIS_cameraRRepeaterPopup 1 "OPEN" 0 "CLOSED" ;
VAL_ 1056 UIS_cameraRRepeaterPipeline 4 "PLAYING" 3 "PAUSED" 2 "READY" 1 "NULL" 0 "SLEEP" ;
VAL_ 1056 UIS_cameraLRepeaterStreamMissing 1 "MISSING" 0 "ACTIVE" ;
VAL_ 1056 UIS_cameraLRepeaterPopup 1 "OPEN" 0 "CLOSED" ;
VAL_ 1056 UIS_cameraLRepeaterPipeline 4 "PLAYING" 3 "PAUSED" 2 "READY" 1 "NULL" 0 "SLEEP" ;
VAL_ 1056 UIS_cameraBackupStreamMissing 1 "MISSING" 0 "ACTIVE" ;
VAL_ 1056 UIS_cameraBackupPopup 1 "OPEN" 0 "CLOSED" ;
VAL_ 1056 UIS_cameraBackupPipeline 4 "PLAYING" 3 "PAUSED" 2 "READY" 1 "NULL" 0 "SLEEP" ;
VAL_ 1056 UIS_bluetoothStackState 4 "ON_BLUEZ" 3 "ON_SYNERGY" 2 "ON_LGIT" 1 "ON" 0 "OFF" ;
VAL_ 1056 UIS_bluetoothStackRearState 4 "ON_BLUEZ" 3 "ON_SYNERGY" 2 "ON_LGIT" 1 "ON" 0 "OFF" ;
VAL_ 1056 UIS_bluetoothPairResult 23 "HID_PAIRED" 22 "HID_MAX_NR_OF_CONNS" 21 "HID_PAGE_TIMEOUT" 20 "HID_OETC_USER" 19 "HID_REJ_BY_REMOTE_NO_RES" 18 "HID_LMP_RESPONSE_TIMEOUT" 17 "HID_AUTH_FAILURE" 16 "HID_KEY_MISSING" 15 "HID_NO_RESPONSE" 14 "HID_ALREADY_REQUESTED_BY_REMOTE" 13 "HID_UNKNOWN" 12 "HID_UNPAIRED" 11 "PAIRED" 10 "MAX_NR_OF_CONNS" 9 "PAGE_TIMEOUT" 8 "OETC_USER" 7 "REJ_BY_REMOTE_NO_RES" 6 "LMP_RESPONSE_TIMEOUT" 5 "AUTH_FAILURE" 4 "KEY_MISSING" 3 "NO_RESPONSE" 2 "ALREADY_REQUESTED_BY_REMOTE" 1 "UNKNOWN" 0 "UNPAIRED" ;
VAL_ 1056 UIS_bluetoothConnectionState 77 "HID_ERROR_UNKNOWN" 76 "HID_ERROR_ANTENNA_DISCONNECTED" 75 "HID_CONNECTED" 74 "HID_CONNECT_CANCELLED" 73 "HID_CONNECT_PROFILE_UNAVAILABLE" 72 "HID_CONNECT_INVALID_ARGUMENT" 71 "HID_CONNECT_ADAPTER_OFF" 70 "HID_CONNECT_NOT_SUPPORTED" 69 "HID_CONNECT_ALREADY_CONN" 68 "HID_CONNECT_DEVICE_NOT_FOUND_NO_RESOURCES" 67 "HID_CONNECT_DEVICE_NOT_FOUND_PAGE_TIMEOUT" 66 "HID_CONNECT_DEVICE_NOT_FOUND" 65 "HID_CONNECT_FAILED_REMOTE_TERMINATED" 64 "HID_CONNECT_FAILED_NO_RESOURCES" 63 "HID_CONNECT_FAILED_CONNECTION_TIMEOUT" 62 "HID_CONNECT_FAILED" 61 "HID_CONNECT_SDP_FAILURE" 60 "HID_CONNECT_PIN_MISSING" 59 "HID_CONNECT_PAGE_TIMEOUT" 58 "HID_CONNECT_REJ_BY_REMOTE_NO_RES" 57 "HID_CONNECT_MAX_NR_OF_CONNS" 56 "HID_CONNECT_CONTROLLER_BUSY" 55 "HID_CONNECT_CONN_TIMEOUT" 54 "HID_CONNECT_MAX_NR_OF_ACL" 53 "HID_CONNECT_LMP_RESPONSE_TIMEOUT" 52 "HID_CONNECT_HOST_TIMEOUT" 51 "HID_CONNECT_UNKNOWN_FAILURE" 50 "HID_DISCONNECT_UNKNOWN" 49 "HID_DISCONNECT_OETC_POWERING_OFF" 48 "HID_DISCONNECT_OETC_LOW_RESOURCE" 47 "HID_DISCONNECT_REJ_BY_REMOTE_SEC" 46 "HID_DISCONNECT_AUTH_FAIL" 45 "HID_DISCONNECT_LMP_RESPONSE_TIMEOUT" 44 "HID_DISCONNECT_OETC_USER" 43 "HID_DISCONNECT_CONN_TIMEOUT" 42 "HID_DISCONNECT_CONN_TERM_LOCAL_HOST" 41 "HID_DISCONNECT_LINKLOSS" 40 "HID_DISCONNECT_FROM_REMOTE" 39 "HID_DISCONNECTED" 38 "ERROR_UNKNOWN" 37 "ERROR_ANTENNA_DISCONNECTED" 36 "CONNECTED" 35 "CONNECT_CANCELLED" 34 "CONNECT_PROFILE_UNAVAILABLE" 33 "CONNECT_INVALID_ARGUMENT" 32 "CONNECT_ADAPTER_OFF" 31 "CONNECT_NOT_SUPPORTED" 30 "CONNECT_ALREADY_CONN" 29 "CONNECT_DEVICE_NOT_FOUND_NO_RESOURCES" 28 "CONNECT_DEVICE_NOT_FOUND_PAGE_TIMEOUT" 27 "CONNECT_DEVICE_NOT_FOUND" 26 "CONNECT_FAILED_REMOTE_TERMINATED" 25 "CONNECT_FAILED_NO_RESOURCES" 24 "CONNECT_FAILED_CONNECTION_TIMEOUT" 23 "CONNECT_FAILED" 22 "CONNECT_SDP_FAILURE" 21 "CONNECT_PIN_MISSING" 20 "CONNECT_PAGE_TIMEOUT" 19 "CONNECT_REJ_BY_REMOTE_NO_RES" 18 "CONNECT_MAX_NR_OF_CONNS" 17 "CONNECT_CONTROLLER_BUSY" 16 "CONNECT_CONN_TIMEOUT" 15 "CONNECT_MAX_NR_OF_ACL" 14 "CONNECT_LMP_RESPONSE_TIMEOUT" 13 "CONNECT_HOST_TIMEOUT" 12 "CONNECT_UNKNOWN_FAILURE" 11 "DISCONNECT_UNKNOWN" 10 "DISCONNECT_OETC_POWERING_OFF" 9 "DISCONNECT_OETC_LOW_RESOURCE" 8 "DISCONNECT_REJ_BY_REMOTE_SEC" 7 "DISCONNECT_AUTH_FAIL" 6 "DISCONNECT_LMP_RESPONSE_TIMEOUT" 5 "DISCONNECT_OETC_USER" 4 "DISCONNECT_CONN_TIMEOUT" 3 "DISCONNECT_CONN_TERM_LOCAL_HOST" 2 "DISCONNECT_LINKLOSS" 1 "DISCONNECT_FROM_REMOTE" 0 "DISCONNECTED" ;
VAL_ 1056 UIS_bluetoothAutoConnectionState 3 "MANUAL_CONNECT_REQUESTED" 2 "GAVE_UP" 1 "CONNECTED" 0 "IDLE" ;
VAL_ 1056 UIS_audioType 4 "BASE_WITH_PREMIUM200" 3 "PREMIUM" 2 "BASE" 1 "NO_A2B" 0 "INVALID" ;
VAL_ 1056 UIS_audioState 7 "SLEEPING" 6 "AUDIO_NOT_PUMPING" 5 "A2B_REDISCOVERY" 4 "HFP_PUMPING" 3 "AUDIO_PUMPING" 2 "UNINITIALIZING" 1 "INITIALIZING" 0 "TERMINATED" ;
VAL_ 1056 UIS_audioSource 5 "NONE" 4 "PHONE_RX" 3 "BLUETOOTH" 2 "MICROPHONE" 1 "TUNER" 0 "MEDIA" ;
VAL_ 1056 UIS_audioMediaPlaying 39 "SODA_MUSIC" 38 "CARAOKE" 37 "KUGOU" 36 "YOUTUBE_MUSIC" 35 "YUNTING" 34 "AMAZON_MUSIC" 33 "AUDIBLE" 32 "APPLE_PODCASTS" 31 "APPLE_MUSIC" 30 "MINI_PROGRAMS" 29 "SEARCH" 28 "HOME_APPS" 27 "RECENTS_FAVORITES" 26 "TOYBOX" 25 "TUTORIAL" 24 "THEATER" 23 "BROWSER" 22 "GAME" 21 "NET_EASE_MUSIC" 20 "ONLINE_RADIO" 19 "XIMALAYA" 18 "QQ_MUSIC2" 17 "QQ_MUSIC1" 16 "TIDAL" 15 "SIRIUS_XM" 14 "STINGRAY" 13 "TUNE_IN" 12 "EU_RADIO" 11 "US_RADIO" 10 "SPOTIFY" 9 "SLACKER" 8 "BLUETOOTH" 7 "USB" 6 "DAB" 5 "XM" 4 "FM" 3 "AM" 2 "UNKNOWN" 1 "DEPRECATED" 0 "NONE" ;
VAL_ 1056 UIS_audioMediaBrowsing 39 "SODA_MUSIC" 38 "CARAOKE" 37 "KUGOU" 36 "YOUTUBE_MUSIC" 35 "YUNTING" 34 "AMAZON_MUSIC" 33 "AUDIBLE" 32 "APPLE_PODCASTS" 31 "APPLE_MUSIC" 30 "MINI_PROGRAMS" 29 "SEARCH" 28 "HOME_APPS" 27 "RECENTS_FAVORITES" 26 "TOYBOX" 25 "TUTORIAL" 24 "THEATER" 23 "BROWSER" 22 "GAME" 21 "NET_EASE_MUSIC" 20 "ONLINE_RADIO" 19 "XIMALAYA" 18 "QQ_MUSIC2" 17 "QQ_MUSIC1" 16 "TIDAL" 15 "SIRIUS_XM" 14 "STINGRAY" 13 "TUNE_IN" 12 "EU_RADIO" 11 "US_RADIO" 10 "SPOTIFY" 9 "SLACKER" 8 "BLUETOOTH" 7 "USB" 6 "DAB" 5 "XM" 4 "FM" 3 "AM" 2 "UNKNOWN" 1 "DEPRECATED" 0 "NONE" ;
VAL_ 1056 UIS_activeAppView 67 "SODA_MUSIC" 66 "HICAR" 65 "CARAOKE_WEB" 64 "KUGOU" 63 "YOUTUBE_MUSIC" 62 "YUNTING" 61 "ONLINE_RADIO" 60 "AMAZON_MUSIC" 59 "AUDIBLE" 58 "APPLE_PODCASTS" 57 "ONBOARDING_MANUAL" 56 "APPLE_MUSIC" 55 "ZOOM" 54 "MINI_PROGRAMS" 53 "CADMIUM" 52 "MESSAGES" 51 "NAV_MEDIA" 50 "BACKGAMMON" 49 "SKETCH_PAD" 48 "ARCADE" 47 "XIMALAYA" 46 "BLUETOOTH" 45 "CHESS" 44 "NETEASE" 43 "OWNERS_MANUAL" 42 "QQMUSIC" 41 "RELEASE_NOTES" 40 "SONIC" 39 "USB" 38 "THEATER" 37 "TIDAL" 36 "TUNEIN" 35 "CARAOKE" 34 "STREAMING" 33 "RADIO" 32 "SPOTIFY" 31 "CAMERA" 30 "CHARGE" 29 "MEDIA" 28 "ENTERTAINMENT" 27 "WEB" 26 "CALENDAR" 25 "TOYBOX" 24 "PHONE" 23 "ENERGY" 22 "TUTORIAL" 21 "CERULEAN" 20 "TOPAZ" 19 "DASHCAM" 18 "CARBONADO" 17 "THEATERVIEW" 16 "MAMBU" 15 "COBALT" 14 "TESLATARI" 13 "SERVICE_APPS" 12 "LIME" 11 "TEARDROP" 10 "NAV" 9 "PURPLE" 8 "CALICO" 7 "CARWASH" 6 "2048" 5 "CONTROLS" 4 "COLORIZER" 3 "XM" 2 "DEVELOPMENT" 1 "NONE" 0 "UNKNOWN" ;
VAL_ 979 UI_airbagCutoffSwState 2 "SNA" 1 "PASSENGER_AIRBAG_OFF" 0 "PASSENGER_AIRBAG_ON" ;
VAL_ 1279 UI_energyConsumptionInfoIndex 21 "21" 20 "20" 19 "19" 18 "18" 17 "17" 16 "16" 15 "15" 14 "14" 13 "13" 12 "12" 11 "11" 10 "10" 9 "9" 8 "8" 7 "7" 6 "6" 5 "5" 4 "4" 3 "3" 2 "2" 1 "1" 0 "0" ;
VAL_ 563 UI_gearRequest 4 "GEAR_REQUEST_DRIVE" 3 "GEAR_REQUEST_NEUTRAL" 2 "GEAR_REQUEST_REVERSE" 1 "GEAR_REQUEST_PARK" 0 "GEAR_REQUEST_IDLE_SNA" ;
VAL_ 661 UI_systemMonitorIndex 1 "1" 0 "0" ;
VAL_ 139 UI_maxSpeedToReachDestination 65535 "SNA" 65534 "UNREACHABLE" 65533 "MAXVAL" ;
VAL_ 139 UI_timeToDestination 65535 "SNA" 65534 "MAXVAL" ;
VAL_ 1173 UI_predictedEnergy -32767 "TRIP_TOO_LONG" -32768 "SNA" ;
VAL_ 1173 UI_hindsightEnergy -32767 "TRIP_TOO_LONG" -32768 "SNA" ;
